VERSION "eCMP INFO-DIV vehicle review 2026-11-03; 125000 bit/s; PSA-RE 67f7581e7622410efdbb29c7eda3b86982b9b450; Apache-2.0"

NS_ :

BS_:

BU_: AAS AMPLI AVP BCM BGP BSG BSI BTA BTEL BTT CDC CMB CRT DIAG_TOOL EDP_C EMF FMUX IC ICSV IDVR IVC_D MATT MDS OVIP PDS_C RAD RBG SDCM VTH WLC

BO_ 438 MDS_Wifi: 8 MDS
 SG_ FlowPadding5 m3 : 63|8@0+ (1,0) [0|255] "raw"  EMF,BTEL,OVIP
 SG_ FirstData6 m1 : 63|8@0+ (1,0) [0|255] "raw"  EMF,BTEL,OVIP
 SG_ UnknownData7 m4 : 63|8@0+ (1,0) [0|255] "raw"  EMF,BTEL,OVIP
 SG_ ConsecutiveData7 m2 : 63|8@0+ (1,0) [0|255] "raw"  EMF,BTEL,OVIP
 SG_ SingleData7 m0 : 63|8@0+ (1,0) [0|255] "raw"  EMF,BTEL,OVIP
 SG_ FlowPadding4 m3 : 55|8@0+ (1,0) [0|255] "raw"  EMF,BTEL,OVIP
 SG_ FirstData5 m1 : 55|8@0+ (1,0) [0|255] "raw"  EMF,BTEL,OVIP
 SG_ UnknownData6 m4 : 55|8@0+ (1,0) [0|255] "raw"  EMF,BTEL,OVIP
 SG_ ConsecutiveData6 m2 : 55|8@0+ (1,0) [0|255] "raw"  EMF,BTEL,OVIP
 SG_ SingleData6 m0 : 55|8@0+ (1,0) [0|255] "raw"  EMF,BTEL,OVIP
 SG_ FlowPadding3 m3 : 47|8@0+ (1,0) [0|255] "raw"  EMF,BTEL,OVIP
 SG_ FirstData4 m1 : 47|8@0+ (1,0) [0|255] "raw"  EMF,BTEL,OVIP
 SG_ UnknownData5 m4 : 47|8@0+ (1,0) [0|255] "raw"  EMF,BTEL,OVIP
 SG_ ConsecutiveData5 m2 : 47|8@0+ (1,0) [0|255] "raw"  EMF,BTEL,OVIP
 SG_ SingleData5 m0 : 47|8@0+ (1,0) [0|255] "raw"  EMF,BTEL,OVIP
 SG_ FlowPadding2 m3 : 39|8@0+ (1,0) [0|255] "raw"  EMF,BTEL,OVIP
 SG_ FirstData3 m1 : 39|8@0+ (1,0) [0|255] "raw"  EMF,BTEL,OVIP
 SG_ UnknownData4 m4 : 39|8@0+ (1,0) [0|255] "raw"  EMF,BTEL,OVIP
 SG_ ConsecutiveData4 m2 : 39|8@0+ (1,0) [0|255] "raw"  EMF,BTEL,OVIP
 SG_ SingleData4 m0 : 39|8@0+ (1,0) [0|255] "raw"  EMF,BTEL,OVIP
 SG_ FlowPadding1 m3 : 31|8@0+ (1,0) [0|255] "raw"  EMF,BTEL,OVIP
 SG_ FirstData2 m1 : 31|8@0+ (1,0) [0|255] "raw"  EMF,BTEL,OVIP
 SG_ UnknownData3 m4 : 31|8@0+ (1,0) [0|255] "raw"  EMF,BTEL,OVIP
 SG_ ConsecutiveData3 m2 : 31|8@0+ (1,0) [0|255] "raw"  EMF,BTEL,OVIP
 SG_ SingleData3 m0 : 31|8@0+ (1,0) [0|255] "raw"  EMF,BTEL,OVIP
 SG_ FirstData1 m1 : 23|8@0+ (1,0) [0|255] "raw"  EMF,BTEL,OVIP
 SG_ UnknownData2 m4 : 23|8@0+ (1,0) [0|255] "raw"  EMF,BTEL,OVIP
 SG_ ConsecutiveData2 m2 : 23|8@0+ (1,0) [0|255] "raw"  EMF,BTEL,OVIP
 SG_ SingleData2 m0 : 23|8@0+ (1,0) [0|255] "raw"  EMF,BTEL,OVIP
 SG_ SeparationTimeRaw m3 : 23|8@0+ (1,0) [0|255] "raw"  EMF,BTEL,OVIP
 SG_ UnknownData1 m4 : 15|8@0+ (1,0) [0|255] "raw"  EMF,BTEL,OVIP
 SG_ ConsecutiveData1 m2 : 15|8@0+ (1,0) [0|255] "raw"  EMF,BTEL,OVIP
 SG_ SingleData1 m0 : 15|8@0+ (1,0) [0|255] "raw"  EMF,BTEL,OVIP
 SG_ BlockSize m3 : 15|8@0+ (1,0) [0|255] "raw"  EMF,BTEL,OVIP
 SG_ UnknownPciLow m4 : 3|4@0+ (1,0) [0|15] "raw"  EMF,BTEL,OVIP
 SG_ FlowStatus m3 : 3|4@0+ (1,0) [0|15] "raw"  EMF,BTEL,OVIP
 SG_ ConsecutiveSequence m2 : 3|4@0+ (1,0) [0|15] "raw"  EMF,BTEL,OVIP
 SG_ FirstFrameLength m1 : 3|12@0+ (1,0) [0|4095] "raw"  EMF,BTEL,OVIP
 SG_ SingleFrameLength m0 : 3|4@0+ (1,0) [0|15] "raw"  EMF,BTEL,OVIP
 SG_ IsoTpFrameType M : 7|4@0+ (1,0) [0|15] ""  EMF,BTEL,OVIP

BO_ 451 MDS_OdiIndicationBuffer: 8 MDS
 SG_ OdiIndicationBuffer : 7|64@0+ (1,0) [0|18446744073709551615] ""  BTEL

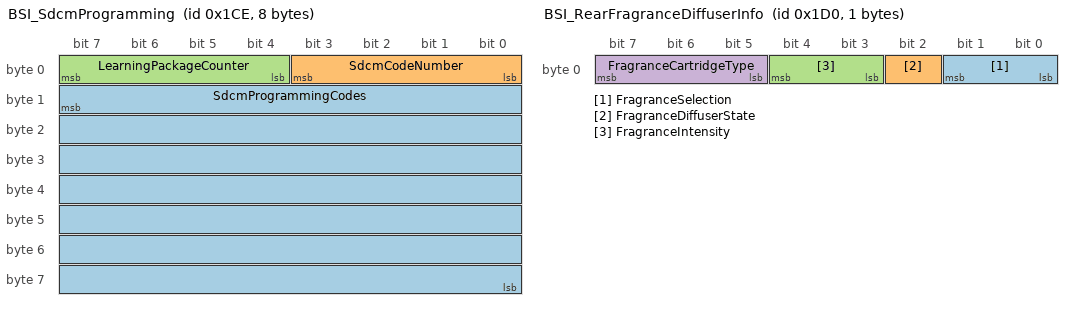
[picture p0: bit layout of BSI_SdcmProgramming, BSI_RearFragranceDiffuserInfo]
BO_ 462 BSI_SdcmProgramming: 8 BSI
 SG_ SdcmProgrammingCodes : 15|56@0+ (1,0) [0|72057594037927935] "raw"  SDCM
 SG_ SdcmCodeNumber : 3|4@0+ (1,0) [0|15] ""  SDCM
 SG_ LearningPackageCounter : 7|4@0+ (1,0) [0|15] ""  SDCM

BO_ 464 BSI_RearFragranceDiffuserInfo: 1 BSI
 SG_ FragranceSelection : 1|2@0+ (1,0) [0|3] ""  OVIP,BTEL,RAD
 SG_ FragranceDiffuserState : 2|1@0+ (1,0) [0|1] ""  OVIP,BTEL,RAD
 SG_ FragranceIntensity : 4|2@0+ (1,0) [0|3] ""  OVIP,BTEL,RAD
 SG_ FragranceCartridgeType : 7|3@0+ (1,0) [0|7] ""  OVIP,BTEL,RAD

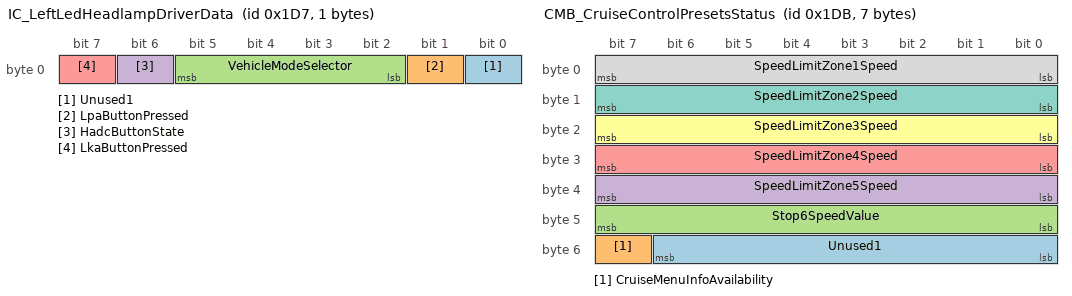
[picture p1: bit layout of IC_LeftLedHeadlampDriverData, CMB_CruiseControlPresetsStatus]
BO_ 471 IC_LeftLedHeadlampDriverData: 1 IC
 SG_ Unused1 : 0|1@0+ (1,0) [0|1] ""  BSI
 SG_ LpaButtonPressed : 1|1@0+ (1,0) [0|1] ""  BSI
 SG_ VehicleModeSelector : 5|4@0+ (1,0) [0|15] ""  BSI
 SG_ HadcButtonState : 6|1@0+ (1,0) [0|1] ""  BSI
 SG_ LkaButtonPressed : 7|1@0+ (1,0) [0|1] ""  BSI

BO_ 475 CMB_CruiseControlPresetsStatus: 7 CMB
 SG_ Unused1 : 54|7@0+ (1,0) [0|127] ""  BSI
 SG_ CruiseMenuInfoAvailability : 55|1@0+ (1,0) [0|1] ""  BSI
 SG_ Stop6SpeedValue : 47|8@0+ (1,0) [0|253] "km/h"  BSI
 SG_ SpeedLimitZone5Speed : 39|8@0+ (1,0) [0|254] "km/h"  BSI
 SG_ SpeedLimitZone4Speed : 31|8@0+ (1,0) [0|254] "km/h"  BSI
 SG_ SpeedLimitZone3Speed : 23|8@0+ (1,0) [0|254] "km/h"  BSI
 SG_ SpeedLimitZone2Speed : 15|8@0+ (1,0) [0|254] "km/h"  BSI
 SG_ SpeedLimitZone1Speed : 7|8@0+ (1,0) [0|254] "km/h"  BSI

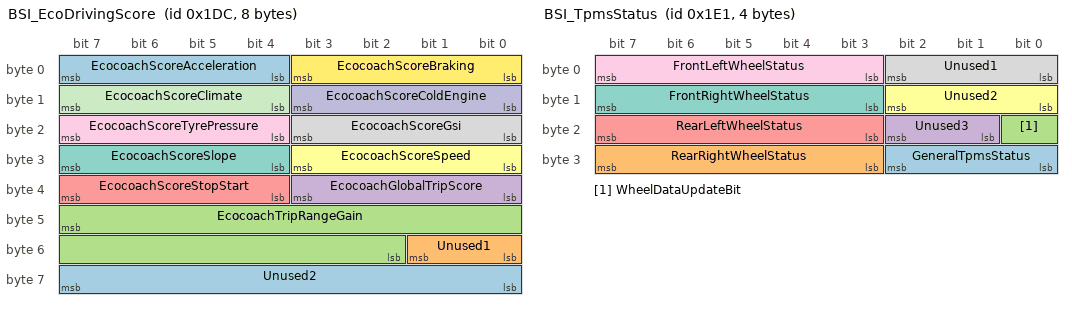
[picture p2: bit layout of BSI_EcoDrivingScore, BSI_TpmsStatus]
BO_ 476 BSI_EcoDrivingScore: 8 BSI
 SG_ Unused2 : 63|8@0+ (1,0) [0|255] ""  OVIP,BTEL
 SG_ Unused1 : 49|2@0+ (1,0) [0|3] ""  OVIP,BTEL
 SG_ EcocoachTripRangeGain : 47|14@0+ (1,-6000) [-6000|10000] "km"  OVIP,BTEL
 SG_ EcocoachGlobalTripScore : 35|4@0+ (1,0) [0|10] ""  OVIP,BTEL
 SG_ EcocoachScoreStopStart : 39|4@0+ (1,0) [0|10] ""  OVIP,BTEL
 SG_ EcocoachScoreSpeed : 27|4@0+ (1,0) [0|10] ""  OVIP,BTEL
 SG_ EcocoachScoreSlope : 31|4@0+ (1,0) [0|10] ""  OVIP,BTEL
 SG_ EcocoachScoreGsi : 19|4@0+ (1,0) [0|10] ""  OVIP,BTEL
 SG_ EcocoachScoreTyrePressure : 23|4@0+ (1,0) [0|10] ""  OVIP,BTEL
 SG_ EcocoachScoreColdEngine : 11|4@0+ (1,0) [0|10] ""  OVIP,BTEL
 SG_ EcocoachScoreClimate : 15|4@0+ (1,0) [0|10] ""  OVIP,BTEL
 SG_ EcocoachScoreBraking : 3|4@0+ (1,0) [0|10] ""  OVIP,BTEL
 SG_ EcocoachScoreAcceleration : 7|4@0+ (1,0) [0|10] ""  OVIP,BTEL

BO_ 480 RAD_RadioConfigStatus: 7 RAD
 SG_ Unused1 : 50|3@0+ (1,0) [0|7] ""  EMF
 SG_ NextListType : 53|3@0+ (1,0) [0|7] ""  EMF
 SG_ DirectoryListOption : 55|2@0+ (1,0) [0|3] ""  EMF
 SG_ PlaylistListOption : 41|2@0+ (1,0) [0|3] ""  EMF
 SG_ GenreListOption : 43|2@0+ (1,0) [0|3] ""  EMF
 SG_ ArtistListOption : 45|2@0+ (1,0) [0|3] ""  EMF
 SG_ News7Option : 47|2@0+ (1,0) [0|3] ""  EMF
 SG_ News6Option : 33|2@0+ (1,0) [0|3] ""  EMF
 SG_ News5Option : 35|2@0+ (1,0) [0|3] ""  EMF
 SG_ News4Option : 37|2@0+ (1,0) [0|3] ""  EMF
 SG_ News3Option : 39|2@0+ (1,0) [0|3] ""  EMF
 SG_ News2Option : 25|2@0+ (1,0) [0|3] ""  EMF
 SG_ News1Option : 27|2@0+ (1,0) [0|3] ""  EMF
 SG_ DabfmOption : 29|2@0+ (1,0) [0|3] ""  EMF
 SG_ RadioNewsOption7Status : 30|1@0+ (1,0) [0|1] ""  EMF
 SG_ RadioNewsOption6Status : 31|1@0+ (1,0) [0|1] ""  EMF
 SG_ RadioNewsOption5Status : 16|1@0+ (1,0) [0|1] ""  EMF
 SG_ RadioNewsOption4Status : 17|1@0+ (1,0) [0|1] ""  EMF
 SG_ RadioNewsOption3Status : 18|1@0+ (1,0) [0|1] ""  EMF
 SG_ RadioNewsOption2Status : 19|1@0+ (1,0) [0|1] ""  EMF
 SG_ RadioNewsOption1Status : 20|1@0+ (1,0) [0|1] ""  EMF
 SG_ RadioDabFmStatus : 21|1@0+ (1,0) [0|1] ""  EMF
 SG_ RadioRdsAfStatus : 22|1@0+ (1,0) [0|1] ""  EMF
 SG_ RadioTextModeStatus : 23|1@0+ (1,0) [0|1] ""  EMF
 SG_ RadioTextOption : 9|2@0+ (1,0) [0|3] ""  EMF
 SG_ RdsAfOption : 11|2@0+ (1,0) [0|3] ""  EMF
 SG_ ShuffleModeStatus : 12|1@0+ (1,0) [0|1] ""  EMF
 SG_ ShuffleAllOption : 14|2@0+ (1,0) [0|3] ""  EMF
 SG_ CdTextModeStatus : 15|1@0+ (1,0) [0|1] ""  EMF
 SG_ CdTextOption : 1|2@0+ (1,0) [0|3] ""  EMF
 SG_ RepeatEnabled : 2|1@0+ (1,0) [0|1] ""  EMF
 SG_ DiscRepeatOption : 4|2@0+ (1,0) [0|3] ""  EMF
 SG_ RandomEnabled : 5|1@0+ (1,0) [0|1] ""  EMF
 SG_ TrackShuffleOption : 7|2@0+ (1,0) [0|3] ""  EMF

BO_ 481 BSI_TpmsStatus: 4 BSI
 SG_ GeneralTpmsStatus : 26|3@0+ (1,0) [0|7] ""  BTEL,MDS,EMF,CMB,MATT,BGP,OVIP,RAD
 SG_ RearRightWheelStatus : 31|5@0+ (1,0) [0|31] ""  BTEL,MDS,EMF,CMB,MATT,BGP,OVIP,RAD
 SG_ WheelDataUpdateBit : 16|1@0+ (1,0) [0|1] ""  BTEL,MDS,EMF,CMB,MATT,BGP,OVIP,RAD
 SG_ Unused3 : 18|2@0+ (1,0) [0|3] ""  BTEL,MDS,EMF,CMB,MATT,BGP,OVIP,RAD
 SG_ RearLeftWheelStatus : 23|5@0+ (1,0) [0|31] ""  BTEL,MDS,EMF,CMB,MATT,BGP,OVIP,RAD
 SG_ Unused2 : 10|3@0+ (1,0) [0|7] ""  BTEL,MDS,EMF,CMB,MATT,BGP,OVIP,RAD
 SG_ FrontRightWheelStatus : 15|5@0+ (1,0) [0|31] ""  BTEL,MDS,EMF,CMB,MATT,BGP,OVIP,RAD
 SG_ Unused1 : 2|3@0+ (1,0) [0|7] ""  BTEL,MDS,EMF,CMB,MATT,BGP,OVIP,RAD
 SG_ FrontLeftWheelStatus : 7|5@0+ (1,0) [0|31] ""  BTEL,MDS,EMF,CMB,MATT,BGP,OVIP,RAD

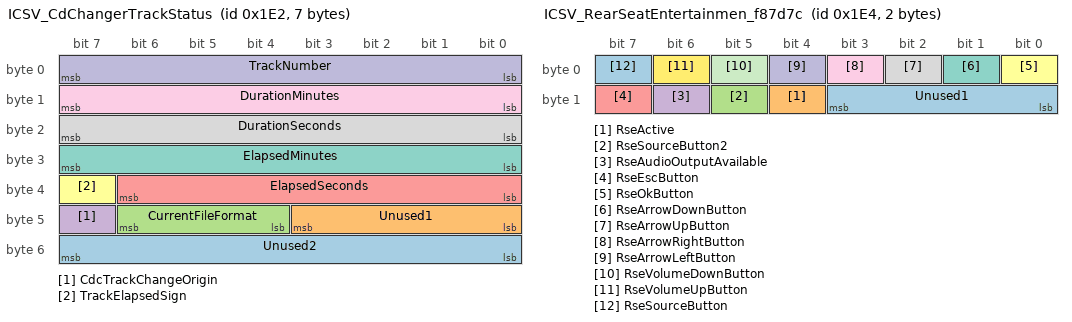
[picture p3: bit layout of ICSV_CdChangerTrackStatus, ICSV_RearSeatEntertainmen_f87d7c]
BO_ 482 ICSV_CdChangerTrackStatus: 7 ICSV
 SG_ Unused2 : 55|8@0+ (1,0) [0|255] ""  BTEL,OVIP,RAD,EMF
 SG_ Unused1 : 43|4@0+ (1,0) [0|15] ""  BTEL,OVIP,RAD,EMF
 SG_ CurrentFileFormat : 46|3@0+ (1,0) [0|7] ""  BTEL,OVIP,RAD,EMF
 SG_ CdcTrackChangeOrigin : 47|1@0+ (1,0) [0|1] ""  BTEL,OVIP,RAD,EMF
 SG_ ElapsedSeconds : 38|7@0+ (1,0) [0|126] ""  BTEL,OVIP,RAD,EMF
 SG_ TrackElapsedSign : 39|1@0+ (1,0) [0|1] ""  BTEL,OVIP,RAD,EMF
 SG_ ElapsedMinutes : 31|8@0+ (1,0) [0|254] ""  BTEL,OVIP,RAD,EMF
 SG_ DurationSeconds : 23|8@0+ (1,0) [0|254] ""  BTEL,OVIP,RAD,EMF
 SG_ DurationMinutes : 15|8@0+ (1,0) [0|254] ""  BTEL,OVIP,RAD,EMF
 SG_ TrackNumber : 7|8@0+ (1,0) [1|254] ""  BTEL,OVIP,RAD,EMF

BO_ 484 ICSV_RearSeatEntertainmen_f87d7c: 2 ICSV
 SG_ Unused1 : 11|4@0+ (1,0) [0|15] ""  BTEL,OVIP
 SG_ RseActive : 12|1@0+ (1,0) [0|1] ""  BTEL,OVIP
 SG_ RseSourceButton2 : 13|1@0+ (1,0) [0|1] ""  BTEL,OVIP
 SG_ RseAudioOutputAvailable : 14|1@0+ (1,0) [0|1] ""  BTEL,OVIP
 SG_ RseEscButton : 15|1@0+ (1,0) [0|1] ""  BTEL,OVIP
 SG_ RseOkButton : 0|1@0+ (1,0) [0|1] ""  BTEL,OVIP
 SG_ RseArrowDownButton : 1|1@0+ (1,0) [0|1] ""  BTEL,OVIP
 SG_ RseArrowUpButton : 2|1@0+ (1,0) [0|1] ""  BTEL,OVIP
 SG_ RseArrowRightButton : 3|1@0+ (1,0) [0|1] ""  BTEL,OVIP
 SG_ RseArrowLeftButton : 4|1@0+ (1,0) [0|1] ""  BTEL,OVIP
 SG_ RseVolumeDownButton : 5|1@0+ (1,0) [0|1] ""  BTEL,OVIP
 SG_ RseVolumeUpButton : 6|1@0+ (1,0) [0|1] ""  BTEL,OVIP
 SG_ RseSourceButton : 7|1@0+ (1,0) [0|1] ""  BTEL,OVIP

BO_ 485 RAD_RadioStatusAudio: 7 RAD
 SG_ Unused1 : 48|1@0+ (1,0) [0|1] ""  EMF,AMPLI
 SG_ SpatialSettingStatus : 49|1@0+ (1,0) [0|1] ""  EMF,AMPLI
 SG_ SpectralSettingStatus : 50|1@0+ (1,0) [0|1] ""  EMF,AMPLI
 SG_ AudioAdjustmentImpossible : 51|1@0+ (1,0) [0|1] ""  EMF,AMPLI
 SG_ PredefinedDistribution : 54|3@0+ (1,0) [0|7] ""  EMF,AMPLI
 SG_ DistributionMenu : 55|1@0+ (1,0) [0|1] ""  EMF,AMPLI
 SG_ DistributionActivationStatus : 41|2@0+ (1,0) [0|3] ""  EMF,AMPLI
 SG_ AmbianceMenu : 42|1@0+ (1,0) [0|1] ""  EMF,AMPLI
 SG_ AmbianceValue : 45|3@0+ (1,0) [0|7] ""  EMF,AMPLI
 SG_ AmbianceActivationStatus : 47|2@0+ (1,0) [0|3] ""  EMF,AMPLI
 SG_ SpeedVolumeControlActive : 33|2@0+ (1,0) [0|3] ""  EMF,AMPLI
 SG_ AutoVolumeStatus : 34|1@0+ (1,0) [0|1] ""  EMF,AMPLI
 SG_ AutoVolumeAdjustment : 35|1@0+ (1,0) [0|1] ""  EMF,AMPLI
 SG_ LoudnessValue : 36|1@0+ (1,0) [0|1] ""  EMF,AMPLI
 SG_ LoudnessActivationStatus : 38|2@0+ (1,0) [0|3] ""  EMF,AMPLI
 SG_ LoudnessMenu : 39|1@0+ (1,0) [0|1] ""  EMF,AMPLI
 SG_ TrebleActivationStatus : 25|2@0+ (1,0) [0|3] ""  EMF,AMPLI
 SG_ TrebleValue : 30|5@0+ (1,-15) [-7|7] ""  EMF,AMPLI
 SG_ TrebleMenu : 31|1@0+ (1,0) [0|1] ""  EMF,AMPLI
 SG_ BassActivationStatus : 17|2@0+ (1,0) [0|3] ""  EMF,AMPLI
 SG_ BassValue : 22|5@0+ (1,-15) [-7|7] ""  EMF,AMPLI
 SG_ BassMenu : 23|1@0+ (1,0) [0|1] ""  EMF,AMPLI
 SG_ FaderActive : 9|2@0+ (1,0) [0|3] ""  EMF,AMPLI
 SG_ RearFrontBalancfValue : 14|5@0+ (1,-15) [-7|7] ""  EMF,AMPLI
 SG_ RearFrontBalancfMenu : 15|1@0+ (1,0) [0|1] ""  EMF,AMPLI
 SG_ BalanceActivationStatus : 1|2@0+ (1,0) [0|3] ""  EMF,AMPLI
 SG_ LeftRightBalanceValue : 6|5@0+ (1,-15) [-7|7] ""  EMF,AMPLI
 SG_ LeftRightBalanceMenu : 7|1@0+ (1,0) [0|1] ""  EMF,AMPLI

BO_ 487 BSI_ArtivAndHybridStatus: 8 BSI
 SG_ Unused2 : 56|1@0+ (1,0) [0|1] ""  ICSV,BTEL,CMB,VTH,MATT,OVIP,MDS,RAD
 SG_ ZtepPowerRatio : 63|7@0+ (1,0) [0|100] "%"  ICSV,BTEL,CMB,VTH,MATT,OVIP,MDS,RAD
 SG_ DaaLateralControlState : 48|1@0+ (1,0) [0|1] ""  ICSV,BTEL,CMB,VTH,MATT,OVIP,MDS,RAD
 SG_ LpaReadyWhenSelected : 49|1@0+ (1,0) [0|1] ""  ICSV,BTEL,CMB,VTH,MATT,OVIP,MDS,RAD
 SG_ LpaStateStatus : 51|2@0+ (1,0) [0|3] ""  ICSV,BTEL,CMB,VTH,MATT,OVIP,MDS,RAD
 SG_ PlugIndicatorLampRequest : 53|2@0+ (1,0) [0|3] ""  ICSV,BTEL,CMB,VTH,MATT,OVIP,MDS,RAD
 SG_ LkaStateStatus : 55|2@0+ (1,0) [0|3] ""  ICSV,BTEL,CMB,VTH,MATT,OVIP,MDS,RAD
 SG_ LkaLeftLineStatus : 41|2@0+ (1,0) [0|3] ""  ICSV,BTEL,CMB,VTH,MATT,OVIP,MDS,RAD
 SG_ LkaRightLineStatus : 43|2@0+ (1,0) [0|3] ""  ICSV,BTEL,CMB,VTH,MATT,OVIP,MDS,RAD
 SG_ DaaLateralControlLevel : 47|4@0+ (1,0) [0|15] ""  ICSV,BTEL,CMB,VTH,MATT,OVIP,MDS,RAD
 SG_ HybridPowerTraction : 24|9@0+ (0.5,-50) [-50|200] "%"  ICSV,BTEL,CMB,VTH,MATT,OVIP,MDS,RAD
 SG_ PowerBatteryHt : 31|7@0+ (1,-50) [-50|50] "kW"  ICSV,BTEL,CMB,VTH,MATT,OVIP,MDS,RAD
 SG_ TivTarget : 23|8@0+ (0.1,0) [0|25.3] "s"  ICSV,BTEL,CMB,VTH,MATT,OVIP,MDS,RAD
 SG_ TivSetpoint : 15|8@0+ (0.1,0) [0|25.3] "s"  ICSV,BTEL,CMB,VTH,MATT,OVIP,MDS,RAD
 SG_ Unused1 : 0|1@0+ (1,0) [0|1] ""  ICSV,BTEL,CMB,VTH,MATT,OVIP,MDS,RAD
 SG_ ArtivTargetDetected : 1|1@0+ (1,0) [0|1] ""  ICSV,BTEL,CMB,VTH,MATT,OVIP,MDS,RAD
 SG_ ArtivAlertAdjustment : 2|1@0+ (1,0) [0|1] ""  ICSV,BTEL,CMB,VTH,MATT,OVIP,MDS,RAD
 SG_ ArtivAlert : 3|1@0+ (1,0) [0|1] ""  ICSV,BTEL,CMB,VTH,MATT,OVIP,MDS,RAD
 SG_ IhmArtivStatus : 5|2@0+ (1,0) [0|3] ""  ICSV,BTEL,CMB,VTH,MATT,OVIP,MDS,RAD
 SG_ ArtivSelectionStatus : 7|2@0+ (1,0) [0|3] ""  ICSV,BTEL,CMB,VTH,MATT,OVIP,MDS,RAD

BO_ 488 ICSV_EngineMeapStatus: 8 ICSV
 SG_ SpeedLimitZone5Speed : 63|8@0+ (1,0) [0|254] "km/h"  CMB,MATT,EMF,BTEL,OVIP,RAD
 SG_ SpeedLimitZone4Speed : 55|8@0+ (1,0) [0|254] "km/h"  CMB,MATT,EMF,BTEL,OVIP,RAD
 SG_ SpeedLimitZone3Speed : 47|8@0+ (1,0) [0|254] "km/h"  CMB,MATT,EMF,BTEL,OVIP,RAD
 SG_ SpeedLimitZone2Speed : 39|8@0+ (1,0) [0|254] "km/h"  CMB,MATT,EMF,BTEL,OVIP,RAD
 SG_ SpeedLimitZone1Speed : 31|8@0+ (1,0) [0|254] "km/h"  CMB,MATT,EMF,BTEL,OVIP,RAD
 SG_ SpeedLimitZone5State : 16|1@0+ (1,0) [0|1] ""  CMB,MATT,EMF,BTEL,OVIP,RAD
 SG_ SpeedLimitZone4State : 17|1@0+ (1,0) [0|1] ""  CMB,MATT,EMF,BTEL,OVIP,RAD
 SG_ SpeedLimitZone3State : 18|1@0+ (1,0) [0|1] ""  CMB,MATT,EMF,BTEL,OVIP,RAD
 SG_ SpeedLimitZone2State : 19|1@0+ (1,0) [0|1] ""  CMB,MATT,EMF,BTEL,OVIP,RAD
 SG_ SpeedLimitZone1State : 20|1@0+ (1,0) [0|1] ""  CMB,MATT,EMF,BTEL,OVIP,RAD
 SG_ CruiseLimiterProgramRecal_34492a : 21|1@0+ (1,0) [0|1] ""  CMB,MATT,EMF,BTEL,OVIP,RAD
 SG_ SpeedLimitMainState : 22|1@0+ (1,0) [0|1] ""  CMB,MATT,EMF,BTEL,OVIP,RAD
 SG_ CruiseMenuInfoAvailability : 23|1@0+ (1,0) [0|1] ""  CMB,MATT,EMF,BTEL,OVIP,RAD
 SG_ ThermalPrecondClock : 3|12@0+ (1,0) [0|1439] "min"  CMB,MATT,EMF,BTEL,OVIP,RAD
 SG_ ThermalPrecondActive : 4|1@0+ (1,0) [0|1] ""  CMB,MATT,EMF,BTEL,OVIP,RAD
 SG_ ThermalPrecondType : 5|1@0+ (1,0) [0|1] ""  CMB,MATT,EMF,BTEL,OVIP,RAD
 SG_ CruiseLimiterProgramRecal_1d4300 : 6|1@0+ (1,0) [0|1] ""  CMB,MATT,EMF,BTEL,OVIP,RAD
 SG_ Unused1 : 7|1@0+ (1,0) [0|1] ""  CMB,MATT,EMF,BTEL,OVIP,RAD

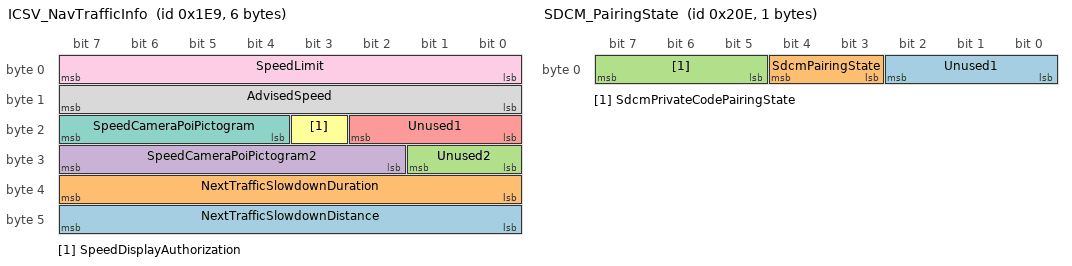
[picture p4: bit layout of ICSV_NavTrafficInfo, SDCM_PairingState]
BO_ 489 ICSV_NavTrafficInfo: 6 ICSV
 SG_ NextTrafficSlowdownDistance : 47|8@0+ (1,0) [0|254] "km"  CMB,MATT,BSI
 SG_ NextTrafficSlowdownDuration : 39|8@0+ (1,0) [0|254] "min"  CMB,MATT,BSI
 SG_ Unused2 : 25|2@0+ (1,0) [0|3] ""  CMB,MATT,BSI
 SG_ SpeedCameraPoiPictogram2 : 31|6@0+ (1,0) [0|63] ""  CMB,MATT,BSI
 SG_ Unused1 : 18|3@0+ (1,0) [0|7] ""  CMB,MATT,BSI
 SG_ SpeedDisplayAuthorization : 19|1@0+ (1,0) [0|1] ""  CMB,MATT,BSI
 SG_ SpeedCameraPoiPictogram : 23|4@0+ (1,0) [0|15] ""  CMB,MATT,BSI
 SG_ AdvisedSpeed : 15|8@0+ (1,0) [0|199] "km/h"  CMB,MATT,BSI
 SG_ SpeedLimit : 7|8@0+ (1,0) [0|199] "km/h"  CMB,MATT,BSI

BO_ 515 MDS_OdiDynamicDataBuffer: 8 MDS
 SG_ OdiDynamicDataBuffer : 7|64@0+ (1,0) [0|18446744073709551615] ""  BTEL

BO_ 526 SDCM_PairingState: 1 SDCM
 SG_ Unused1 : 2|3@0+ (1,0) [0|7] ""  BSI
 SG_ SdcmPairingState : 4|2@0+ (1,0) [0|3] ""  BSI
 SG_ SdcmPrivateCodePairingState : 7|3@0+ (1,0) [0|7] ""  BSI

BO_ 535 IC_OdometerStatus: 8 IC
 SG_ ClusterAppearance : 63|8@0+ (1,0) [1|254] ""  ICSV,AAS,BSI,VTH,MATT,OVIP,RAD
 SG_ AmbientLightingLevel : 50|3@0+ (1,0) [0|7] ""  ICSV,AAS,BSI,VTH,MATT,OVIP,RAD
 SG_ AmbientLightButtonStatus : 51|1@0+ (1,0) [0|1] ""  ICSV,AAS,BSI,VTH,MATT,OVIP,RAD
 SG_ MediaDisplayFault : 52|1@0+ (1,0) [0|1] ""  ICSV,AAS,BSI,VTH,MATT,OVIP,RAD
 SG_ DynamicModeChangeRequest : 53|1@0+ (1,0) [0|1] ""  ICSV,AAS,BSI,VTH,MATT,OVIP,RAD
 SG_ EcoModeButtonPress : 54|1@0+ (1,0) [0|1] ""  ICSV,AAS,BSI,VTH,MATT,OVIP,RAD
 SG_ SttButtonStatus : 55|1@0+ (1,0) [0|1] ""  ICSV,AAS,BSI,VTH,MATT,OVIP,RAD
 SG_ SpeedDisplayedOnCmb : 47|8@0+ (1,0) [0|254] ""  ICSV,AAS,BSI,VTH,MATT,OVIP,RAD
 SG_ ScpStateChangeRequest : 32|1@0+ (1,0) [0|1] ""  ICSV,AAS,BSI,VTH,MATT,OVIP,RAD
 SG_ MediaDisplayFaultArc : 33|1@0+ (1,0) [0|1] ""  ICSV,AAS,BSI,VTH,MATT,OVIP,RAD
 SG_ ArtivMinusButtonStatus : 34|1@0+ (1,0) [0|1] ""  ICSV,AAS,BSI,VTH,MATT,OVIP,RAD
 SG_ ArtivPlusButtonStatus : 35|1@0+ (1,0) [0|1] ""  ICSV,AAS,BSI,VTH,MATT,OVIP,RAD
 SG_ MatrixMaintenanceResetRequest : 36|1@0+ (1,0) [0|1] ""  ICSV,AAS,BSI,VTH,MATT,OVIP,RAD
 SG_ ArtivButtonStatus : 37|1@0+ (1,0) [0|1] ""  ICSV,AAS,BSI,VTH,MATT,OVIP,RAD
 SG_ RequestPtcOn : 38|1@0+ (1,0) [0|1] ""  ICSV,AAS,BSI,VTH,MATT,OVIP,RAD
 SG_ TpmsButtonInput : 39|1@0+ (1,0) [0|1] ""  ICSV,AAS,BSI,VTH,MATT,OVIP,RAD
 SG_ ResetTotal2 : 24|1@0+ (1,0) [0|1] ""  ICSV,AAS,BSI,VTH,MATT,OVIP,RAD
 SG_ AcCompressorMaxCapacityRequest : 25|1@0+ (1,0) [0|1] ""  ICSV,AAS,BSI,VTH,MATT,OVIP,RAD
 SG_ MpdButtonStatus : 26|1@0+ (1,0) [0|1] ""  ICSV,AAS,BSI,VTH,MATT,OVIP,RAD
 SG_ SamButtonStatus : 27|1@0+ (1,0) [0|1] ""  ICSV,AAS,BSI,VTH,MATT,OVIP,RAD
 SG_ RearWindowHeaterButtonStatus : 28|1@0+ (1,0) [0|1] ""  ICSV,AAS,BSI,VTH,MATT,OVIP,RAD
 SG_ AcOnButtonStatus : 29|1@0+ (1,0) [0|1] ""  ICSV,AAS,BSI,VTH,MATT,OVIP,RAD
 SG_ SideTrajectoryButtonStatus : 30|1@0+ (1,0) [0|1] ""  ICSV,AAS,BSI,VTH,MATT,OVIP,RAD
 SG_ CafrButtonInput : 31|1@0+ (1,0) [0|1] ""  ICSV,AAS,BSI,VTH,MATT,OVIP,RAD
 SG_ Unused1 : 17|2@0+ (1,0) [0|3] ""  ICSV,AAS,BSI,VTH,MATT,OVIP,RAD
 SG_ FilteredPartialStatus : 18|1@0+ (1,0) [0|1] ""  ICSV,AAS,BSI,VTH,MATT,OVIP,RAD
 SG_ RequestMatrixCheck : 19|1@0+ (1,0) [0|1] ""  ICSV,AAS,BSI,VTH,MATT,OVIP,RAD
 SG_ AmvarButtonStatus : 20|1@0+ (1,0) [0|1] ""  ICSV,AAS,BSI,VTH,MATT,OVIP,RAD
 SG_ ChildSafetyLockStatus : 21|1@0+ (1,0) [0|1] ""  ICSV,AAS,BSI,VTH,MATT,OVIP,RAD
 SG_ EspButtonStatus : 22|1@0+ (1,0) [0|1] ""  ICSV,AAS,BSI,VTH,MATT,OVIP,RAD
 SG_ AasButtonStatus : 23|1@0+ (1,0) [0|1] ""  ICSV,AAS,BSI,VTH,MATT,OVIP,RAD
 SG_ DistanceUnit : 8|1@0+ (1,0) [0|1] ""  ICSV,AAS,BSI,VTH,MATT,OVIP,RAD
 SG_ ResetPartial : 9|1@0+ (1,0) [0|1] ""  ICSV,AAS,BSI,VTH,MATT,OVIP,RAD
 SG_ ResetTotal1 : 10|1@0+ (1,0) [0|1] ""  ICSV,AAS,BSI,VTH,MATT,OVIP,RAD
 SG_ ClusterFault : 11|1@0+ (1,0) [0|1] ""  ICSV,AAS,BSI,VTH,MATT,OVIP,RAD
 SG_ AutoCheck : 12|1@0+ (1,0) [0|1] ""  ICSV,AAS,BSI,VTH,MATT,OVIP,RAD
 SG_ CheckRequested : 13|1@0+ (1,0) [0|1] ""  ICSV,AAS,BSI,VTH,MATT,OVIP,RAD
 SG_ AirbagFaultStatus : 15|2@0+ (1,0) [0|3] ""  ICSV,AAS,BSI,VTH,MATT,OVIP,RAD
 SG_ AirbagInhibitionStatus : 1|2@0+ (1,0) [0|3] ""  ICSV,AAS,BSI,VTH,MATT,OVIP,RAD
 SG_ MaintenanceResetRequest : 2|1@0+ (1,0) [0|1] ""  ICSV,AAS,BSI,VTH,MATT,OVIP,RAD
 SG_ DarkStatus : 3|1@0+ (1,0) [0|1] ""  ICSV,AAS,BSI,VTH,MATT,OVIP,RAD
 SG_ Luminosity : 7|4@0+ (1,0) [0|15] ""  ICSV,AAS,BSI,VTH,MATT,OVIP,RAD

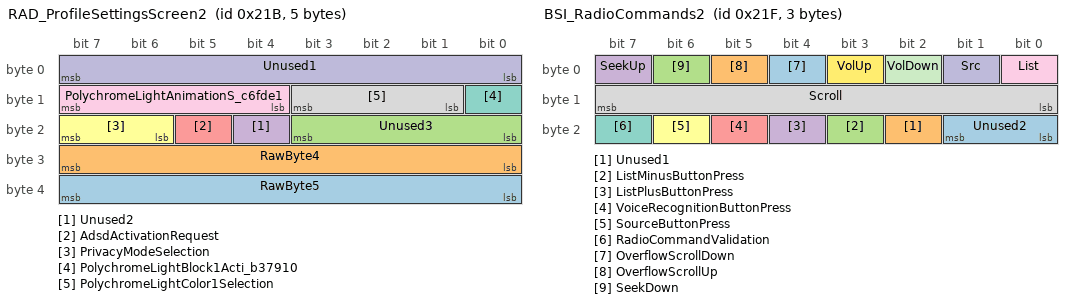
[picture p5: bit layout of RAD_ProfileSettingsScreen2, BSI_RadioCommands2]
BO_ 539 RAD_ProfileSettingsScreen2: 5 RAD
 SG_ RawByte5 : 39|8@0+ (1,0) [0|255] "raw" Vector__XXX
 SG_ RawByte4 : 31|8@0+ (1,0) [0|255] "raw" Vector__XXX
 SG_ Unused3 : 19|4@0+ (1,0) [0|15] ""  BSI
 SG_ Unused2 : 20|1@0+ (1,0) [0|1] ""  BSI
 SG_ AdsdActivationRequest : 21|1@0+ (1,0) [0|1] ""  BSI
 SG_ PrivacyModeSelection : 23|2@0+ (1,0) [0|3] ""  BSI
 SG_ PolychromeLightBlock1Acti_b37910 : 8|1@0+ (1,0) [0|1] ""  BSI
 SG_ PolychromeLightColor1Selection : 11|3@0+ (1,0) [0|7] ""  BSI
 SG_ PolychromeLightAnimationS_c6fde1 : 15|4@0+ (1,0) [0|15] ""  BSI
 SG_ Unused1 : 7|8@0+ (1,0) [0|255] ""  BSI

BO_ 543 BSI_RadioCommands2: 3 BSI
 SG_ Unused2 : 17|2@0+ (1,0) [0|3] ""  BTEL,RAD,EMF,ICSV,OVIP
 SG_ Unused1 : 18|1@0+ (1,0) [0|1] ""  BTEL,RAD,EMF,ICSV,OVIP
 SG_ ListMinusButtonPress : 19|1@0+ (1,0) [0|1] ""  BTEL,RAD,EMF,ICSV,OVIP
 SG_ ListPlusButtonPress : 20|1@0+ (1,0) [0|1] ""  BTEL,RAD,EMF,ICSV,OVIP
 SG_ VoiceRecognitionButtonPress : 21|1@0+ (1,0) [0|1] ""  BTEL,RAD,EMF,ICSV,OVIP
 SG_ SourceButtonPress : 22|1@0+ (1,0) [0|1] ""  BTEL,RAD,EMF,ICSV,OVIP
 SG_ RadioCommandValidation : 23|1@0+ (1,0) [0|1] ""  BTEL,RAD,EMF,ICSV,OVIP
 SG_ Scroll : 15|8@0- (1,0) [-128|127] ""  BTEL,RAD,EMF,ICSV,OVIP
 SG_ List : 0|1@0+ (1,0) [0|1] ""  BTEL,RAD,EMF,ICSV,OVIP
 SG_ Src : 1|1@0+ (1,0) [0|1] ""  BTEL,RAD,EMF,ICSV,OVIP
 SG_ VolDown : 2|1@0+ (1,0) [0|1] ""  BTEL,RAD,EMF,ICSV,OVIP
 SG_ VolUp : 3|1@0+ (1,0) [0|1] ""  BTEL,RAD,EMF,ICSV,OVIP
 SG_ OverflowScrollDown : 4|1@0+ (1,0) [0|1] ""  BTEL,RAD,EMF,ICSV,OVIP
 SG_ OverflowScrollUp : 5|1@0+ (1,0) [0|1] ""  BTEL,RAD,EMF,ICSV,OVIP
 SG_ SeekDown : 6|1@0+ (1,0) [0|1] ""  BTEL,RAD,EMF,ICSV,OVIP
 SG_ SeekUp : 7|1@0+ (1,0) [0|1] ""  BTEL,RAD,EMF,ICSV,OVIP

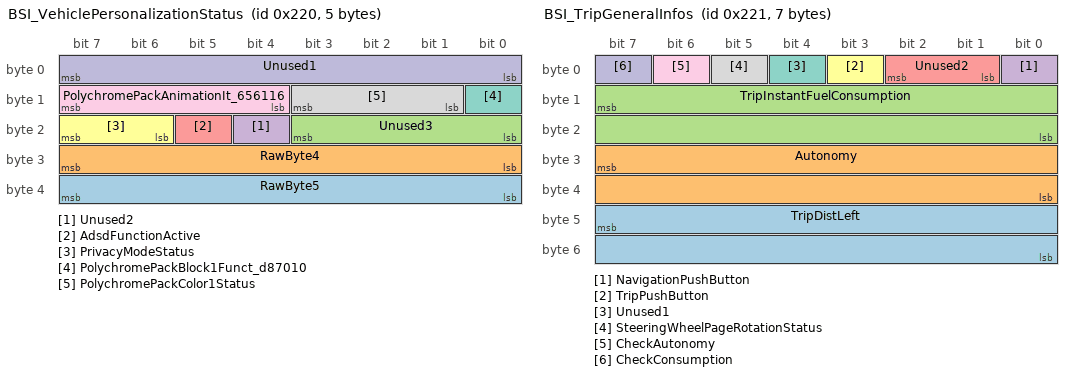
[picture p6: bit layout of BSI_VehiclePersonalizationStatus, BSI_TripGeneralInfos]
BO_ 544 BSI_VehiclePersonalizationStatus: 5 BSI
 SG_ RawByte5 : 39|8@0+ (1,0) [0|255] "raw" Vector__XXX
 SG_ RawByte4 : 31|8@0+ (1,0) [0|255] "raw" Vector__XXX
 SG_ Unused3 : 19|4@0+ (1,0) [0|15] ""  EMF,BTEL,MATT,MDS,CMB,VTH,RAD,ICSV,BGP,FMUX,OVIP
 SG_ Unused2 : 20|1@0+ (1,0) [0|1] ""  EMF,BTEL,MATT,MDS,CMB,VTH,RAD,ICSV,BGP,FMUX,OVIP
 SG_ AdsdFunctionActive : 21|1@0+ (1,0) [0|1] ""  EMF,BTEL,MATT,MDS,CMB,VTH,RAD,ICSV,BGP,FMUX,OVIP
 SG_ PrivacyModeStatus : 23|2@0+ (1,0) [0|3] ""  EMF,BTEL,MATT,MDS,CMB,VTH,RAD,ICSV,BGP,FMUX,OVIP
 SG_ PolychromePackBlock1Funct_d87010 : 8|1@0+ (1,0) [0|1] ""  EMF,BTEL,MATT,MDS,CMB,VTH,RAD,ICSV,BGP,FMUX,OVIP
 SG_ PolychromePackColor1Status : 11|3@0+ (1,0) [0|7] ""  EMF,BTEL,MATT,MDS,CMB,VTH,RAD,ICSV,BGP,FMUX,OVIP
 SG_ PolychromePackAnimationIt_656116 : 15|4@0+ (1,0) [0|15] ""  EMF,BTEL,MATT,MDS,CMB,VTH,RAD,ICSV,BGP,FMUX,OVIP
 SG_ Unused1 : 7|8@0+ (1,0) [0|255] ""  EMF,BTEL,MATT,MDS,CMB,VTH,RAD,ICSV,BGP,FMUX,OVIP

BO_ 545 BSI_TripGeneralInfos: 7 BSI
 SG_ TripDistLeft : 47|16@0+ (0.1,0) [0|6000] "km"  ICSV,EMF,CMB,MDS,BTEL,MATT,BGP,RAD,OVIP
 SG_ Autonomy : 31|16@0+ (1,0) [0|2000] "km"  ICSV,EMF,CMB,MDS,BTEL,MATT,BGP,RAD,OVIP
 SG_ TripInstantFuelConsumption : 15|16@0+ (0.1,0) [0|30] "L/100km"  ICSV,EMF,CMB,MDS,BTEL,MATT,BGP,RAD,OVIP
 SG_ NavigationPushButton : 0|1@0+ (1,0) [0|1] ""  ICSV,EMF,CMB,MDS,BTEL,MATT,BGP,RAD,OVIP
 SG_ Unused2 : 2|2@0+ (1,0) [0|3] ""  ICSV,EMF,CMB,MDS,BTEL,MATT,BGP,RAD,OVIP
 SG_ TripPushButton : 3|1@0+ (1,0) [0|1] ""  ICSV,EMF,CMB,MDS,BTEL,MATT,BGP,RAD,OVIP
 SG_ Unused1 : 4|1@0+ (1,0) [0|1] ""  ICSV,EMF,CMB,MDS,BTEL,MATT,BGP,RAD,OVIP
 SG_ SteeringWheelPageRotationStatus : 5|1@0+ (1,0) [0|1] ""  ICSV,EMF,CMB,MDS,BTEL,MATT,BGP,RAD,OVIP
 SG_ CheckAutonomy : 6|1@0+ (1,0) [0|1] ""  ICSV,EMF,CMB,MDS,BTEL,MATT,BGP,RAD,OVIP
 SG_ CheckConsumption : 7|1@0+ (1,0) [0|1] ""  ICSV,EMF,CMB,MDS,BTEL,MATT,BGP,RAD,OVIP

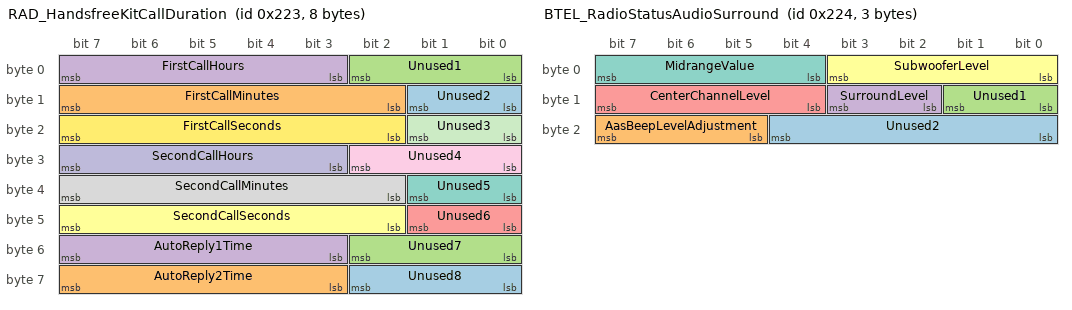
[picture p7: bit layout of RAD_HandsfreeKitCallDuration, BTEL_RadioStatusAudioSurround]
BO_ 547 RAD_HandsfreeKitCallDuration: 8 RAD
 SG_ Unused8 : 58|3@0+ (1,0) [0|7] ""  EMF
 SG_ AutoReply2Time : 63|5@0+ (1,0) [0|30] "s"  EMF
 SG_ Unused7 : 50|3@0+ (1,0) [0|7] ""  EMF
 SG_ AutoReply1Time : 55|5@0+ (1,0) [0|30] "s"  EMF
 SG_ Unused6 : 41|2@0+ (1,0) [0|3] ""  EMF
 SG_ SecondCallSeconds : 47|6@0+ (1,0) [0|59] "s"  EMF
 SG_ Unused5 : 33|2@0+ (1,0) [0|3] ""  EMF
 SG_ SecondCallMinutes : 39|6@0+ (1,0) [0|59] "min"  EMF
 SG_ Unused4 : 26|3@0+ (1,0) [0|7] ""  EMF
 SG_ SecondCallHours : 31|5@0+ (1,0) [0|30] "h"  EMF
 SG_ Unused3 : 17|2@0+ (1,0) [0|3] ""  EMF
 SG_ FirstCallSeconds : 23|6@0+ (1,0) [0|59] "s"  EMF
 SG_ Unused2 : 9|2@0+ (1,0) [0|3] ""  EMF
 SG_ FirstCallMinutes : 15|6@0+ (1,0) [0|59] "min"  EMF
 SG_ Unused1 : 2|3@0+ (1,0) [0|7] ""  EMF
 SG_ FirstCallHours : 7|5@0+ (1,0) [0|30] "h"  EMF

BO_ 548 BTEL_RadioStatusAudioSurround: 3 BTEL
 SG_ Unused2 : 20|5@0+ (1,0) [0|31] ""  ICSV,AMPLI
 SG_ AasBeepLevelAdjustment : 23|3@0+ (4,-16) [-8|8] "dB(A)"  ICSV,AMPLI
 SG_ Unused1 : 9|2@0+ (1,0) [0|3] ""  ICSV,AMPLI
 SG_ SurroundLevel : 11|2@0+ (1,0) [0|3] ""  ICSV,AMPLI
 SG_ CenterChannelLevel : 15|4@0+ (1,-7) [-7|7] ""  ICSV,AMPLI
 SG_ SubwooferLevel : 3|4@0+ (1,-7) [-7|7] ""  ICSV,AMPLI
 SG_ MidrangeValue : 7|4@0+ (1,-7) [-7|7] ""  ICSV,AMPLI

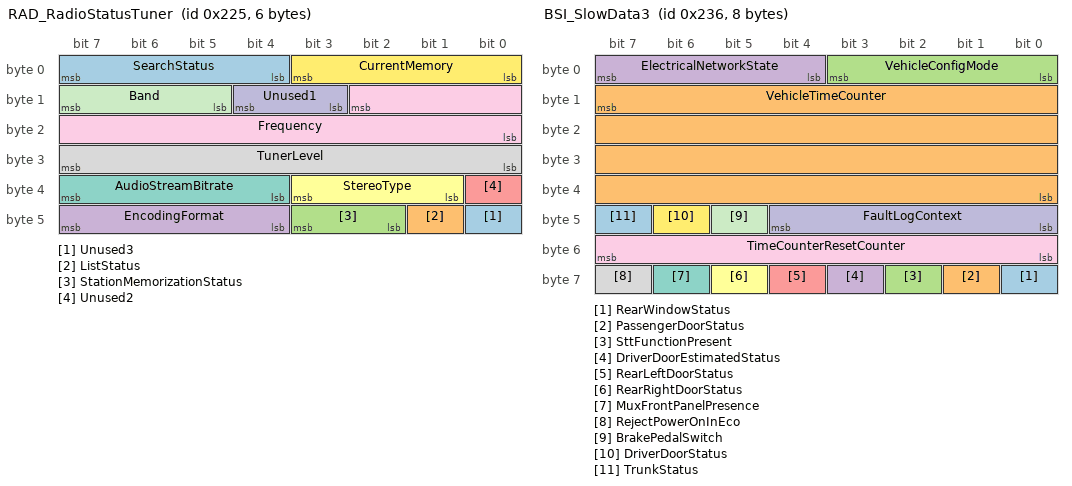
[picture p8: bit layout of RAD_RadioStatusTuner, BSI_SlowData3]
BO_ 549 RAD_RadioStatusTuner: 6 RAD
 SG_ Unused3 : 40|1@0+ (1,0) [0|1] ""  CRT,FMUX,EMF
 SG_ ListStatus : 41|1@0+ (1,0) [0|1] ""  CRT,FMUX,EMF
 SG_ StationMemorizationStatus : 43|2@0+ (1,0) [0|3] ""  CRT,FMUX,EMF
 SG_ EncodingFormat : 47|4@0+ (1,0) [0|15] ""  CRT,FMUX,EMF
 SG_ Unused2 : 32|1@0+ (1,0) [0|1] ""  CRT,FMUX,EMF
 SG_ StereoType : 35|3@0+ (1,0) [0|7] ""  CRT,FMUX,EMF
 SG_ AudioStreamBitrate : 39|4@0+ (1,0) [0|15] ""  CRT,FMUX,EMF
 SG_ TunerLevel : 31|8@0+ (1,0) [0|100] "%"  CRT,FMUX,EMF
 SG_ Frequency : 10|11@0+ (1,0) [0|2045] "frequency step"  CRT,FMUX,EMF
 SG_ Unused1 : 12|2@0+ (1,0) [0|3] ""  CRT,FMUX,EMF
 SG_ Band : 15|3@0+ (1,0) [0|7] ""  CRT,FMUX,EMF
 SG_ CurrentMemory : 3|4@0+ (1,0) [0|15] ""  CRT,FMUX,EMF
 SG_ SearchStatus : 7|4@0+ (1,0) [0|15] ""  CRT,FMUX,EMF

BO_ 551 BSI_PushButtonLedControl: 8 BSI
 SG_ RawByte8 : 63|8@0+ (1,0) [0|255] "raw" Vector__XXX
 SG_ Unused1 : 54|7@0+ (1,0) [0|127] ""  ICSV,FMUX,BTEL,CMB,OVIP,MDS,RAD
 SG_ AvasSoundEmissionRequest : 55|1@0+ (1,0) [0|1] ""  ICSV,FMUX,BTEL,CMB,OVIP,MDS,RAD
 SG_ EnergyRecoverPushLed : 40|1@0+ (1,0) [0|1] ""  ICSV,FMUX,BTEL,CMB,OVIP,MDS,RAD
 SG_ AvasPushLed : 41|1@0+ (1,0) [0|1] ""  ICSV,FMUX,BTEL,CMB,OVIP,MDS,RAD
 SG_ EcoModePushLedState : 43|2@0+ (1,0) [0|3] ""  ICSV,FMUX,BTEL,CMB,OVIP,MDS,RAD
 SG_ NightVisionPushLedControl : 45|2@0+ (1,0) [0|3] ""  ICSV,FMUX,BTEL,CMB,OVIP,MDS,RAD
 SG_ LpaPushLedControl : 47|2@0+ (1,0) [0|3] ""  ICSV,FMUX,BTEL,CMB,OVIP,MDS,RAD
 SG_ WelcomeLightLedMode : 32|1@0+ (1,0) [0|1] ""  ICSV,FMUX,BTEL,CMB,OVIP,MDS,RAD
 SG_ AutoWipeLedFeedback : 34|2@0+ (1,0) [0|3] ""  ICSV,FMUX,BTEL,CMB,OVIP,MDS,RAD
 SG_ HadcPushLedRequest : 35|1@0+ (1,0) [0|1] ""  ICSV,FMUX,BTEL,CMB,OVIP,MDS,RAD
 SG_ LkaPushLedControl : 37|2@0+ (1,0) [0|3] ""  ICSV,FMUX,BTEL,CMB,OVIP,MDS,RAD
 SG_ FunctionSelectPushLed : 39|2@0+ (1,0) [0|3] ""  ICSV,FMUX,BTEL,CMB,OVIP,MDS,RAD
 SG_ DynamicPackLedRequest : 25|2@0+ (1,0) [0|3] ""  ICSV,FMUX,BTEL,CMB,OVIP,MDS,RAD
 SG_ StartStopPushLedControl : 27|2@0+ (1,0) [0|3] ""  ICSV,FMUX,BTEL,CMB,OVIP,MDS,RAD
 SG_ CafrPushLedControl : 28|1@0+ (1,0) [0|1] ""  ICSV,FMUX,BTEL,CMB,OVIP,MDS,RAD
 SG_ ArtivPushLedControl : 30|2@0+ (1,0) [0|3] ""  ICSV,FMUX,BTEL,CMB,OVIP,MDS,RAD
 SG_ RecyclAirEtVmf : 31|1@0+ (1,0) [0|1] ""  ICSV,FMUX,BTEL,CMB,OVIP,MDS,RAD
 SG_ BlindSpotMonitoringPushLe_c23e79 : 17|2@0+ (1,0) [0|3] ""  ICSV,FMUX,BTEL,CMB,OVIP,MDS,RAD
 SG_ AirConditioningShutterControl : 19|2@0+ (1,0) [0|3] ""  ICSV,FMUX,BTEL,CMB,OVIP,MDS,RAD
 SG_ PetrolOrDieselInformation : 21|2@0+ (1,0) [0|3] ""  ICSV,FMUX,BTEL,CMB,OVIP,MDS,RAD
 SG_ StopAndStartPushLedControl : 23|2@0+ (1,0) [0|3] ""  ICSV,FMUX,BTEL,CMB,OVIP,MDS,RAD
 SG_ AcPushLedControl : 9|2@0+ (1,0) [0|3] ""  ICSV,FMUX,BTEL,CMB,OVIP,MDS,RAD
 SG_ RearWindowHeatingPushLedControl : 11|2@0+ (1,0) [0|3] ""  ICSV,FMUX,BTEL,CMB,OVIP,MDS,RAD
 SG_ SideTrajectoryMonitoringP_7717a7 : 13|2@0+ (1,0) [0|3] ""  ICSV,FMUX,BTEL,CMB,OVIP,MDS,RAD
 SG_ AuxiliaryElectricBrakePus_1445da : 15|2@0+ (1,0) [0|3] ""  ICSV,FMUX,BTEL,CMB,OVIP,MDS,RAD
 SG_ SportAmvarPushLedControl : 1|2@0+ (1,0) [0|3] ""  ICSV,FMUX,BTEL,CMB,OVIP,MDS,RAD
 SG_ ChildLockPushLedControl : 3|2@0+ (1,0) [0|3] ""  ICSV,FMUX,BTEL,CMB,OVIP,MDS,RAD
 SG_ EspPushLedControl : 5|2@0+ (1,0) [0|3] ""  ICSV,FMUX,BTEL,CMB,OVIP,MDS,RAD
 SG_ ParkingAidPushLedControl : 7|2@0+ (1,0) [0|3] ""  ICSV,FMUX,BTEL,CMB,OVIP,MDS,RAD

BO_ 552 ICSV_EasyMoveData: 8 ICSV
 SG_ CruiseSpeedProgrammingAut_3eaf80 : 56|1@0+ (1,0) [0|1] ""  EMF,OVIP,BTEL,MDS,AVP,MATT,CMB,VTH,RAD
 SG_ ColumnSwitchMemButtonStatus : 57|1@0+ (1,0) [0|1] ""  EMF,OVIP,BTEL,MDS,AVP,MATT,CMB,VTH,RAD
 SG_ TivSetpointPageToggleRequest : 59|2@0+ (1,0) [0|3] ""  EMF,OVIP,BTEL,MDS,AVP,MATT,CMB,VTH,RAD
 SG_ AdaptiveCruiseControlHmiStatus : 63|4@0+ (1,0) [0|15] ""  EMF,OVIP,BTEL,MDS,AVP,MATT,CMB,VTH,RAD
 SG_ AdaptiveCruiseControlSpee_17c8ea : 46|15@0+ (0.01,0) [0|254] "km/h"  EMF,OVIP,BTEL,MDS,AVP,MATT,CMB,VTH,RAD
 SG_ AccAutoHoldStatus : 47|1@0+ (1,0) [0|1] ""  EMF,OVIP,BTEL,MDS,AVP,MATT,CMB,VTH,RAD
 SG_ AccTivTimeSetpoint : 37|6@0+ (0.1,0) [0|6.1] "s"  EMF,OVIP,BTEL,MDS,AVP,MATT,CMB,VTH,RAD
 SG_ CruiseSetpointPageRequest : 39|2@0+ (1,0) [0|3] ""  EMF,OVIP,BTEL,MDS,AVP,MATT,CMB,VTH,RAD
 SG_ AccTivTime : 29|6@0+ (0.1,0) [0|6.1] "s"  EMF,OVIP,BTEL,MDS,AVP,MATT,CMB,VTH,RAD
 SG_ AccTivSetpointAdjustmentStatus : 30|1@0+ (1,0) [0|1] ""  EMF,OVIP,BTEL,MDS,AVP,MATT,CMB,VTH,RAD
 SG_ CruiseControlAvailable : 31|1@0+ (1,0) [0|1] ""  EMF,OVIP,BTEL,MDS,AVP,MATT,CMB,VTH,RAD
 SG_ CruiseSpeedSetpointAdjust_cbc66f : 16|1@0+ (1,0) [0|1] ""  EMF,OVIP,BTEL,MDS,AVP,MATT,CMB,VTH,RAD
 SG_ AccTargetPresence : 17|1@0+ (1,0) [0|1] ""  EMF,OVIP,BTEL,MDS,AVP,MATT,CMB,VTH,RAD
 SG_ TentActLvvRvv : 18|1@0+ (1,0) [0|1] ""  EMF,OVIP,BTEL,MDS,AVP,MATT,CMB,VTH,RAD
 SG_ EtatFonctLvvRvv : 21|3@0+ (1,0) [0|7] ""  EMF,OVIP,BTEL,MDS,AVP,MATT,CMB,VTH,RAD
 SG_ FonctActLvvRvv : 23|2@0+ (1,0) [0|3] ""  EMF,OVIP,BTEL,MDS,AVP,MATT,CMB,VTH,RAD
 SG_ CruiseControlSpeed : 7|16@0+ (0.01,0) [0|254] "km/h"  EMF,OVIP,BTEL,MDS,AVP,MATT,CMB,VTH,RAD

BO_ 553 ICSV_GearboxDynamicDataV2: 8 ICSV
 SG_ FlowPadding5 m3 : 63|8@0+ (1,0) [0|255] "raw"  MATT,CMB
 SG_ FirstData6 m1 : 63|8@0+ (1,0) [0|255] "raw"  MATT,CMB
 SG_ UnknownData7 m4 : 63|8@0+ (1,0) [0|255] "raw"  MATT,CMB
 SG_ ConsecutiveData7 m2 : 63|8@0+ (1,0) [0|255] "raw"  MATT,CMB
 SG_ SingleData7 m0 : 63|8@0+ (1,0) [0|255] "raw"  MATT,CMB
 SG_ FlowPadding4 m3 : 55|8@0+ (1,0) [0|255] "raw"  MATT,CMB
 SG_ FirstData5 m1 : 55|8@0+ (1,0) [0|255] "raw"  MATT,CMB
 SG_ UnknownData6 m4 : 55|8@0+ (1,0) [0|255] "raw"  MATT,CMB
 SG_ ConsecutiveData6 m2 : 55|8@0+ (1,0) [0|255] "raw"  MATT,CMB
 SG_ SingleData6 m0 : 55|8@0+ (1,0) [0|255] "raw"  MATT,CMB
 SG_ FlowPadding3 m3 : 47|8@0+ (1,0) [0|255] "raw"  MATT,CMB
 SG_ FirstData4 m1 : 47|8@0+ (1,0) [0|255] "raw"  MATT,CMB
 SG_ UnknownData5 m4 : 47|8@0+ (1,0) [0|255] "raw"  MATT,CMB
 SG_ ConsecutiveData5 m2 : 47|8@0+ (1,0) [0|255] "raw"  MATT,CMB
 SG_ SingleData5 m0 : 47|8@0+ (1,0) [0|255] "raw"  MATT,CMB
 SG_ FlowPadding2 m3 : 39|8@0+ (1,0) [0|255] "raw"  MATT,CMB
 SG_ FirstData3 m1 : 39|8@0+ (1,0) [0|255] "raw"  MATT,CMB
 SG_ UnknownData4 m4 : 39|8@0+ (1,0) [0|255] "raw"  MATT,CMB
 SG_ ConsecutiveData4 m2 : 39|8@0+ (1,0) [0|255] "raw"  MATT,CMB
 SG_ SingleData4 m0 : 39|8@0+ (1,0) [0|255] "raw"  MATT,CMB
 SG_ FlowPadding1 m3 : 31|8@0+ (1,0) [0|255] "raw"  MATT,CMB
 SG_ FirstData2 m1 : 31|8@0+ (1,0) [0|255] "raw"  MATT,CMB
 SG_ UnknownData3 m4 : 31|8@0+ (1,0) [0|255] "raw"  MATT,CMB
 SG_ ConsecutiveData3 m2 : 31|8@0+ (1,0) [0|255] "raw"  MATT,CMB
 SG_ SingleData3 m0 : 31|8@0+ (1,0) [0|255] "raw"  MATT,CMB
 SG_ FirstData1 m1 : 23|8@0+ (1,0) [0|255] "raw"  MATT,CMB
 SG_ UnknownData2 m4 : 23|8@0+ (1,0) [0|255] "raw"  MATT,CMB
 SG_ ConsecutiveData2 m2 : 23|8@0+ (1,0) [0|255] "raw"  MATT,CMB
 SG_ SingleData2 m0 : 23|8@0+ (1,0) [0|255] "raw"  MATT,CMB
 SG_ SeparationTimeRaw m3 : 23|8@0+ (1,0) [0|255] "raw"  MATT,CMB
 SG_ UnknownData1 m4 : 15|8@0+ (1,0) [0|255] "raw"  MATT,CMB
 SG_ ConsecutiveData1 m2 : 15|8@0+ (1,0) [0|255] "raw"  MATT,CMB
 SG_ SingleData1 m0 : 15|8@0+ (1,0) [0|255] "raw"  MATT,CMB
 SG_ BlockSize m3 : 15|8@0+ (1,0) [0|255] "raw"  MATT,CMB
 SG_ UnknownPciLow m4 : 3|4@0+ (1,0) [0|15] "raw"  MATT,CMB
 SG_ FlowStatus m3 : 3|4@0+ (1,0) [0|15] "raw"  MATT,CMB
 SG_ ConsecutiveSequence m2 : 3|4@0+ (1,0) [0|15] "raw"  MATT,CMB
 SG_ FirstFrameLength m1 : 3|12@0+ (1,0) [0|4095] "raw"  MATT,CMB
 SG_ SingleFrameLength m0 : 3|4@0+ (1,0) [0|15] "raw"  MATT,CMB
 SG_ IsoTpFrameType M : 7|4@0+ (1,0) [0|15] ""  MATT,CMB

BO_ 566 BSI_SlowData3: 8 BSI
 SG_ RearWindowStatus : 56|1@0+ (1,0) [0|1] ""  BTEL,ICSV,CMB,MATT,EMF,FMUX,VTH,RAD,AAS,CDC,AVP,OVIP,MDS,CRT,IDVR,SDCM,WLC
 SG_ PassengerDoorStatus : 57|1@0+ (1,0) [0|1] ""  BTEL,ICSV,CMB,MATT,EMF,FMUX,VTH,RAD,AAS,CDC,AVP,OVIP,MDS,CRT,IDVR,SDCM,WLC
 SG_ SttFunctionPresent : 58|1@0+ (1,0) [0|1] ""  BTEL,ICSV,CMB,MATT,EMF,FMUX,VTH,RAD,AAS,CDC,AVP,OVIP,MDS,CRT,IDVR,SDCM,WLC
 SG_ DriverDoorEstimatedStatus : 59|1@0+ (1,0) [0|1] ""  BTEL,ICSV,CMB,MATT,EMF,FMUX,VTH,RAD,AAS,CDC,AVP,OVIP,MDS,CRT,IDVR,SDCM,WLC
 SG_ RearLeftDoorStatus : 60|1@0+ (1,0) [0|1] ""  BTEL,ICSV,CMB,MATT,EMF,FMUX,VTH,RAD,AAS,CDC,AVP,OVIP,MDS,CRT,IDVR,SDCM,WLC
 SG_ RearRightDoorStatus : 61|1@0+ (1,0) [0|1] ""  BTEL,ICSV,CMB,MATT,EMF,FMUX,VTH,RAD,AAS,CDC,AVP,OVIP,MDS,CRT,IDVR,SDCM,WLC
 SG_ MuxFrontPanelPresence : 62|1@0+ (1,0) [0|1] ""  BTEL,ICSV,CMB,MATT,EMF,FMUX,VTH,RAD,AAS,CDC,AVP,OVIP,MDS,CRT,IDVR,SDCM,WLC
 SG_ RejectPowerOnInEco : 63|1@0+ (1,0) [0|1] ""  BTEL,ICSV,CMB,MATT,EMF,FMUX,VTH,RAD,AAS,CDC,AVP,OVIP,MDS,CRT,IDVR,SDCM,WLC
 SG_ TimeCounterResetCounter : 55|8@0+ (1,0) [0|253] ""  BTEL,ICSV,CMB,MATT,EMF,FMUX,VTH,RAD,AAS,CDC,AVP,OVIP,MDS,CRT,IDVR,SDCM,WLC
 SG_ FaultLogContext : 44|5@0+ (1,0) [0|31] ""  BTEL,ICSV,CMB,MATT,EMF,FMUX,VTH,RAD,AAS,CDC,AVP,OVIP,MDS,CRT,IDVR,SDCM,WLC
 SG_ BrakePedalSwitch : 45|1@0+ (1,0) [0|1] ""  BTEL,ICSV,CMB,MATT,EMF,FMUX,VTH,RAD,AAS,CDC,AVP,OVIP,MDS,CRT,IDVR,SDCM,WLC
 SG_ DriverDoorStatus : 46|1@0+ (1,0) [0|1] ""  BTEL,ICSV,CMB,MATT,EMF,FMUX,VTH,RAD,AAS,CDC,AVP,OVIP,MDS,CRT,IDVR,SDCM,WLC
 SG_ TrunkStatus : 47|1@0+ (1,0) [0|1] ""  BTEL,ICSV,CMB,MATT,EMF,FMUX,VTH,RAD,AAS,CDC,AVP,OVIP,MDS,CRT,IDVR,SDCM,WLC
 SG_ VehicleTimeCounter : 15|32@0+ (0.1,0) [0|429496729.3] "s"  BTEL,ICSV,CMB,MATT,EMF,FMUX,VTH,RAD,AAS,CDC,AVP,OVIP,MDS,CRT,IDVR,SDCM,WLC
 SG_ VehicleConfigMode : 3|4@0+ (1,0) [0|15] ""  BTEL,ICSV,CMB,MATT,EMF,FMUX,VTH,RAD,AAS,CDC,AVP,OVIP,MDS,CRT,IDVR,SDCM,WLC
 SG_ ElectricalNetworkState : 7|4@0+ (1,0) [0|15] ""  BTEL,ICSV,CMB,MATT,EMF,FMUX,VTH,RAD,AAS,CDC,AVP,OVIP,MDS,CRT,IDVR,SDCM,WLC

BO_ 579 MDS_OdiBufferFromTelematics: 8 MDS
 SG_ OdiTelematicsToCenterstackBuffer : 7|64@0+ (1,0) [0|18446744073709551615] ""  BTEL

BO_ 596 MDS_RemoteActionRequest: 8 MDS
 SG_ FlowPadding5 m3 : 63|8@0+ (1,0) [0|255] "raw"  BSI
 SG_ FirstData6 m1 : 63|8@0+ (1,0) [0|255] "raw"  BSI
 SG_ UnknownData7 m4 : 63|8@0+ (1,0) [0|255] "raw"  BSI
 SG_ ConsecutiveData7 m2 : 63|8@0+ (1,0) [0|255] "raw"  BSI
 SG_ SingleData7 m0 : 63|8@0+ (1,0) [0|255] "raw"  BSI
 SG_ FlowPadding4 m3 : 55|8@0+ (1,0) [0|255] "raw"  BSI
 SG_ FirstData5 m1 : 55|8@0+ (1,0) [0|255] "raw"  BSI
 SG_ UnknownData6 m4 : 55|8@0+ (1,0) [0|255] "raw"  BSI
 SG_ ConsecutiveData6 m2 : 55|8@0+ (1,0) [0|255] "raw"  BSI
 SG_ SingleData6 m0 : 55|8@0+ (1,0) [0|255] "raw"  BSI
 SG_ FlowPadding3 m3 : 47|8@0+ (1,0) [0|255] "raw"  BSI
 SG_ FirstData4 m1 : 47|8@0+ (1,0) [0|255] "raw"  BSI
 SG_ UnknownData5 m4 : 47|8@0+ (1,0) [0|255] "raw"  BSI
 SG_ ConsecutiveData5 m2 : 47|8@0+ (1,0) [0|255] "raw"  BSI
 SG_ SingleData5 m0 : 47|8@0+ (1,0) [0|255] "raw"  BSI
 SG_ FlowPadding2 m3 : 39|8@0+ (1,0) [0|255] "raw"  BSI
 SG_ FirstData3 m1 : 39|8@0+ (1,0) [0|255] "raw"  BSI
 SG_ UnknownData4 m4 : 39|8@0+ (1,0) [0|255] "raw"  BSI
 SG_ ConsecutiveData4 m2 : 39|8@0+ (1,0) [0|255] "raw"  BSI
 SG_ SingleData4 m0 : 39|8@0+ (1,0) [0|255] "raw"  BSI
 SG_ FlowPadding1 m3 : 31|8@0+ (1,0) [0|255] "raw"  BSI
 SG_ FirstData2 m1 : 31|8@0+ (1,0) [0|255] "raw"  BSI
 SG_ UnknownData3 m4 : 31|8@0+ (1,0) [0|255] "raw"  BSI
 SG_ ConsecutiveData3 m2 : 31|8@0+ (1,0) [0|255] "raw"  BSI
 SG_ SingleData3 m0 : 31|8@0+ (1,0) [0|255] "raw"  BSI
 SG_ FirstData1 m1 : 23|8@0+ (1,0) [0|255] "raw"  BSI
 SG_ UnknownData2 m4 : 23|8@0+ (1,0) [0|255] "raw"  BSI
 SG_ ConsecutiveData2 m2 : 23|8@0+ (1,0) [0|255] "raw"  BSI
 SG_ SingleData2 m0 : 23|8@0+ (1,0) [0|255] "raw"  BSI
 SG_ SeparationTimeRaw m3 : 23|8@0+ (1,0) [0|255] "raw"  BSI
 SG_ UnknownData1 m4 : 15|8@0+ (1,0) [0|255] "raw"  BSI
 SG_ ConsecutiveData1 m2 : 15|8@0+ (1,0) [0|255] "raw"  BSI
 SG_ SingleData1 m0 : 15|8@0+ (1,0) [0|255] "raw"  BSI
 SG_ BlockSize m3 : 15|8@0+ (1,0) [0|255] "raw"  BSI
 SG_ UnknownPciLow m4 : 3|4@0+ (1,0) [0|15] "raw"  BSI
 SG_ FlowStatus m3 : 3|4@0+ (1,0) [0|15] "raw"  BSI
 SG_ ConsecutiveSequence m2 : 3|4@0+ (1,0) [0|15] "raw"  BSI
 SG_ FirstFrameLength m1 : 3|12@0+ (1,0) [0|4095] "raw"  BSI
 SG_ SingleFrameLength m0 : 3|4@0+ (1,0) [0|15] "raw"  BSI
 SG_ IsoTpFrameType M : 7|4@0+ (1,0) [0|15] ""  BSI

BO_ 599 IC_Odometer: 6 IC
 SG_ Secure : 31|24@0+ (1,0) [0|16777215] ""  BSI
 SG_ RearRightWheelSpeed : 7|24@0+ (0.1,0) [0|1677721.4] "km"  BSI

BO_TX_BU_ 475 : CMB,ICSV,BTEL,OVIP;
BO_TX_BU_ 480 : RAD,ICSV;
BO_TX_BU_ 482 : ICSV,CDC;
BO_TX_BU_ 485 : RAD,BTEL,ICSV,OVIP;
BO_TX_BU_ 488 : ICSV,BSI;
BO_TX_BU_ 489 : ICSV,BTEL,OVIP;
BO_TX_BU_ 539 : RAD,MATT,BTEL,CMB,ICSV,OVIP,EMF;
BO_TX_BU_ 547 : RAD,ICSV;
BO_TX_BU_ 548 : BTEL,OVIP;
BO_TX_BU_ 549 : RAD,ICSV;
BO_TX_BU_ 552 : ICSV,BSI;
BO_TX_BU_ 553 : ICSV,BTEL,OVIP;
CM_ BO_ 438 "DATABASE_CANDIDATE: physical interpretation unverified; capture/layout evidence reported separately. INFO-DIV CAN, 125000 bit/s; CAN ID 0x1B6. PSA-RE title: WIFI. Family of frames sharing this ID: the content depends on WIFI_INFO_TYPE Source: https://github.com/prototux/PSA-RE/blob/67f7581e7622410efdbb29c7eda3b86982b9b450/buses/AEE2010.full/LS.INFO-DIV/1B6.yml. Source sender alternatives: MDS; physical TX/gateway forwarding not verified. WIRE ISO-TP ONLY: normal addressing candidate, maximum Classical CAN DLC 8; actual DLC may be shorter. Data includes padding. No reassembly, text, DID or application-layer decoding. Original application layouts are preserved in source JSON; do not decode them at wire offsets. ";
CM_ SG_ 438 FlowPadding5 "TRANSPORT_CANDIDATE: normal-addressing ISO-TP. PSA-RE bits 8.7-8.0. ";
CM_ SG_ 438 FirstData6 "TRANSPORT_CANDIDATE: normal-addressing ISO-TP. PSA-RE bits 8.7-8.0. ";
CM_ SG_ 438 UnknownData7 "TRANSPORT_CANDIDATE: normal-addressing ISO-TP. PSA-RE bits 8.7-8.0. ";
CM_ SG_ 438 ConsecutiveData7 "TRANSPORT_CANDIDATE: normal-addressing ISO-TP. PSA-RE bits 8.7-8.0. ";
CM_ SG_ 438 SingleData7 "TRANSPORT_CANDIDATE: normal-addressing ISO-TP. PSA-RE bits 8.7-8.0. ";
CM_ SG_ 438 FlowPadding4 "TRANSPORT_CANDIDATE: normal-addressing ISO-TP. PSA-RE bits 7.7-7.0. ";
CM_ SG_ 438 FirstData5 "TRANSPORT_CANDIDATE: normal-addressing ISO-TP. PSA-RE bits 7.7-7.0. ";
CM_ SG_ 438 UnknownData6 "TRANSPORT_CANDIDATE: normal-addressing ISO-TP. PSA-RE bits 7.7-7.0. ";
CM_ SG_ 438 ConsecutiveData6 "TRANSPORT_CANDIDATE: normal-addressing ISO-TP. PSA-RE bits 7.7-7.0. ";
CM_ SG_ 438 SingleData6 "TRANSPORT_CANDIDATE: normal-addressing ISO-TP. PSA-RE bits 7.7-7.0. ";
CM_ SG_ 438 FlowPadding3 "TRANSPORT_CANDIDATE: normal-addressing ISO-TP. PSA-RE bits 6.7-6.0. ";
CM_ SG_ 438 FirstData4 "TRANSPORT_CANDIDATE: normal-addressing ISO-TP. PSA-RE bits 6.7-6.0. ";
CM_ SG_ 438 UnknownData5 "TRANSPORT_CANDIDATE: normal-addressing ISO-TP. PSA-RE bits 6.7-6.0. ";
CM_ SG_ 438 ConsecutiveData5 "TRANSPORT_CANDIDATE: normal-addressing ISO-TP. PSA-RE bits 6.7-6.0. ";
CM_ SG_ 438 SingleData5 "TRANSPORT_CANDIDATE: normal-addressing ISO-TP. PSA-RE bits 6.7-6.0. ";
CM_ SG_ 438 FlowPadding2 "TRANSPORT_CANDIDATE: normal-addressing ISO-TP. PSA-RE bits 5.7-5.0. ";
CM_ SG_ 438 FirstData3 "TRANSPORT_CANDIDATE: normal-addressing ISO-TP. PSA-RE bits 5.7-5.0. ";
CM_ SG_ 438 UnknownData4 "TRANSPORT_CANDIDATE: normal-addressing ISO-TP. PSA-RE bits 5.7-5.0. ";
CM_ SG_ 438 ConsecutiveData4 "TRANSPORT_CANDIDATE: normal-addressing ISO-TP. PSA-RE bits 5.7-5.0. ";
CM_ SG_ 438 SingleData4 "TRANSPORT_CANDIDATE: normal-addressing ISO-TP. PSA-RE bits 5.7-5.0. ";
CM_ SG_ 438 FlowPadding1 "TRANSPORT_CANDIDATE: normal-addressing ISO-TP. PSA-RE bits 4.7-4.0. ";
CM_ SG_ 438 FirstData2 "TRANSPORT_CANDIDATE: normal-addressing ISO-TP. PSA-RE bits 4.7-4.0. ";
CM_ SG_ 438 UnknownData3 "TRANSPORT_CANDIDATE: normal-addressing ISO-TP. PSA-RE bits 4.7-4.0. ";
CM_ SG_ 438 ConsecutiveData3 "TRANSPORT_CANDIDATE: normal-addressing ISO-TP. PSA-RE bits 4.7-4.0. ";
CM_ SG_ 438 SingleData3 "TRANSPORT_CANDIDATE: normal-addressing ISO-TP. PSA-RE bits 4.7-4.0. ";
CM_ SG_ 438 FirstData1 "TRANSPORT_CANDIDATE: normal-addressing ISO-TP. PSA-RE bits 3.7-3.0. ";
CM_ SG_ 438 UnknownData2 "TRANSPORT_CANDIDATE: normal-addressing ISO-TP. PSA-RE bits 3.7-3.0. ";
CM_ SG_ 438 ConsecutiveData2 "TRANSPORT_CANDIDATE: normal-addressing ISO-TP. PSA-RE bits 3.7-3.0. ";
CM_ SG_ 438 SingleData2 "TRANSPORT_CANDIDATE: normal-addressing ISO-TP. PSA-RE bits 3.7-3.0. ";
CM_ SG_ 438 SeparationTimeRaw "TRANSPORT_CANDIDATE: normal-addressing ISO-TP. PSA-RE bits 3.7-3.0. Raw STmin code; 0xF1..0xF9 are not milliseconds.";
CM_ SG_ 438 UnknownData1 "TRANSPORT_CANDIDATE: normal-addressing ISO-TP. PSA-RE bits 2.7-2.0. ";
CM_ SG_ 438 ConsecutiveData1 "TRANSPORT_CANDIDATE: normal-addressing ISO-TP. PSA-RE bits 2.7-2.0. ";
CM_ SG_ 438 SingleData1 "TRANSPORT_CANDIDATE: normal-addressing ISO-TP. PSA-RE bits 2.7-2.0. ";
CM_ SG_ 438 BlockSize "TRANSPORT_CANDIDATE: normal-addressing ISO-TP. PSA-RE bits 2.7-2.0. ";
CM_ SG_ 438 UnknownPciLow "TRANSPORT_CANDIDATE: normal-addressing ISO-TP. PSA-RE bits 1.3-1.0. ";
CM_ SG_ 438 FlowStatus "TRANSPORT_CANDIDATE: normal-addressing ISO-TP. PSA-RE bits 1.3-1.0. ";
CM_ SG_ 438 ConsecutiveSequence "TRANSPORT_CANDIDATE: normal-addressing ISO-TP. PSA-RE bits 1.3-1.0. ";
CM_ SG_ 438 FirstFrameLength "TRANSPORT_CANDIDATE: normal-addressing ISO-TP. PSA-RE bits 1.3-2.0. 12-bit declared PDU length; not a reassembled value.";
CM_ SG_ 438 SingleFrameLength "TRANSPORT_CANDIDATE: normal-addressing ISO-TP. PSA-RE bits 1.3-1.0. Declared data length; not a validity check.";
CM_ SG_ 438 IsoTpFrameType "TRANSPORT_CANDIDATE: normal-addressing ISO-TP. PSA-RE bits 1.7-1.4. PCI high nibble; normal addressing candidate.";
CM_ BO_ 451 "DATABASE_CANDIDATE: physical interpretation unverified; capture/layout evidence reported separately. INFO-DIV CAN, 125000 bit/s; CAN ID 0x1C3. PSA-RE title: ODI_INDICATION_BUFFER. Opaque data buffer of the embedded diagnostics interface (ODI) between the telematics unit and the diagnostic tool: indication. Source: https://github.com/prototux/PSA-RE/blob/67f7581e7622410efdbb29c7eda3b86982b9b450/buses/AEE2010.full/LS.INFO-DIV/1C3.yml. Source sender alternatives: MDS; physical TX/gateway forwarding not verified. ";
CM_ SG_ 451 OdiIndicationBuffer "DATABASE_CANDIDATE: physical interpretation unverified; capture/layout evidence reported separately. PSA-RE bits 1.7-8.0. Open Display Interface (ODI) indication buffer";
CM_ BO_ 462 "DATABASE_CANDIDATE: physical interpretation unverified; capture/layout evidence reported separately. INFO-DIV CAN, 125000 bit/s; CAN ID 0x1CE. PSA-RE title: SDCM_PROGRAMMING. Programming code and reference number for the SDCM steering-control module. Source: https://github.com/prototux/PSA-RE/blob/67f7581e7622410efdbb29c7eda3b86982b9b450/buses/AEE2010.full/LS.INFO-DIV/1CE.yml. Source sender alternatives: BSI; physical TX/gateway forwarding not verified. ";
CM_ SG_ 462 SdcmProgrammingCodes "DATABASE_CANDIDATE: physical interpretation unverified; capture/layout evidence reported separately. PSA-RE bits 2.7-8.0. Programming of the RSK, IN code, HF code, IDE code and key number for the smart device control module (SDCM) Source text/byte field exposed as raw integer; no string decoding.";
CM_ SG_ 462 SdcmCodeNumber "DATABASE_CANDIDATE: physical interpretation unverified; capture/layout evidence reported separately. PSA-RE bits 1.3-1.0. Identifier defining the SDCM code number";
CM_ SG_ 462 LearningPackageCounter "DATABASE_CANDIDATE: physical interpretation unverified; capture/layout evidence reported separately. PSA-RE bits 1.7-1.4. Counter marking the set of learning frames belonging to the same code";
CM_ BO_ 464 "DATABASE_CANDIDATE: physical interpretation unverified; capture/layout evidence reported separately. INFO-DIV CAN, 125000 bit/s; CAN ID 0x1D0. PSA-RE title: REAR_FRAGRANCE_DIFFUSER_INFO. Cabin fragrance diffuser status: selection, intensity and cartridge type. Source: https://github.com/prototux/PSA-RE/blob/67f7581e7622410efdbb29c7eda3b86982b9b450/buses/AEE2010.full/LS.INFO-DIV/1D0.yml. Source sender alternatives: BSI; physical TX/gateway forwarding not verified. ";
CM_ SG_ 464 FragranceSelection "DATABASE_CANDIDATE: physical interpretation unverified; capture/layout evidence reported separately. PSA-RE bits 1.1-1.0. Fragrance being diffused by the system Upstream default raw=0 (not necessarily valid data).";
CM_ SG_ 464 FragranceDiffuserState "DATABASE_CANDIDATE: physical interpretation unverified; capture/layout evidence reported separately. PSA-RE bits 1.2. Fragrance cartridge type (0 = no cartridge in drawer) Upstream default raw=0 (not necessarily valid data).";
CM_ SG_ 464 FragranceIntensity "DATABASE_CANDIDATE: physical interpretation unverified; capture/layout evidence reported separately. PSA-RE bits 1.4-1.3. Fragrance intensity diffused by the system Upstream default raw=0 (not necessarily valid data).";
CM_ SG_ 464 FragranceCartridgeType "DATABASE_CANDIDATE: physical interpretation unverified; capture/layout evidence reported separately. PSA-RE bits 1.7-1.5. Fragrance cartridge type";
CM_ BO_ 471 "DATABASE_CANDIDATE: physical interpretation unverified; capture/layout evidence reported separately. INFO-DIV CAN, 125000 bit/s; CAN ID 0x1D7. PSA-RE title: LEFT_LED_HEADLAMP_DRIVER_DATA. Steering wheel button status: lane keep/positioning assist activation, driving mode selector, heated steering wheel request. Source: https://github.com/prototux/PSA-RE/blob/67f7581e7622410efdbb29c7eda3b86982b9b450/buses/AEE2010.full/LS.INFO-DIV/1D7.yml. Source sender alternatives: CMB,OVIP; physical TX/gateway forwarding not verified. VEHICLE_SOURCE_REVIEW: Owner reports original instrument cluster unit004 connected for info_buzeni_obc.csv and absent in earlier captures. This ID is absent in info_standby.csv and fully operational info_start_jizda.csv; upstream lists CMB among possible senders. Owner approved limiting IC attribution to these nine messages. Scope: Vehicle-specific sender attribution from installation report/capture comparison and compatible source alias; does not validate signal meanings or exclude gateway forwarding. Observed 4092 frames in info_buzeni_obc.csv,info_charging.csv; DLCs [1]. ";
CM_ SG_ 471 Unused1 "DATABASE_CANDIDATE: physical interpretation unverified; capture/layout evidence reported separately. PSA-RE bits 1.0. ";
CM_ SG_ 471 LpaButtonPressed "DATABASE_CANDIDATE: physical interpretation unverified; capture/layout evidence reported separately. PSA-RE bits 1.1. Lane positioning assist (LPA) button pressed by the user Upstream default raw=0 (not necessarily valid data).";
CM_ SG_ 471 VehicleModeSelector "DATABASE_CANDIDATE: physical interpretation unverified; capture/layout evidence reported separately. PSA-RE bits 1.5-1.2. Vehicle mode selected via the driving mode selector (normal, sport, comfort, eco, sand) Upstream default raw=0 (not necessarily valid data).";
CM_ SG_ 471 HadcButtonState "DATABASE_CANDIDATE: physical interpretation unverified; capture/layout evidence reported separately. PSA-RE bits 1.6. State of the physical Highway Driver Assist (HADC) push-button Upstream default raw=0 (not necessarily valid data).";
CM_ SG_ 471 LkaButtonPressed "DATABASE_CANDIDATE: physical interpretation unverified; capture/layout evidence reported separately. PSA-RE bits 1.7. Lane keeping assist (LKA) button pressed by the user Upstream default raw=0 (not necessarily valid data).";
CM_ BO_ 475 "DATABASE_CANDIDATE: physical interpretation unverified; capture/layout evidence reported separately. INFO-DIV CAN, 125000 bit/s; CAN ID 0x1DB. PSA-RE title: CRUISE_CONTROL_PRESETS_STATUS. Cruise control preset speeds (6 slots) and availability of cruise/limiter information. Source: https://github.com/prototux/PSA-RE/blob/67f7581e7622410efdbb29c7eda3b86982b9b450/buses/AEE2010.full/LS.INFO-DIV/1DB.yml. Source sender alternatives: CMB,ICSV,BTEL,OVIP; physical TX/gateway forwarding not verified. ";
CM_ SG_ 475 Unused1 "DATABASE_CANDIDATE: physical interpretation unverified; capture/layout evidence reported separately. PSA-RE bits 7.6-7.0. ";
CM_ SG_ 475 CruiseMenuInfoAvailability "DATABASE_CANDIDATE: physical interpretation unverified; capture/layout evidence reported separately. PSA-RE bits 7.7. Cruise control menu information availability Upstream default raw=0 (not necessarily valid data).";
CM_ SG_ 475 Stop6SpeedValue "DATABASE_CANDIDATE: physical interpretation unverified; capture/layout evidence reported separately. PSA-RE bits 6.7-6.0. Value of stop 6 speed Raw invalid=255; numeric DBC decoders may still scale it: check raw before use. Upstream default raw=0 (not necessarily valid data).";
CM_ SG_ 475 SpeedLimitZone5Speed "DATABASE_CANDIDATE: physical interpretation unverified; capture/layout evidence reported separately. PSA-RE bits 5.7-5.0. Speed limiter zone 5 speed value Upstream default raw=0 (not necessarily valid data).";
CM_ SG_ 475 SpeedLimitZone4Speed "DATABASE_CANDIDATE: physical interpretation unverified; capture/layout evidence reported separately. PSA-RE bits 4.7-4.0. Speed limiter zone 4 speed value Upstream default raw=0 (not necessarily valid data).";
CM_ SG_ 475 SpeedLimitZone3Speed "DATABASE_CANDIDATE: physical interpretation unverified; capture/layout evidence reported separately. PSA-RE bits 3.7-3.0. Speed limiter zone 3 speed value Upstream default raw=0 (not necessarily valid data).";
CM_ SG_ 475 SpeedLimitZone2Speed "DATABASE_CANDIDATE: physical interpretation unverified; capture/layout evidence reported separately. PSA-RE bits 2.7-2.0. Speed limiter zone 2 speed value Upstream default raw=0 (not necessarily valid data).";
CM_ SG_ 475 SpeedLimitZone1Speed "DATABASE_CANDIDATE: physical interpretation unverified; capture/layout evidence reported separately. PSA-RE bits 1.7-1.0. Speed limiter zone 1 speed value Upstream default raw=0 (not necessarily valid data).";
CM_ BO_ 476 "DATABASE_CANDIDATE: physical interpretation unverified; capture/layout evidence reported separately. INFO-DIV CAN, 125000 bit/s; CAN ID 0x1DC. PSA-RE title: ECO_DRIVING_SCORE. Eco-driving coach scores for the current trip: overall grade and per-category grades (acceleration, braking, air conditioning use, engine warm-up, gearshift, speed). Source: https://github.com/prototux/PSA-RE/blob/67f7581e7622410efdbb29c7eda3b86982b9b450/buses/AEE2010.full/LS.INFO-DIV/1DC.yml. Source sender alternatives: BSI; physical TX/gateway forwarding not verified. Observed 577 frames in info_apka.csv,info_buzeni_obc.csv,info_charging.csv,info_standby.csv,info_start_jizda.csv,infocan.csv; DLCs [8]. Unresolved alternative source layouts preserved in source JSON. ";
CM_ SG_ 476 Unused2 "DATABASE_CANDIDATE: physical interpretation unverified; capture/layout evidence reported separately. PSA-RE bits 8.7-8.0. ";
CM_ SG_ 476 Unused1 "DATABASE_CANDIDATE: physical interpretation unverified; capture/layout evidence reported separately. PSA-RE bits 7.1-7.0. ";
CM_ SG_ 476 EcocoachTripRangeGain "DATABASE_CANDIDATE: physical interpretation unverified; capture/layout evidence reported separately. PSA-RE bits 6.7-7.2. Displayed range won or lost on the Eco Coaching trip Raw invalid=16383; numeric DBC decoders may still scale it: check raw before use. Upstream default raw=16383 (not necessarily valid data).";
CM_ SG_ 476 EcocoachGlobalTripScore "DATABASE_CANDIDATE: physical interpretation unverified; capture/layout evidence reported separately. PSA-RE bits 5.3-5.0. Displayed global Eco Coaching score Raw invalid=15; numeric DBC decoders may still scale it: check raw before use. Upstream default raw=14 (not necessarily valid data).";
CM_ SG_ 476 EcocoachScoreStopStart "DATABASE_CANDIDATE: physical interpretation unverified; capture/layout evidence reported separately. PSA-RE bits 5.7-5.4. Eco Coaching score displayed for the stop & start item Raw invalid=15; numeric DBC decoders may still scale it: check raw before use. Upstream default raw=15 (not necessarily valid data).";
CM_ SG_ 476 EcocoachScoreSpeed "DATABASE_CANDIDATE: physical interpretation unverified; capture/layout evidence reported separately. PSA-RE bits 4.3-4.0. Eco Coaching score displayed for the vehicle speed item Raw invalid=15; numeric DBC decoders may still scale it: check raw before use. Upstream default raw=15 (not necessarily valid data).";
CM_ SG_ 476 EcocoachScoreSlope "DATABASE_CANDIDATE: physical interpretation unverified; capture/layout evidence reported separately. PSA-RE bits 4.7-4.4. Eco Coaching score displayed for the equivalent slope item Raw invalid=15; numeric DBC decoders may still scale it: check raw before use. Upstream default raw=15 (not necessarily valid data).";
CM_ SG_ 476 EcocoachScoreGsi "DATABASE_CANDIDATE: physical interpretation unverified; capture/layout evidence reported separately. PSA-RE bits 3.3-3.0. Eco Coaching score displayed for the gear shift indicator (GSI) item Raw invalid=15; numeric DBC decoders may still scale it: check raw before use. Upstream default raw=15 (not necessarily valid data).";
CM_ SG_ 476 EcocoachScoreTyrePressure "DATABASE_CANDIDATE: physical interpretation unverified; capture/layout evidence reported separately. PSA-RE bits 3.7-3.4. Eco Coaching score displayed for the tyre under-inflation item Raw invalid=15; numeric DBC decoders may still scale it: check raw before use. Upstream default raw=15 (not necessarily valid data).";
CM_ SG_ 476 EcocoachScoreColdEngine "DATABASE_CANDIDATE: physical interpretation unverified; capture/layout evidence reported separately. PSA-RE bits 2.3-2.0. Eco Coaching score displayed for the cold engine item Raw invalid=15; numeric DBC decoders may still scale it: check raw before use. Upstream default raw=15 (not necessarily valid data).";
CM_ SG_ 476 EcocoachScoreClimate "DATABASE_CANDIDATE: physical interpretation unverified; capture/layout evidence reported separately. PSA-RE bits 2.7-2.4. Eco Coaching score displayed for the climate comfort item Raw invalid=15; numeric DBC decoders may still scale it: check raw before use. Upstream default raw=15 (not necessarily valid data).";
CM_ SG_ 476 EcocoachScoreBraking "DATABASE_CANDIDATE: physical interpretation unverified; capture/layout evidence reported separately. PSA-RE bits 1.3-1.0. Eco Coaching score displayed for the braking item Raw invalid=15; numeric DBC decoders may still scale it: check raw before use. Upstream default raw=15 (not necessarily valid data).";
CM_ SG_ 476 EcocoachScoreAcceleration "DATABASE_CANDIDATE: physical interpretation unverified; capture/layout evidence reported separately. PSA-RE bits 1.7-1.4. Eco Coaching score displayed for the acceleration item Raw invalid=15; numeric DBC decoders may still scale it: check raw before use. Upstream default raw=15 (not necessarily valid data).";
CM_ BO_ 480 "DATABASE_CANDIDATE: physical interpretation unverified; capture/layout evidence reported separately. INFO-DIV CAN, 125000 bit/s; CAN ID 0x1E0. PSA-RE title: RADIO_CONFIG_STATUS. Radio configuration and status: ambience selection, CD-text, scan, random track, PTY and RDS settings. Source: https://github.com/prototux/PSA-RE/blob/67f7581e7622410efdbb29c7eda3b86982b9b450/buses/AEE2010.full/LS.INFO-DIV/1E0.yml. Source sender alternatives: RAD,ICSV; physical TX/gateway forwarding not verified. ";
CM_ SG_ 480 Unused1 "DATABASE_CANDIDATE: physical interpretation unverified; capture/layout evidence reported separately. PSA-RE bits 7.2-7.0. ";
CM_ SG_ 480 NextListType "DATABASE_CANDIDATE: physical interpretation unverified; capture/layout evidence reported separately. PSA-RE bits 7.5-7.3. Type of the next list Upstream default raw=0 (not necessarily valid data).";
CM_ SG_ 480 DirectoryListOption "DATABASE_CANDIDATE: physical interpretation unverified; capture/layout evidence reported separately. PSA-RE bits 7.7-7.6. Directory list function availability Upstream default raw=0 (not necessarily valid data).";
CM_ SG_ 480 PlaylistListOption "DATABASE_CANDIDATE: physical interpretation unverified; capture/layout evidence reported separately. PSA-RE bits 6.1-6.0. Playlist list function availability Upstream default raw=0 (not necessarily valid data).";
CM_ SG_ 480 GenreListOption "DATABASE_CANDIDATE: physical interpretation unverified; capture/layout evidence reported separately. PSA-RE bits 6.3-6.2. Genre list function availability Upstream default raw=0 (not necessarily valid data).";
CM_ SG_ 480 ArtistListOption "DATABASE_CANDIDATE: physical interpretation unverified; capture/layout evidence reported separately. PSA-RE bits 6.5-6.4. Artist list function availability Upstream default raw=0 (not necessarily valid data).";
CM_ SG_ 480 News7Option "DATABASE_CANDIDATE: physical interpretation unverified; capture/layout evidence reported separately. PSA-RE bits 6.7-6.6. News option 7 state Upstream default raw=0 (not necessarily valid data).";
CM_ SG_ 480 News6Option "DATABASE_CANDIDATE: physical interpretation unverified; capture/layout evidence reported separately. PSA-RE bits 5.1-5.0. News option 6 state Upstream default raw=0 (not necessarily valid data).";
CM_ SG_ 480 News5Option "DATABASE_CANDIDATE: physical interpretation unverified; capture/layout evidence reported separately. PSA-RE bits 5.3-5.2. News option 5 state Upstream default raw=0 (not necessarily valid data).";
CM_ SG_ 480 News4Option "DATABASE_CANDIDATE: physical interpretation unverified; capture/layout evidence reported separately. PSA-RE bits 5.5-5.4. News option 4 state Upstream default raw=0 (not necessarily valid data).";
CM_ SG_ 480 News3Option "DATABASE_CANDIDATE: physical interpretation unverified; capture/layout evidence reported separately. PSA-RE bits 5.7-5.6. News option 3 state Upstream default raw=0 (not necessarily valid data).";
CM_ SG_ 480 News2Option "DATABASE_CANDIDATE: physical interpretation unverified; capture/layout evidence reported separately. PSA-RE bits 4.1-4.0. News option 2 state Upstream default raw=0 (not necessarily valid data).";
CM_ SG_ 480 News1Option "DATABASE_CANDIDATE: physical interpretation unverified; capture/layout evidence reported separately. PSA-RE bits 4.3-4.2. News option 1 state Upstream default raw=0 (not necessarily valid data).";
CM_ SG_ 480 DabfmOption "DATABASE_CANDIDATE: physical interpretation unverified; capture/layout evidence reported separately. PSA-RE bits 4.5-4.4. DAB/FM option state Upstream default raw=0 (not necessarily valid data).";
CM_ SG_ 480 RadioNewsOption7Status "DATABASE_CANDIDATE: physical interpretation unverified; capture/layout evidence reported separately. PSA-RE bits 4.6. Status of the NEWS7 radio option Upstream default raw=0 (not necessarily valid data).";
CM_ SG_ 480 RadioNewsOption6Status "DATABASE_CANDIDATE: physical interpretation unverified; capture/layout evidence reported separately. PSA-RE bits 4.7. Status of the NEWS6 radio option Upstream default raw=0 (not necessarily valid data).";
CM_ SG_ 480 RadioNewsOption5Status "DATABASE_CANDIDATE: physical interpretation unverified; capture/layout evidence reported separately. PSA-RE bits 3.0. Status of the NEWS5 radio option Upstream default raw=0 (not necessarily valid data).";
CM_ SG_ 480 RadioNewsOption4Status "DATABASE_CANDIDATE: physical interpretation unverified; capture/layout evidence reported separately. PSA-RE bits 3.1. Status of the NEWS4 radio option Upstream default raw=0 (not necessarily valid data).";
CM_ SG_ 480 RadioNewsOption3Status "DATABASE_CANDIDATE: physical interpretation unverified; capture/layout evidence reported separately. PSA-RE bits 3.2. Status of the NEWS3 radio option Upstream default raw=0 (not necessarily valid data).";
CM_ SG_ 480 RadioNewsOption2Status "DATABASE_CANDIDATE: physical interpretation unverified; capture/layout evidence reported separately. PSA-RE bits 3.3. Status of the NEWS2 radio option Upstream default raw=0 (not necessarily valid data).";
CM_ SG_ 480 RadioNewsOption1Status "DATABASE_CANDIDATE: physical interpretation unverified; capture/layout evidence reported separately. PSA-RE bits 3.4. Status of the NEWS1 radio option Upstream default raw=0 (not necessarily valid data).";
CM_ SG_ 480 RadioDabFmStatus "DATABASE_CANDIDATE: physical interpretation unverified; capture/layout evidence reported separately. PSA-RE bits 3.5. Status of the DAB/FM option Upstream default raw=0 (not necessarily valid data).";
CM_ SG_ 480 RadioRdsAfStatus "DATABASE_CANDIDATE: physical interpretation unverified; capture/layout evidence reported separately. PSA-RE bits 3.6. Status of RDS alternative frequency (AF) monitoring Upstream default raw=0 (not necessarily valid data).";
CM_ SG_ 480 RadioTextModeStatus "DATABASE_CANDIDATE: physical interpretation unverified; capture/layout evidence reported separately. PSA-RE bits 3.7. Radio Text mode activation status Upstream default raw=0 (not necessarily valid data).";
CM_ SG_ 480 RadioTextOption "DATABASE_CANDIDATE: physical interpretation unverified; capture/layout evidence reported separately. PSA-RE bits 2.1-2.0. Radio-Text mode option Upstream default raw=0 (not necessarily valid data).";
CM_ SG_ 480 RdsAfOption "DATABASE_CANDIDATE: physical interpretation unverified; capture/layout evidence reported separately. PSA-RE bits 2.3-2.2. RDS alternative frequency tracking option Upstream default raw=0 (not necessarily valid data).";
CM_ SG_ 480 ShuffleModeStatus "DATABASE_CANDIDATE: physical interpretation unverified; capture/layout evidence reported separately. PSA-RE bits 2.4. Global shuffle mode activation status Upstream default raw=0 (not necessarily valid data).";
CM_ SG_ 480 ShuffleAllOption "DATABASE_CANDIDATE: physical interpretation unverified; capture/layout evidence reported separately. PSA-RE bits 2.6-2.5. Global shuffle (random all) mode option Upstream default raw=0 (not necessarily valid data).";
CM_ SG_ 480 CdTextModeStatus "DATABASE_CANDIDATE: physical interpretation unverified; capture/layout evidence reported separately. PSA-RE bits 2.7. CD Text mode activation status Upstream default raw=0 (not necessarily valid data).";
CM_ SG_ 480 CdTextOption "DATABASE_CANDIDATE: physical interpretation unverified; capture/layout evidence reported separately. PSA-RE bits 1.1-1.0. CD-Text mode option Upstream default raw=0 (not necessarily valid data).";
CM_ SG_ 480 RepeatEnabled "DATABASE_CANDIDATE: physical interpretation unverified; capture/layout evidence reported separately. PSA-RE bits 1.2. Disc/directory repeat mode activation status Upstream default raw=0 (not necessarily valid data).";
CM_ SG_ 480 DiscRepeatOption "DATABASE_CANDIDATE: physical interpretation unverified; capture/layout evidence reported separately. PSA-RE bits 1.4-1.3. Disc repeat mode option Upstream default raw=0 (not necessarily valid data).";
CM_ SG_ 480 RandomEnabled "DATABASE_CANDIDATE: physical interpretation unverified; capture/layout evidence reported separately. PSA-RE bits 1.5. Track/file shuffle mode activation status Upstream default raw=0 (not necessarily valid data).";
CM_ SG_ 480 TrackShuffleOption "DATABASE_CANDIDATE: physical interpretation unverified; capture/layout evidence reported separately. PSA-RE bits 1.7-1.6. Track shuffle mode option Upstream default raw=0 (not necessarily valid data).";
CM_ BO_ 481 "DATABASE_CANDIDATE: physical interpretation unverified; capture/layout evidence reported separately. INFO-DIV CAN, 125000 bit/s; CAN ID 0x1E1. PSA-RE title: TPMS_STATUS. Values of pressures returned by the wheel sensors: overall TPMS state and status of each wheel including the spare. Source: https://github.com/prototux/PSA-RE/blob/67f7581e7622410efdbb29c7eda3b86982b9b450/buses/AEE2010.full/LS.INFO-DIV/1E1.yml. Source sender alternatives: BSI; physical TX/gateway forwarding not verified. Observed 1173 frames in info_apka.csv,info_buzeni_obc.csv,info_charging.csv,info_standby.csv,info_start_jizda.csv,infocan.csv; DLCs [4]. Unresolved alternative source layouts preserved in source JSON. ";
CM_ SG_ 481 GeneralTpmsStatus "DATABASE_CANDIDATE: physical interpretation unverified; capture/layout evidence reported separately. PSA-RE bits 4.2-4.0. General tyre pressure monitoring status Upstream default raw=7 (not necessarily valid data).";
CM_ SG_ 481 RearRightWheelStatus "DATABASE_CANDIDATE: physical interpretation unverified; capture/layout evidence reported separately. PSA-RE bits 4.7-4.3. Rear right wheel tyre pressure status Upstream default raw=16 (not necessarily valid data).";
CM_ SG_ 481 WheelDataUpdateBit "DATABASE_CANDIDATE: physical interpretation unverified; capture/layout evidence reported separately. PSA-RE bits 3.0. Update bit for the wheel data signal Upstream default raw=0 (not necessarily valid data).";
CM_ SG_ 481 Unused3 "DATABASE_CANDIDATE: physical interpretation unverified; capture/layout evidence reported separately. PSA-RE bits 3.2-3.1. ";
CM_ SG_ 481 RearLeftWheelStatus "DATABASE_CANDIDATE: physical interpretation unverified; capture/layout evidence reported separately. PSA-RE bits 3.7-3.3. Rear left wheel tyre pressure status Upstream default raw=16 (not necessarily valid data).";
CM_ SG_ 481 Unused2 "DATABASE_CANDIDATE: physical interpretation unverified; capture/layout evidence reported separately. PSA-RE bits 2.2-2.0. ";
CM_ SG_ 481 FrontRightWheelStatus "DATABASE_CANDIDATE: physical interpretation unverified; capture/layout evidence reported separately. PSA-RE bits 2.7-2.3. Front right wheel tyre pressure status Upstream default raw=16 (not necessarily valid data).";
CM_ SG_ 481 Unused1 "DATABASE_CANDIDATE: physical interpretation unverified; capture/layout evidence reported separately. PSA-RE bits 1.2-1.0. ";
CM_ SG_ 481 FrontLeftWheelStatus "DATABASE_CANDIDATE: physical interpretation unverified; capture/layout evidence reported separately. PSA-RE bits 1.7-1.3. Front left wheel tyre pressure status Upstream default raw=16 (not necessarily valid data).";
CM_ BO_ 482 "DATABASE_CANDIDATE: physical interpretation unverified; capture/layout evidence reported separately. INFO-DIV CAN, 125000 bit/s; CAN ID 0x1E2. PSA-RE title: CD_CHANGER_TRACK_STATUS. CD changer current track status: track number, origin of change, and elapsed/track time (minutes/seconds). Source: https://github.com/prototux/PSA-RE/blob/67f7581e7622410efdbb29c7eda3b86982b9b450/buses/AEE2010.full/LS.INFO-DIV/1E2.yml. Source sender alternatives: ICSV,CDC; physical TX/gateway forwarding not verified. ";
CM_ SG_ 482 Unused2 "DATABASE_CANDIDATE: physical interpretation unverified; capture/layout evidence reported separately. PSA-RE bits 7.7-7.0. ";
CM_ SG_ 482 Unused1 "DATABASE_CANDIDATE: physical interpretation unverified; capture/layout evidence reported separately. PSA-RE bits 6.3-6.0. ";
CM_ SG_ 482 CurrentFileFormat "DATABASE_CANDIDATE: physical interpretation unverified; capture/layout evidence reported separately. PSA-RE bits 6.6-6.4. Format of the current file/track Upstream default raw=0 (not necessarily valid data).";
CM_ SG_ 482 CdcTrackChangeOrigin "DATABASE_CANDIDATE: physical interpretation unverified; capture/layout evidence reported separately. PSA-RE bits 6.7. Origin of the CD changer audio track change (automatic or manual) Upstream default raw=0 (not necessarily valid data).";
CM_ SG_ 482 ElapsedSeconds "DATABASE_CANDIDATE: physical interpretation unverified; capture/layout evidence reported separately. PSA-RE bits 5.6-5.0. Seconds elapsed since the start of the track Upstream default raw=127 (not necessarily valid data).";
CM_ SG_ 482 TrackElapsedSign "DATABASE_CANDIDATE: physical interpretation unverified; capture/layout evidence reported separately. PSA-RE bits 5.7. Sign of the minutes elapsed since the start of the track Upstream default raw=0 (not necessarily valid data).";
CM_ SG_ 482 ElapsedMinutes "DATABASE_CANDIDATE: physical interpretation unverified; capture/layout evidence reported separately. PSA-RE bits 4.7-4.0. Minutes elapsed since the start of the track Upstream default raw=255 (not necessarily valid data).";
CM_ SG_ 482 DurationSeconds "DATABASE_CANDIDATE: physical interpretation unverified; capture/layout evidence reported separately. PSA-RE bits 3.7-3.0. Total duration of the track, seconds Upstream default raw=255 (not necessarily valid data).";
CM_ SG_ 482 DurationMinutes "DATABASE_CANDIDATE: physical interpretation unverified; capture/layout evidence reported separately. PSA-RE bits 2.7-2.0. Total duration of the track, minutes Upstream default raw=255 (not necessarily valid data).";
CM_ SG_ 482 TrackNumber "DATABASE_CANDIDATE: physical interpretation unverified; capture/layout evidence reported separately. PSA-RE bits 1.7-1.0. Current track number Upstream default raw=255 (not necessarily valid data).";
CM_ BO_ 484 "DATABASE_CANDIDATE: physical interpretation unverified; capture/layout evidence reported separately. INFO-DIV CAN, 125000 bit/s; CAN ID 0x1E4. PSA-RE title: REAR_SEAT_ENTERTAINMENT_REMOTE_STATUS. Rear seat entertainment remote control status: navigation buttons, mute, power, sound availability and source selection. Source: https://github.com/prototux/PSA-RE/blob/67f7581e7622410efdbb29c7eda3b86982b9b450/buses/AEE2010.full/LS.INFO-DIV/1E4.yml. Source sender alternatives: ICSV; physical TX/gateway forwarding not verified. ";
CM_ SG_ 484 Unused1 "DATABASE_CANDIDATE: physical interpretation unverified; capture/layout evidence reported separately. PSA-RE bits 2.3-2.0. ";
CM_ SG_ 484 RseActive "DATABASE_CANDIDATE: physical interpretation unverified; capture/layout evidence reported separately. PSA-RE bits 2.4. Rear-seat entertainment (RSE) system active Upstream default raw=0 (not necessarily valid data).";
CM_ SG_ 484 RseSourceButton2 "DATABASE_CANDIDATE: physical interpretation unverified; capture/layout evidence reported separately. PSA-RE bits 2.5. Rear-seat entertainment (RSE) source button Upstream default raw=0 (not necessarily valid data).";
CM_ SG_ 484 RseAudioOutputAvailable "DATABASE_CANDIDATE: physical interpretation unverified; capture/layout evidence reported separately. PSA-RE bits 2.6. Audio output availability on the rear-seat entertainment (RSE) system Upstream default raw=0 (not necessarily valid data).";
CM_ SG_ 484 RseEscButton "DATABASE_CANDIDATE: physical interpretation unverified; capture/layout evidence reported separately. PSA-RE bits 2.7. RSE escape button Upstream default raw=0 (not necessarily valid data).";
CM_ SG_ 484 RseOkButton "DATABASE_CANDIDATE: physical interpretation unverified; capture/layout evidence reported separately. PSA-RE bits 1.0. RSE OK (confirm) button Upstream default raw=0 (not necessarily valid data).";
CM_ SG_ 484 RseArrowDownButton "DATABASE_CANDIDATE: physical interpretation unverified; capture/layout evidence reported separately. PSA-RE bits 1.1. RSE down arrow button Upstream default raw=0 (not necessarily valid data).";
CM_ SG_ 484 RseArrowUpButton "DATABASE_CANDIDATE: physical interpretation unverified; capture/layout evidence reported separately. PSA-RE bits 1.2. RSE up arrow button Upstream default raw=0 (not necessarily valid data).";
CM_ SG_ 484 RseArrowRightButton "DATABASE_CANDIDATE: physical interpretation unverified; capture/layout evidence reported separately. PSA-RE bits 1.3. RSE right arrow button Upstream default raw=0 (not necessarily valid data).";
CM_ SG_ 484 RseArrowLeftButton "DATABASE_CANDIDATE: physical interpretation unverified; capture/layout evidence reported separately. PSA-RE bits 1.4. RSE left arrow button Upstream default raw=0 (not necessarily valid data).";
CM_ SG_ 484 RseVolumeDownButton "DATABASE_CANDIDATE: physical interpretation unverified; capture/layout evidence reported separately. PSA-RE bits 1.5. RSE volume down button Upstream default raw=0 (not necessarily valid data).";
CM_ SG_ 484 RseVolumeUpButton "DATABASE_CANDIDATE: physical interpretation unverified; capture/layout evidence reported separately. PSA-RE bits 1.6. RSE volume up button Upstream default raw=0 (not necessarily valid data).";
CM_ SG_ 484 RseSourceButton "DATABASE_CANDIDATE: physical interpretation unverified; capture/layout evidence reported separately. PSA-RE bits 1.7. Rear-seat entertainment (RSE) source button Upstream default raw=0 (not necessarily valid data).";
CM_ BO_ 485 "DATABASE_CANDIDATE: physical interpretation unverified; capture/layout evidence reported separately. INFO-DIV CAN, 125000 bit/s; CAN ID 0x1E5. PSA-RE title: RADIO_STATUS_AUDIO. Active-setting bits indicating to the display which audio setting is currently being adjusted, plus balance/bass/fader/treble/loudness levels. Source: https://github.com/prototux/PSA-RE/blob/67f7581e7622410efdbb29c7eda3b86982b9b450/buses/AEE2010.full/LS.INFO-DIV/1E5.yml. Source sender alternatives: RAD,BTEL,ICSV,OVIP; physical TX/gateway forwarding not verified. Observed 1173 frames in info_apka.csv,info_buzeni_obc.csv,info_charging.csv,info_standby.csv,info_start_jizda.csv,infocan.csv; DLCs [7]. ";
CM_ SG_ 485 Unused1 "DATABASE_CANDIDATE: physical interpretation unverified; capture/layout evidence reported separately. PSA-RE bits 7.0. ";
CM_ SG_ 485 SpatialSettingStatus "DATABASE_CANDIDATE: physical interpretation unverified; capture/layout evidence reported separately. PSA-RE bits 7.1. Spactial setting Upstream default raw=0 (not necessarily valid data).";
CM_ SG_ 485 SpectralSettingStatus "DATABASE_CANDIDATE: physical interpretation unverified; capture/layout evidence reported separately. PSA-RE bits 7.2. Spectral setting Upstream default raw=0 (not necessarily valid data).";
CM_ SG_ 485 AudioAdjustmentImpossible "DATABASE_CANDIDATE: physical interpretation unverified; capture/layout evidence reported separately. PSA-RE bits 7.3. Impossible audio adjustment in phone source Upstream default raw=0 (not necessarily valid data).";
CM_ SG_ 485 PredefinedDistribution "DATABASE_CANDIDATE: physical interpretation unverified; capture/layout evidence reported separately. PSA-RE bits 7.6-7.4. Predefined distribution Upstream default raw=0 (not necessarily valid data).";
CM_ SG_ 485 DistributionMenu "DATABASE_CANDIDATE: physical interpretation unverified; capture/layout evidence reported separately. PSA-RE bits 7.7. Distribution setting Upstream default raw=0 (not necessarily valid data).";
CM_ SG_ 485 DistributionActivationStatus "DATABASE_CANDIDATE: physical interpretation unverified; capture/layout evidence reported separately. PSA-RE bits 6.1-6.0. REPARATION activation satus Upstream default raw=0 (not necessarily valid data).";
CM_ SG_ 485 AmbianceMenu "DATABASE_CANDIDATE: physical interpretation unverified; capture/layout evidence reported separately. PSA-RE bits 6.2. Ambience setting Upstream default raw=0 (not necessarily valid data).";
CM_ SG_ 485 AmbianceValue "DATABASE_CANDIDATE: physical interpretation unverified; capture/layout evidence reported separately. PSA-RE bits 6.5-6.3. Type of musical environment chosen. Upstream default raw=0 (not necessarily valid data).";
CM_ SG_ 485 AmbianceActivationStatus "DATABASE_CANDIDATE: physical interpretation unverified; capture/layout evidence reported separately. PSA-RE bits 6.7-6.6. Ambience activation status Upstream default raw=0 (not necessarily valid data).";
CM_ SG_ 485 SpeedVolumeControlActive "DATABASE_CANDIDATE: physical interpretation unverified; capture/layout evidence reported separately. PSA-RE bits 5.1-5.0. Enabled speed/volume control (by configuration in diagnosis session) Upstream default raw=0 (not necessarily valid data).";
CM_ SG_ 485 AutoVolumeStatus "DATABASE_CANDIDATE: physical interpretation unverified; capture/layout evidence reported separately. PSA-RE bits 5.2. Status of volume/speed control Upstream default raw=0 (not necessarily valid data).";
CM_ SG_ 485 AutoVolumeAdjustment "DATABASE_CANDIDATE: physical interpretation unverified; capture/layout evidence reported separately. PSA-RE bits 5.3. Volume / speed control adjustment Upstream default raw=0 (not necessarily valid data).";
CM_ SG_ 485 LoudnessValue "DATABASE_CANDIDATE: physical interpretation unverified; capture/layout evidence reported separately. PSA-RE bits 5.4. Loudness state Upstream default raw=0 (not necessarily valid data).";
CM_ SG_ 485 LoudnessActivationStatus "DATABASE_CANDIDATE: physical interpretation unverified; capture/layout evidence reported separately. PSA-RE bits 5.6-5.5. LOUDNESS activation status Upstream default raw=0 (not necessarily valid data).";
CM_ SG_ 485 LoudnessMenu "DATABASE_CANDIDATE: physical interpretation unverified; capture/layout evidence reported separately. PSA-RE bits 5.7. Adjustment of Loudness Upstream default raw=0 (not necessarily valid data).";
CM_ SG_ 485 TrebleActivationStatus "DATABASE_CANDIDATE: physical interpretation unverified; capture/layout evidence reported separately. PSA-RE bits 4.1-4.0. TREBLE activation satus Upstream default raw=0 (not necessarily valid data).";
CM_ SG_ 485 TrebleValue "DATABASE_CANDIDATE: physical interpretation unverified; capture/layout evidence reported separately. PSA-RE bits 4.6-4.2. Current level of treble setpoint Upstream default raw=15 (not necessarily valid data).";
CM_ SG_ 485 TrebleMenu "DATABASE_CANDIDATE: physical interpretation unverified; capture/layout evidence reported separately. PSA-RE bits 4.7. Adjustment of treble setpoint Upstream default raw=0 (not necessarily valid data).";
CM_ SG_ 485 BassActivationStatus "DATABASE_CANDIDATE: physical interpretation unverified; capture/layout evidence reported separately. PSA-RE bits 3.1-3.0. Activation status of BASSE Upstream default raw=0 (not necessarily valid data).";
CM_ SG_ 485 BassValue "DATABASE_CANDIDATE: physical interpretation unverified; capture/layout evidence reported separately. PSA-RE bits 3.6-3.2. Current level of bass setpoint Upstream default raw=15 (not necessarily valid data).";
CM_ SG_ 485 BassMenu "DATABASE_CANDIDATE: physical interpretation unverified; capture/layout evidence reported separately. PSA-RE bits 3.7. Adjustment of bass setpoint. Upstream default raw=0 (not necessarily valid data).";
CM_ SG_ 485 FaderActive "DATABASE_CANDIDATE: physical interpretation unverified; capture/layout evidence reported separately. PSA-RE bits 2.1-2.0. Fader activated (by configuration in diagnosis session) Upstream default raw=0 (not necessarily valid data).";
CM_ SG_ 485 RearFrontBalancfValue "DATABASE_CANDIDATE: physical interpretation unverified; capture/layout evidence reported separately. PSA-RE bits 2.6-2.2. Current level of fader setpoint (FRONT/REAR balance) Upstream default raw=15 (not necessarily valid data).";
CM_ SG_ 485 RearFrontBalancfMenu "DATABASE_CANDIDATE: physical interpretation unverified; capture/layout evidence reported separately. PSA-RE bits 2.7. Adjustment of fader setpoint (FRONT/REAR balance) Upstream default raw=0 (not necessarily valid data).";
CM_ SG_ 485 BalanceActivationStatus "DATABASE_CANDIDATE: physical interpretation unverified; capture/layout evidence reported separately. PSA-RE bits 1.1-1.0. Activation status of BALANCE Upstream default raw=0 (not necessarily valid data).";
CM_ SG_ 485 LeftRightBalanceValue "DATABASE_CANDIDATE: physical interpretation unverified; capture/layout evidence reported separately. PSA-RE bits 1.6-1.2. Current level of setpoint of L / R balance Upstream default raw=15 (not necessarily valid data).";
CM_ SG_ 485 LeftRightBalanceMenu "DATABASE_CANDIDATE: physical interpretation unverified; capture/layout evidence reported separately. PSA-RE bits 1.7. Adjustment of the L/R balance value Upstream default raw=0 (not necessarily valid data).";
CM_ BO_ 487 "DATABASE_CANDIDATE: physical interpretation unverified; capture/layout evidence reported separately. INFO-DIV CAN, 125000 bit/s; CAN ID 0x1E7. PSA-RE title: ARTIV_AND_HYBRID_STATUS. Adaptive cruise control (target detection and gap) and hybrid system status: alert, detected target, display mode, gap setpoint. Source: https://github.com/prototux/PSA-RE/blob/67f7581e7622410efdbb29c7eda3b86982b9b450/buses/AEE2010.full/LS.INFO-DIV/1E7.yml. Source sender alternatives: BSI; physical TX/gateway forwarding not verified. Observed 2938 frames in info_apka.csv,info_buzeni_obc.csv,info_charging.csv,info_standby.csv,info_start_jizda.csv,infocan.csv; DLCs [8]. ";
CM_ SG_ 487 Unused2 "DATABASE_CANDIDATE: physical interpretation unverified; capture/layout evidence reported separately. PSA-RE bits 8.0. ";
CM_ SG_ 487 ZtepPowerRatio "DATABASE_CANDIDATE: physical interpretation unverified; capture/layout evidence reported separately. PSA-RE bits 8.7-8.1. Percentage of vehicle power relative to ZTEP available power Raw invalid=63; numeric DBC decoders may still scale it: check raw before use. Upstream default raw=0 (not necessarily valid data).";
CM_ SG_ 487 DaaLateralControlState "DATABASE_CANDIDATE: physical interpretation unverified; capture/layout evidence reported separately. PSA-RE bits 7.0. Operational state of the DAA lateral control indicator Upstream default raw=0 (not necessarily valid data).";
CM_ SG_ 487 LpaReadyWhenSelected "DATABASE_CANDIDATE: physical interpretation unverified; capture/layout evidence reported separately. PSA-RE bits 7.1. Indicates, once the function is selected, whether it will become active when ACC is active Upstream default raw=0 (not necessarily valid data).";
CM_ SG_ 487 LpaStateStatus "DATABASE_CANDIDATE: physical interpretation unverified; capture/layout evidence reported separately. PSA-RE bits 7.3-7.2. Continuous status information for the driver: function not selected, selected (chosen but unable to operate), or active (in progress, suspended or faulty) Upstream default raw=0 (not necessarily valid data).";
CM_ SG_ 487 PlugIndicatorLampRequest "DATABASE_CANDIDATE: physical interpretation unverified; capture/layout evidence reported separately. PSA-RE bits 7.5-7.4. Request to light the charging plug indicator lamp Upstream default raw=0 (not necessarily valid data).";
CM_ SG_ 487 LkaStateStatus "DATABASE_CANDIDATE: physical interpretation unverified; capture/layout evidence reported separately. PSA-RE bits 7.7-7.6. Status information for the driver indicating the state of the lane keeping assist function Upstream default raw=0 (not necessarily valid data).";
CM_ SG_ 487 LkaLeftLineStatus "DATABASE_CANDIDATE: physical interpretation unverified; capture/layout evidence reported separately. PSA-RE bits 6.1-6.0. Continuous status information for the driver about the lane keeping function on the left line Upstream default raw=1 (not necessarily valid data).";
CM_ SG_ 487 LkaRightLineStatus "DATABASE_CANDIDATE: physical interpretation unverified; capture/layout evidence reported separately. PSA-RE bits 6.3-6.2. Continuous status information for the driver about the lane keeping function on the right line Upstream default raw=1 (not necessarily valid data).";
CM_ SG_ 487 DaaLateralControlLevel "DATABASE_CANDIDATE: physical interpretation unverified; capture/layout evidence reported separately. PSA-RE bits 6.7-6.4. Driver alertness level information for lateral control Upstream default raw=8 (not necessarily valid data).";
CM_ SG_ 487 HybridPowerTraction "DATABASE_CANDIDATE: physical interpretation unverified; capture/layout evidence reported separately. PSA-RE bits 4.0-5.0. Power delivered by the hybrid powertrain Raw invalid=511; numeric DBC decoders may still scale it: check raw before use. Upstream default raw=510 (not necessarily valid data).";
CM_ SG_ 487 PowerBatteryHt "DATABASE_CANDIDATE: physical interpretation unverified; capture/layout evidence reported separately. PSA-RE bits 4.7-4.1. High-voltage battery power balance Raw invalid=127; numeric DBC decoders may still scale it: check raw before use. Upstream default raw=50 (not necessarily valid data).";
CM_ SG_ 487 TivTarget "DATABASE_CANDIDATE: physical interpretation unverified; capture/layout evidence reported separately. PSA-RE bits 3.7-3.0. Target time interval to the vehicle ahead (TIV) Raw invalid=255; numeric DBC decoders may still scale it: check raw before use. Upstream default raw=255 (not necessarily valid data).";
CM_ SG_ 487 TivSetpoint "DATABASE_CANDIDATE: physical interpretation unverified; capture/layout evidence reported separately. PSA-RE bits 2.7-2.0. Setpoint time interval to the vehicle ahead (TIV) Raw invalid=255; numeric DBC decoders may still scale it: check raw before use. Upstream default raw=255 (not necessarily valid data).";
CM_ SG_ 487 Unused1 "DATABASE_CANDIDATE: physical interpretation unverified; capture/layout evidence reported separately. PSA-RE bits 1.0. ";
CM_ SG_ 487 ArtivTargetDetected "DATABASE_CANDIDATE: physical interpretation unverified; capture/layout evidence reported separately. PSA-RE bits 1.1. ARTIV target detected Upstream default raw=0 (not necessarily valid data).";
CM_ SG_ 487 ArtivAlertAdjustment "DATABASE_CANDIDATE: physical interpretation unverified; capture/layout evidence reported separately. PSA-RE bits 1.2. ARTIV alert adjustment Upstream default raw=0 (not necessarily valid data).";
CM_ SG_ 487 ArtivAlert "DATABASE_CANDIDATE: physical interpretation unverified; capture/layout evidence reported separately. PSA-RE bits 1.3. ARTIV alert Upstream default raw=0 (not necessarily valid data).";
CM_ SG_ 487 IhmArtivStatus "DATABASE_CANDIDATE: physical interpretation unverified; capture/layout evidence reported separately. PSA-RE bits 1.5-1.4. ARTIV display status Upstream default raw=0 (not necessarily valid data).";
CM_ SG_ 487 ArtivSelectionStatus "DATABASE_CANDIDATE: physical interpretation unverified; capture/layout evidence reported separately. PSA-RE bits 1.7-1.6. ARTIV selection status Upstream default raw=2 (not necessarily valid data).";
CM_ BO_ 488 "DATABASE_CANDIDATE: physical interpretation unverified; capture/layout evidence reported separately. INFO-DIV CAN, 125000 bit/s; CAN ID 0x1E8. PSA-RE title: ENGINE_MEAP_STATUS. Preconditioning and cruise-control/speed-limiter menu status: preconditioning activation and schedule time, five speed presets, recall request, availability. Source: https://github.com/prototux/PSA-RE/blob/67f7581e7622410efdbb29c7eda3b86982b9b450/buses/AEE2010.full/LS.INFO-DIV/1E8.yml. Source sender alternatives: ICSV,BSI; physical TX/gateway forwarding not verified. Observed 599 frames in info_apka.csv,info_buzeni_obc.csv,info_charging.csv,info_standby.csv,info_start_jizda.csv,infocan.csv; DLCs [8]. ";
CM_ SG_ 488 SpeedLimitZone5Speed "DATABASE_CANDIDATE: physical interpretation unverified; capture/layout evidence reported separately. PSA-RE bits 8.7-8.0. Speed limiter zone 5 speed value Upstream default raw=0 (not necessarily valid data).";
CM_ SG_ 488 SpeedLimitZone4Speed "DATABASE_CANDIDATE: physical interpretation unverified; capture/layout evidence reported separately. PSA-RE bits 7.7-7.0. Speed limiter zone 4 speed value Upstream default raw=0 (not necessarily valid data).";
CM_ SG_ 488 SpeedLimitZone3Speed "DATABASE_CANDIDATE: physical interpretation unverified; capture/layout evidence reported separately. PSA-RE bits 6.7-6.0. Speed limiter zone 3 speed value Upstream default raw=0 (not necessarily valid data).";
CM_ SG_ 488 SpeedLimitZone2Speed "DATABASE_CANDIDATE: physical interpretation unverified; capture/layout evidence reported separately. PSA-RE bits 5.7-5.0. Speed limiter zone 2 speed value Upstream default raw=0 (not necessarily valid data).";
CM_ SG_ 488 SpeedLimitZone1Speed "DATABASE_CANDIDATE: physical interpretation unverified; capture/layout evidence reported separately. PSA-RE bits 4.7-4.0. Speed limiter zone 1 speed value Upstream default raw=0 (not necessarily valid data).";
CM_ SG_ 488 SpeedLimitZone5State "DATABASE_CANDIDATE: physical interpretation unverified; capture/layout evidence reported separately. PSA-RE bits 3.0. Speed limiter zone 5 function state Upstream default raw=0 (not necessarily valid data).";
CM_ SG_ 488 SpeedLimitZone4State "DATABASE_CANDIDATE: physical interpretation unverified; capture/layout evidence reported separately. PSA-RE bits 3.1. Speed limiter zone 4 function state Upstream default raw=0 (not necessarily valid data).";
CM_ SG_ 488 SpeedLimitZone3State "DATABASE_CANDIDATE: physical interpretation unverified; capture/layout evidence reported separately. PSA-RE bits 3.2. Speed limiter zone 3 function state Upstream default raw=0 (not necessarily valid data).";
CM_ SG_ 488 SpeedLimitZone2State "DATABASE_CANDIDATE: physical interpretation unverified; capture/layout evidence reported separately. PSA-RE bits 3.3. Speed limiter zone 2 function state Upstream default raw=0 (not necessarily valid data).";
CM_ SG_ 488 SpeedLimitZone1State "DATABASE_CANDIDATE: physical interpretation unverified; capture/layout evidence reported separately. PSA-RE bits 3.4. Speed limiter zone 1 function state Upstream default raw=0 (not necessarily valid data).";
CM_ SG_ 488 CruiseLimiterProgramRecal_34492a "DATABASE_CANDIDATE: physical interpretation unverified; capture/layout evidence reported separately. PSA-RE bits 3.5. Programmable cruise/limiter recall request Upstream default raw=0 (not necessarily valid data).";
CM_ SG_ 488 SpeedLimitMainState "DATABASE_CANDIDATE: physical interpretation unverified; capture/layout evidence reported separately. PSA-RE bits 3.6. Speed limiter main function state Upstream default raw=0 (not necessarily valid data).";
CM_ SG_ 488 CruiseMenuInfoAvailability "DATABASE_CANDIDATE: physical interpretation unverified; capture/layout evidence reported separately. PSA-RE bits 3.7. Cruise control menu information availability Upstream default raw=0 (not necessarily valid data).";
CM_ SG_ 488 ThermalPrecondClock "DATABASE_CANDIDATE: physical interpretation unverified; capture/layout evidence reported separately. PSA-RE bits 1.3-2.0. Thermal preconditioning clock/timer Raw invalid=2047; numeric DBC decoders may still scale it: check raw before use. Upstream default raw=1440 (not necessarily valid data).";
CM_ SG_ 488 ThermalPrecondActive "DATABASE_CANDIDATE: physical interpretation unverified; capture/layout evidence reported separately. PSA-RE bits 1.4. Thermal preconditioning activation status Upstream default raw=0 (not necessarily valid data).";
CM_ SG_ 488 ThermalPrecondType "DATABASE_CANDIDATE: physical interpretation unverified; capture/layout evidence reported separately. PSA-RE bits 1.5. Type of thermal preconditioning: ventilation or preheating Upstream default raw=0 (not necessarily valid data).";
CM_ SG_ 488 CruiseLimiterProgramRecal_1d4300 "DATABASE_CANDIDATE: physical interpretation unverified; capture/layout evidence reported separately. PSA-RE bits 1.6. Update bit for the cruise/limiter program recall data Upstream default raw=0 (not necessarily valid data).";
CM_ SG_ 488 Unused1 "DATABASE_CANDIDATE: physical interpretation unverified; capture/layout evidence reported separately. PSA-RE bits 1.7. ";
CM_ BO_ 489 "DATABASE_CANDIDATE: physical interpretation unverified; capture/layout evidence reported separately. INFO-DIV CAN, 125000 bit/s; CAN ID 0x1E9. PSA-RE title: NAV_TRAFFIC_INFO. Navigation traffic information: advised/limit speed, radar warning pictograms and traffic alert distance/duration. Source: https://github.com/prototux/PSA-RE/blob/67f7581e7622410efdbb29c7eda3b86982b9b450/buses/AEE2010.full/LS.INFO-DIV/1E9.yml. Source sender alternatives: ICSV,BTEL,OVIP; physical TX/gateway forwarding not verified. ";
CM_ SG_ 489 NextTrafficSlowdownDistance "DATABASE_CANDIDATE: physical interpretation unverified; capture/layout evidence reported separately. PSA-RE bits 6.7-6.0. Distance to the next traffic slowdown Raw invalid=255; numeric DBC decoders may still scale it: check raw before use. Upstream default raw=255 (not necessarily valid data).";
CM_ SG_ 489 NextTrafficSlowdownDuration "DATABASE_CANDIDATE: physical interpretation unverified; capture/layout evidence reported separately. PSA-RE bits 5.7-5.0. Duration of the next traffic slowdown Raw invalid=255; numeric DBC decoders may still scale it: check raw before use. Upstream default raw=255 (not necessarily valid data).";
CM_ SG_ 489 Unused2 "DATABASE_CANDIDATE: physical interpretation unverified; capture/layout evidence reported separately. PSA-RE bits 4.1-4.0. ";
CM_ SG_ 489 SpeedCameraPoiPictogram2 "DATABASE_CANDIDATE: physical interpretation unverified; capture/layout evidence reported separately. PSA-RE bits 4.7-4.2. Speed-camera point-of-interest pictogram (2) Upstream default raw=0 (not necessarily valid data).";
CM_ SG_ 489 Unused1 "DATABASE_CANDIDATE: physical interpretation unverified; capture/layout evidence reported separately. PSA-RE bits 3.2-3.0. ";
CM_ SG_ 489 SpeedDisplayAuthorization "DATABASE_CANDIDATE: physical interpretation unverified; capture/layout evidence reported separately. PSA-RE bits 3.3. Speed display authorization Upstream default raw=0 (not necessarily valid data).";
CM_ SG_ 489 SpeedCameraPoiPictogram "DATABASE_CANDIDATE: physical interpretation unverified; capture/layout evidence reported separately. PSA-RE bits 3.7-3.4. Speed-camera point-of-interest pictogram Upstream default raw=0 (not necessarily valid data).";
CM_ SG_ 489 AdvisedSpeed "DATABASE_CANDIDATE: physical interpretation unverified; capture/layout evidence reported separately. PSA-RE bits 2.7-2.0. Advised speed Raw invalid=255; numeric DBC decoders may still scale it: check raw before use. Upstream default raw=255 (not necessarily valid data).";
CM_ SG_ 489 SpeedLimit "DATABASE_CANDIDATE: physical interpretation unverified; capture/layout evidence reported separately. PSA-RE bits 1.7-1.0. Speed limit Raw invalid=255; numeric DBC decoders may still scale it: check raw before use. Upstream default raw=255 (not necessarily valid data).";
CM_ BO_ 515 "DATABASE_CANDIDATE: physical interpretation unverified; capture/layout evidence reported separately. INFO-DIV CAN, 125000 bit/s; CAN ID 0x203. PSA-RE title: ODI_DYNAMIC_DATA_BUFFER. Opaque data buffer of the embedded diagnostics interface (ODI) between the telematics unit and the diagnostic tool: dynamic data. Source: https://github.com/prototux/PSA-RE/blob/67f7581e7622410efdbb29c7eda3b86982b9b450/buses/AEE2010.full/LS.INFO-DIV/203.yml. Source sender alternatives: MDS; physical TX/gateway forwarding not verified. ";
CM_ SG_ 515 OdiDynamicDataBuffer "DATABASE_CANDIDATE: physical interpretation unverified; capture/layout evidence reported separately. PSA-RE bits 1.7-8.0. Open Display Interface (ODI) dynamic data buffer";
CM_ BO_ 526 "DATABASE_CANDIDATE: physical interpretation unverified; capture/layout evidence reported separately. INFO-DIV CAN, 125000 bit/s; CAN ID 0x20E. PSA-RE title: SDCM_PAIRING_STATE. Pairing result and status code of the SDCM Source: https://github.com/prototux/PSA-RE/blob/67f7581e7622410efdbb29c7eda3b86982b9b450/buses/AEE2010.full/LS.INFO-DIV/20E.yml. Source sender alternatives: SDCM; physical TX/gateway forwarding not verified. ";
CM_ SG_ 526 Unused1 "DATABASE_CANDIDATE: physical interpretation unverified; capture/layout evidence reported separately. PSA-RE bits 1.2-1.0. ";
CM_ SG_ 526 SdcmPairingState "DATABASE_CANDIDATE: physical interpretation unverified; capture/layout evidence reported separately. PSA-RE bits 1.4-1.3. State of the smart device module (SDCM) pairing";
CM_ SG_ 526 SdcmPrivateCodePairingState "DATABASE_CANDIDATE: physical interpretation unverified; capture/layout evidence reported separately. PSA-RE bits 1.7-1.5. State of the smart device module (SDCM) private code pairing";
CM_ BO_ 535 "DATABASE_CANDIDATE: physical interpretation unverified; capture/layout evidence reported separately. INFO-DIV CAN, 125000 bit/s; CAN ID 0x217. PSA-RE title: ODOMETER_STATUS. Instrument cluster status to the body controller: hard-wired inputs acquired by the cluster (warnings, push-buttons, brake, fuel flap), fuel levels, lamp states, icon display, oil temperature, LPG state. Source: https://github.com/prototux/PSA-RE/blob/67f7581e7622410efdbb29c7eda3b86982b9b450/buses/AEE2010.full/LS.INFO-DIV/217.yml. Source sender alternatives: CMB,BTEL; physical TX/gateway forwarding not verified. VEHICLE_SOURCE_REVIEW: Owner reports original instrument cluster unit004 connected for info_buzeni_obc.csv and absent in earlier captures. This ID is absent in info_standby.csv and fully operational info_start_jizda.csv; upstream lists CMB among possible senders. Owner approved limiting IC attribution to these nine messages. Scope: Vehicle-specific sender attribution from installation report/capture comparison and compatible source alias; does not validate signal meanings or exclude gateway forwarding. Observed 4093 frames in info_buzeni_obc.csv,info_charging.csv; DLCs [8]. ";
CM_ SG_ 535 ClusterAppearance "DATABASE_CANDIDATE: physical interpretation unverified; capture/layout evidence reported separately. PSA-RE bits 8.7-8.0. Instrument cluster appearance/skin Raw invalid=255; numeric DBC decoders may still scale it: check raw before use. Upstream default raw=1 (not necessarily valid data).";
CM_ SG_ 535 AmbientLightingLevel "DATABASE_CANDIDATE: physical interpretation unverified; capture/layout evidence reported separately. PSA-RE bits 7.2-7.0. Ambient lighting level Upstream default raw=3 (not necessarily valid data).";
CM_ SG_ 535 AmbientLightButtonStatus "DATABASE_CANDIDATE: physical interpretation unverified; capture/layout evidence reported separately. PSA-RE bits 7.3. Ambience lighting push button status Upstream default raw=1 (not necessarily valid data).";
CM_ SG_ 535 MediaDisplayFault "DATABASE_CANDIDATE: physical interpretation unverified; capture/layout evidence reported separately. PSA-RE bits 7.4. Media display fault Upstream default raw=0 (not necessarily valid data).";
CM_ SG_ 535 DynamicModeChangeRequest "DATABASE_CANDIDATE: physical interpretation unverified; capture/layout evidence reported separately. PSA-RE bits 7.5. Dynamic mode state change request Upstream default raw=0 (not necessarily valid data).";
CM_ SG_ 535 EcoModeButtonPress "DATABASE_CANDIDATE: physical interpretation unverified; capture/layout evidence reported separately. PSA-RE bits 7.6. ECO mode push press Upstream default raw=0 (not necessarily valid data).";
CM_ SG_ 535 SttButtonStatus "DATABASE_CANDIDATE: physical interpretation unverified; capture/layout evidence reported separately. PSA-RE bits 7.7. Stop & Start push-button input Upstream default raw=0 (not necessarily valid data).";
CM_ SG_ 535 SpeedDisplayedOnCmb "DATABASE_CANDIDATE: physical interpretation unverified; capture/layout evidence reported separately. PSA-RE bits 6.7-6.0. Speed value displayed on the instrument cluster Raw invalid=255; numeric DBC decoders may still scale it: check raw before use. Upstream default raw=0 (not necessarily valid data).";
CM_ SG_ 535 ScpStateChangeRequest "DATABASE_CANDIDATE: physical interpretation unverified; capture/layout evidence reported separately. PSA-RE bits 5.0. Request to change the SCP state Upstream default raw=0 (not necessarily valid data).";
CM_ SG_ 535 MediaDisplayFaultArc "DATABASE_CANDIDATE: physical interpretation unverified; capture/layout evidence reported separately. PSA-RE bits 5.1. Media display fault reported by the ARC function Upstream default raw=0 (not necessarily valid data).";
CM_ SG_ 535 ArtivMinusButtonStatus "DATABASE_CANDIDATE: physical interpretation unverified; capture/layout evidence reported separately. PSA-RE bits 5.2. ARTIV setpoint decrease push-button input Upstream default raw=0 (not necessarily valid data).";
CM_ SG_ 535 ArtivPlusButtonStatus "DATABASE_CANDIDATE: physical interpretation unverified; capture/layout evidence reported separately. PSA-RE bits 5.3. ARTIV setpoint increase push-button input Upstream default raw=0 (not necessarily valid data).";
CM_ SG_ 535 MatrixMaintenanceResetRequest "DATABASE_CANDIDATE: physical interpretation unverified; capture/layout evidence reported separately. PSA-RE bits 5.4. Reset request for dot matrix display maintenance Upstream default raw=0 (not necessarily valid data).";
CM_ SG_ 535 ArtivButtonStatus "DATABASE_CANDIDATE: physical interpretation unverified; capture/layout evidence reported separately. PSA-RE bits 5.5. ARTIV push-button input Upstream default raw=0 (not necessarily valid data).";
CM_ SG_ 535 RequestPtcOn "DATABASE_CANDIDATE: physical interpretation unverified; capture/layout evidence reported separately. PSA-RE bits 5.6. Request to switch on the PTC (electric heating) element Upstream default raw=0 (not necessarily valid data).";
CM_ SG_ 535 TpmsButtonInput "DATABASE_CANDIDATE: physical interpretation unverified; capture/layout evidence reported separately. PSA-RE bits 5.7. Button input related to the tyre pressure monitoring system (DSG) Upstream default raw=0 (not necessarily valid data).";
CM_ SG_ 535 ResetTotal2 "DATABASE_CANDIDATE: physical interpretation unverified; capture/layout evidence reported separately. PSA-RE bits 4.0. Reset request for trip total 2 Upstream default raw=0 (not necessarily valid data).";
CM_ SG_ 535 AcCompressorMaxCapacityRequest "DATABASE_CANDIDATE: physical interpretation unverified; capture/layout evidence reported separately. PSA-RE bits 4.1. Request for the air conditioning compressor to run at maximum capacity Upstream default raw=0 (not necessarily valid data).";
CM_ SG_ 535 MpdButtonStatus "DATABASE_CANDIDATE: physical interpretation unverified; capture/layout evidence reported separately. PSA-RE bits 4.2. Parking space measurement (MPD) push-button input Upstream default raw=0 (not necessarily valid data).";
CM_ SG_ 535 SamButtonStatus "DATABASE_CANDIDATE: physical interpretation unverified; capture/layout evidence reported separately. PSA-RE bits 4.3. Blind spot monitoring push-button input Upstream default raw=0 (not necessarily valid data).";
CM_ SG_ 535 RearWindowHeaterButtonStatus "DATABASE_CANDIDATE: physical interpretation unverified; capture/layout evidence reported separately. PSA-RE bits 4.4. Heated rear window push-button input Upstream default raw=0 (not necessarily valid data).";
CM_ SG_ 535 AcOnButtonStatus "DATABASE_CANDIDATE: physical interpretation unverified; capture/layout evidence reported separately. PSA-RE bits 4.5. A/C on push-button input Upstream default raw=0 (not necessarily valid data).";
CM_ SG_ 535 SideTrajectoryButtonStatus "DATABASE_CANDIDATE: physical interpretation unverified; capture/layout evidence reported separately. PSA-RE bits 4.6. Lane departure warning push-button input Upstream default raw=0 (not necessarily valid data).";
CM_ SG_ 535 CafrButtonInput "DATABASE_CANDIDATE: physical interpretation unverified; capture/layout evidence reported separately. PSA-RE bits 4.7. CAFR button input state Upstream default raw=0 (not necessarily valid data).";
CM_ SG_ 535 Unused1 "DATABASE_CANDIDATE: physical interpretation unverified; capture/layout evidence reported separately. PSA-RE bits 3.1-3.0. ";
CM_ SG_ 535 FilteredPartialStatus "DATABASE_CANDIDATE: physical interpretation unverified; capture/layout evidence reported separately. PSA-RE bits 3.2. Filtered trip odometer reset push-button input Upstream default raw=0 (not necessarily valid data).";
CM_ SG_ 535 RequestMatrixCheck "DATABASE_CANDIDATE: physical interpretation unverified; capture/layout evidence reported separately. PSA-RE bits 3.3. Dot matrix display check request Upstream default raw=0 (not necessarily valid data).";
CM_ SG_ 535 AmvarButtonStatus "DATABASE_CANDIDATE: physical interpretation unverified; capture/layout evidence reported separately. PSA-RE bits 3.4. Sport AMVAR push-button input Upstream default raw=0 (not necessarily valid data).";
CM_ SG_ 535 ChildSafetyLockStatus "DATABASE_CANDIDATE: physical interpretation unverified; capture/layout evidence reported separately. PSA-RE bits 3.5. Child safety lock push-button input Upstream default raw=0 (not necessarily valid data).";
CM_ SG_ 535 EspButtonStatus "DATABASE_CANDIDATE: physical interpretation unverified; capture/layout evidence reported separately. PSA-RE bits 3.6. ESP push-button input Upstream default raw=0 (not necessarily valid data).";
CM_ SG_ 535 AasButtonStatus "DATABASE_CANDIDATE: physical interpretation unverified; capture/layout evidence reported separately. PSA-RE bits 3.7. Parking sensor (AAS) push-button input Upstream default raw=0 (not necessarily valid data).";
CM_ SG_ 535 DistanceUnit "DATABASE_CANDIDATE: physical interpretation unverified; capture/layout evidence reported separately. PSA-RE bits 2.0. Distance unit displayed on the instrument cluster Upstream default raw=0 (not necessarily valid data).";
CM_ SG_ 535 ResetPartial "DATABASE_CANDIDATE: physical interpretation unverified; capture/layout evidence reported separately. PSA-RE bits 2.1. Reset of the partial (trip) odometer requested Upstream default raw=0 (not necessarily valid data).";
CM_ SG_ 535 ResetTotal1 "DATABASE_CANDIDATE: physical interpretation unverified; capture/layout evidence reported separately. PSA-RE bits 2.2. Reset request for trip total 1 Upstream default raw=0 (not necessarily valid data).";
CM_ SG_ 535 ClusterFault "DATABASE_CANDIDATE: physical interpretation unverified; capture/layout evidence reported separately. PSA-RE bits 2.3. Instrument cluster fault Upstream default raw=0 (not necessarily valid data).";
CM_ SG_ 535 AutoCheck "DATABASE_CANDIDATE: physical interpretation unverified; capture/layout evidence reported separately. PSA-RE bits 2.4. Automatic check request Upstream default raw=0 (not necessarily valid data).";
CM_ SG_ 535 CheckRequested "DATABASE_CANDIDATE: physical interpretation unverified; capture/layout evidence reported separately. PSA-RE bits 2.5. Requested alert check sequence Upstream default raw=0 (not necessarily valid data).";
CM_ SG_ 535 AirbagFaultStatus "DATABASE_CANDIDATE: physical interpretation unverified; capture/layout evidence reported separately. PSA-RE bits 2.7-2.6. Airbag fault signaling to the driver display Upstream default raw=2 (not necessarily valid data).";
CM_ SG_ 535 AirbagInhibitionStatus "DATABASE_CANDIDATE: physical interpretation unverified; capture/layout evidence reported separately. PSA-RE bits 1.1-1.0. Airbag inhibition signaling to the driver display Upstream default raw=2 (not necessarily valid data).";
CM_ SG_ 535 MaintenanceResetRequest "DATABASE_CANDIDATE: physical interpretation unverified; capture/layout evidence reported separately. PSA-RE bits 1.2. Maintenance reset requested Upstream default raw=0 (not necessarily valid data).";
CM_ SG_ 535 DarkStatus "DATABASE_CANDIDATE: physical interpretation unverified; capture/layout evidence reported separately. PSA-RE bits 1.3. Black panel (night dimmed) mode request Upstream default raw=0 (not necessarily valid data).";
CM_ SG_ 535 Luminosity "DATABASE_CANDIDATE: physical interpretation unverified; capture/layout evidence reported separately. PSA-RE bits 1.7-1.4. Brightness level required by the instrument cluster (0-15) Upstream default raw=8 (not necessarily valid data).";
CM_ BO_ 539 "DATABASE_CANDIDATE: physical interpretation unverified; capture/layout evidence reported separately. INFO-DIV CAN, 125000 bit/s; CAN ID 0x21B. PSA-RE title: PROFILE_SETTINGS_SCREEN_2. Driver profile and settings screen requests (part 2): ambient lighting animation and colour, privacy mode. Source: https://github.com/prototux/PSA-RE/blob/67f7581e7622410efdbb29c7eda3b86982b9b450/buses/AEE2010.full/LS.INFO-DIV/21B.yml. Source sender alternatives: RAD,MATT,BTEL,CMB,ICSV,OVIP,EMF; physical TX/gateway forwarding not verified. ";
CM_ SG_ 539 RawByte5 "RAW. PSA-RE bits 5.7-5.0. Unmapped/padding bits, no physical interpretation.";
CM_ SG_ 539 RawByte4 "RAW. PSA-RE bits 4.7-4.0. Unmapped/padding bits, no physical interpretation.";
CM_ SG_ 539 Unused3 "DATABASE_CANDIDATE: physical interpretation unverified; capture/layout evidence reported separately. PSA-RE bits 3.3-3.0. ";
CM_ SG_ 539 Unused2 "DATABASE_CANDIDATE: physical interpretation unverified; capture/layout evidence reported separately. PSA-RE bits 3.4. ";
CM_ SG_ 539 AdsdActivationRequest "DATABASE_CANDIDATE: physical interpretation unverified; capture/layout evidence reported separately. PSA-RE bits 3.5. Request to activate the ADSD function Upstream default raw=0 (not necessarily valid data).";
CM_ SG_ 539 PrivacyModeSelection "DATABASE_CANDIDATE: physical interpretation unverified; capture/layout evidence reported separately. PSA-RE bits 3.7-3.6. Request to activate the privacy mode function Upstream default raw=2 (not necessarily valid data).";
CM_ SG_ 539 PolychromeLightBlock1Acti_b37910 "DATABASE_CANDIDATE: physical interpretation unverified; capture/layout evidence reported separately. PSA-RE bits 2.0. Request to activate block 1 of the polychrome light pack function Upstream default raw=0 (not necessarily valid data).";
CM_ SG_ 539 PolychromeLightColor1Selection "DATABASE_CANDIDATE: physical interpretation unverified; capture/layout evidence reported separately. PSA-RE bits 2.3-2.1. Selection of color 1 of the polychrome light pack function Upstream default raw=0 (not necessarily valid data).";
CM_ SG_ 539 PolychromeLightAnimationS_c6fde1 "DATABASE_CANDIDATE: physical interpretation unverified; capture/layout evidence reported separately. PSA-RE bits 2.7-2.4. Selection of the polychrome light pack animation Upstream default raw=0 (not necessarily valid data).";
CM_ SG_ 539 Unused1 "DATABASE_CANDIDATE: physical interpretation unverified; capture/layout evidence reported separately. PSA-RE bits 1.7-1.0. ";
CM_ BO_ 543 "DATABASE_CANDIDATE: physical interpretation unverified; capture/layout evidence reported separately. INFO-DIV CAN, 125000 bit/s; CAN ID 0x21F. PSA-RE title: RADIO_COMMANDS_2. Used by the BSI as a monitoring frame for equipment functionally linked to it on the body network; carries steering column radio control commands from the top-of-column module. Source: https://github.com/prototux/PSA-RE/blob/67f7581e7622410efdbb29c7eda3b86982b9b450/buses/AEE2010.full/LS.INFO-DIV/21F.yml. Source sender alternatives: BSI; physical TX/gateway forwarding not verified. Observed 5869 frames in info_apka.csv,info_buzeni_obc.csv,info_charging.csv,info_standby.csv,info_start_jizda.csv,infocan.csv; DLCs [3]. ";
CM_ SG_ 543 Unused2 "DATABASE_CANDIDATE: physical interpretation unverified; capture/layout evidence reported separately. PSA-RE bits 3.1-3.0. ";
CM_ SG_ 543 Unused1 "DATABASE_CANDIDATE: physical interpretation unverified; capture/layout evidence reported separately. PSA-RE bits 3.2. ";
CM_ SG_ 543 ListMinusButtonPress "DATABASE_CANDIDATE: physical interpretation unverified; capture/layout evidence reported separately. PSA-RE bits 3.3. List- button press (steering wheel controls) Upstream default raw=0 (not necessarily valid data).";
CM_ SG_ 543 ListPlusButtonPress "DATABASE_CANDIDATE: physical interpretation unverified; capture/layout evidence reported separately. PSA-RE bits 3.4. List+ button press (steering wheel controls) Upstream default raw=0 (not necessarily valid data).";
CM_ SG_ 543 VoiceRecognitionButtonPress "DATABASE_CANDIDATE: physical interpretation unverified; capture/layout evidence reported separately. PSA-RE bits 3.5. Voice recognition button press (steering wheel controls) Upstream default raw=0 (not necessarily valid data).";
CM_ SG_ 543 SourceButtonPress "DATABASE_CANDIDATE: physical interpretation unverified; capture/layout evidence reported separately. PSA-RE bits 3.6. Source button press (steering wheel controls) Upstream default raw=0 (not necessarily valid data).";
CM_ SG_ 543 RadioCommandValidation "DATABASE_CANDIDATE: physical interpretation unverified; capture/layout evidence reported separately. PSA-RE bits 3.7. Radio command validation Upstream default raw=0 (not necessarily valid data).";
CM_ SG_ 543 Scroll "DATABASE_CANDIDATE: physical interpretation unverified; capture/layout evidence reported separately. PSA-RE bits 2.7-2.0. SCAN thumbwheel step counter (-128 to +127) Upstream default raw=0 (not necessarily valid data).";
CM_ SG_ 543 List "DATABASE_CANDIDATE: physical interpretation unverified; capture/layout evidence reported separately. PSA-RE bits 1.0. List button press Upstream default raw=0 (not necessarily valid data).";
CM_ SG_ 543 Src "DATABASE_CANDIDATE: physical interpretation unverified; capture/layout evidence reported separately. PSA-RE bits 1.1. Mode/phone button press Upstream default raw=0 (not necessarily valid data).";
CM_ SG_ 543 VolDown "DATABASE_CANDIDATE: physical interpretation unverified; capture/layout evidence reported separately. PSA-RE bits 1.2. Volume down button press Upstream default raw=0 (not necessarily valid data).";
CM_ SG_ 543 VolUp "DATABASE_CANDIDATE: physical interpretation unverified; capture/layout evidence reported separately. PSA-RE bits 1.3. Volume up button press Upstream default raw=0 (not necessarily valid data).";
CM_ SG_ 543 OverflowScrollDown "DATABASE_CANDIDATE: physical interpretation unverified; capture/layout evidence reported separately. PSA-RE bits 1.4. Scroll down (SCAN-) counter overflow Upstream default raw=0 (not necessarily valid data).";
CM_ SG_ 543 OverflowScrollUp "DATABASE_CANDIDATE: physical interpretation unverified; capture/layout evidence reported separately. PSA-RE bits 1.5. Scroll up (SCAN+) counter overflow Upstream default raw=0 (not necessarily valid data).";
CM_ SG_ 543 SeekDown "DATABASE_CANDIDATE: physical interpretation unverified; capture/layout evidence reported separately. PSA-RE bits 1.6. Seek down (search backward) button press Upstream default raw=0 (not necessarily valid data).";
CM_ SG_ 543 SeekUp "DATABASE_CANDIDATE: physical interpretation unverified; capture/layout evidence reported separately. PSA-RE bits 1.7. Seek up (search forward) button press Upstream default raw=0 (not necessarily valid data).";
CM_ BO_ 544 "DATABASE_CANDIDATE: physical interpretation unverified; capture/layout evidence reported separately. INFO-DIV CAN, 125000 bit/s; CAN ID 0x220. PSA-RE title: VEHICLE_PERSONALIZATION_STATUS. Personalization profile information (units, language, welcome animation, ambient lighting): active settings and menu states, defined by the profile message structure. Source: https://github.com/prototux/PSA-RE/blob/67f7581e7622410efdbb29c7eda3b86982b9b450/buses/AEE2010.full/LS.INFO-DIV/220.yml. Source sender alternatives: BSI; physical TX/gateway forwarding not verified. Observed 1173 frames in info_apka.csv,info_buzeni_obc.csv,info_charging.csv,info_standby.csv,info_start_jizda.csv,infocan.csv; DLCs [5]. ";
CM_ SG_ 544 RawByte5 "RAW. PSA-RE bits 5.7-5.0. Unmapped/padding bits, no physical interpretation.";
CM_ SG_ 544 RawByte4 "RAW. PSA-RE bits 4.7-4.0. Unmapped/padding bits, no physical interpretation.";
CM_ SG_ 544 Unused3 "DATABASE_CANDIDATE: physical interpretation unverified; capture/layout evidence reported separately. PSA-RE bits 3.3-3.0. ";
CM_ SG_ 544 Unused2 "DATABASE_CANDIDATE: physical interpretation unverified; capture/layout evidence reported separately. PSA-RE bits 3.4. ";
CM_ SG_ 544 AdsdFunctionActive "DATABASE_CANDIDATE: physical interpretation unverified; capture/layout evidence reported separately. PSA-RE bits 3.5. Memorized activation status of the ADSD function Upstream default raw=0 (not necessarily valid data).";
CM_ SG_ 544 PrivacyModeStatus "DATABASE_CANDIDATE: physical interpretation unverified; capture/layout evidence reported separately. PSA-RE bits 3.7-3.6. Memorized activation status of the Privacy mode function Upstream default raw=2 (not necessarily valid data).";
CM_ SG_ 544 PolychromePackBlock1Funct_d87010 "DATABASE_CANDIDATE: physical interpretation unverified; capture/layout evidence reported separately. PSA-RE bits 2.0. Memorized activation status of block 1 of the \"polychrome pack\" function Upstream default raw=0 (not necessarily valid data).";
CM_ SG_ 544 PolychromePackColor1Status "DATABASE_CANDIDATE: physical interpretation unverified; capture/layout evidence reported separately. PSA-RE bits 2.3-2.1. Memorized colour 1 setting of the polychrome pack function Upstream default raw=0 (not necessarily valid data).";
CM_ SG_ 544 PolychromePackAnimationIt_656116 "DATABASE_CANDIDATE: physical interpretation unverified; capture/layout evidence reported separately. PSA-RE bits 2.7-2.4. Polychrome pack animation item status Upstream default raw=0 (not necessarily valid data).";
CM_ SG_ 544 Unused1 "DATABASE_CANDIDATE: physical interpretation unverified; capture/layout evidence reported separately. PSA-RE bits 1.7-1.0. ";
CM_ BO_ 545 "DATABASE_CANDIDATE: physical interpretation unverified; capture/layout evidence reported separately. INFO-DIV CAN, 125000 bit/s; CAN ID 0x221. PSA-RE title: TRIP_GENERAL_INFOS. General trip-computer information: instant and trip consumption, remaining range and reset button presses. Source: https://github.com/prototux/PSA-RE/blob/67f7581e7622410efdbb29c7eda3b86982b9b450/buses/AEE2010.full/LS.INFO-DIV/221.yml. Source sender alternatives: BSI; physical TX/gateway forwarding not verified. Observed 577 frames in info_apka.csv,info_buzeni_obc.csv,info_charging.csv,info_standby.csv,info_start_jizda.csv,infocan.csv; DLCs [7]. ";
CM_ SG_ 545 TripDistLeft "DATABASE_CANDIDATE: physical interpretation unverified; capture/layout evidence reported separately. PSA-RE bits 6.7-7.0. Distance remaining on the current course Raw invalid=65535; numeric DBC decoders may still scale it: check raw before use.";
CM_ SG_ 545 Autonomy "DATABASE_CANDIDATE: physical interpretation unverified; capture/layout evidence reported separately. PSA-RE bits 4.7-5.0. Residual range Raw invalid=65535; numeric DBC decoders may still scale it: check raw before use. Upstream default raw=65535 (not necessarily valid data).";
CM_ SG_ 545 TripInstantFuelConsumption "DATABASE_CANDIDATE: physical interpretation unverified; capture/layout evidence reported separately. PSA-RE bits 2.7-3.0. Instantaneous fuel consumption Raw invalid=65535; numeric DBC decoders may still scale it: check raw before use. Upstream default raw=65535 (not necessarily valid data).";
CM_ SG_ 545 NavigationPushButton "DATABASE_CANDIDATE: physical interpretation unverified; capture/layout evidence reported separately. PSA-RE bits 1.0. State of the navigation/voice recognition message reminder push-button";
CM_ SG_ 545 Unused2 "DATABASE_CANDIDATE: physical interpretation unverified; capture/layout evidence reported separately. PSA-RE bits 1.2-1.1. ";
CM_ SG_ 545 TripPushButton "DATABASE_CANDIDATE: physical interpretation unverified; capture/layout evidence reported separately. PSA-RE bits 1.3. State of the trip computer scrolling push-button";
CM_ SG_ 545 Unused1 "DATABASE_CANDIDATE: physical interpretation unverified; capture/layout evidence reported separately. PSA-RE bits 1.4. ";
CM_ SG_ 545 SteeringWheelPageRotationStatus "DATABASE_CANDIDATE: physical interpretation unverified; capture/layout evidence reported separately. PSA-RE bits 1.5. Status of pressing the steering wheel button for combination instrument page rotation Upstream default raw=0 (not necessarily valid data).";
CM_ SG_ 545 CheckAutonomy "DATABASE_CANDIDATE: physical interpretation unverified; capture/layout evidence reported separately. PSA-RE bits 1.6. Invalid range";
CM_ SG_ 545 CheckConsumption "DATABASE_CANDIDATE: physical interpretation unverified; capture/layout evidence reported separately. PSA-RE bits 1.7. Invalid consumption";
CM_ BO_ 547 "DATABASE_CANDIDATE: physical interpretation unverified; capture/layout evidence reported separately. INFO-DIV CAN, 125000 bit/s; CAN ID 0x223. PSA-RE title: HANDSFREE_KIT_CALL_DURATION. Hands-free kit call duration timers (hours, minutes, seconds) for two calls. Source: https://github.com/prototux/PSA-RE/blob/67f7581e7622410efdbb29c7eda3b86982b9b450/buses/AEE2010.full/LS.INFO-DIV/223.yml. Source sender alternatives: RAD,ICSV; physical TX/gateway forwarding not verified. ";
CM_ SG_ 547 Unused8 "DATABASE_CANDIDATE: physical interpretation unverified; capture/layout evidence reported separately. PSA-RE bits 8.2-8.0. ";
CM_ SG_ 547 AutoReply2Time "DATABASE_CANDIDATE: physical interpretation unverified; capture/layout evidence reported separately. PSA-RE bits 8.7-8.3. Duration of the automatic reply 2 Raw invalid=31; numeric DBC decoders may still scale it: check raw before use.";
CM_ SG_ 547 Unused7 "DATABASE_CANDIDATE: physical interpretation unverified; capture/layout evidence reported separately. PSA-RE bits 7.2-7.0. ";
CM_ SG_ 547 AutoReply1Time "DATABASE_CANDIDATE: physical interpretation unverified; capture/layout evidence reported separately. PSA-RE bits 7.7-7.3. Duration of the automatic reply 1 Raw invalid=31; numeric DBC decoders may still scale it: check raw before use.";
CM_ SG_ 547 Unused6 "DATABASE_CANDIDATE: physical interpretation unverified; capture/layout evidence reported separately. PSA-RE bits 6.1-6.0. ";
CM_ SG_ 547 SecondCallSeconds "DATABASE_CANDIDATE: physical interpretation unverified; capture/layout evidence reported separately. PSA-RE bits 6.7-6.2. Seconds of the second call (not total duration) Raw invalid=63; numeric DBC decoders may still scale it: check raw before use.";
CM_ SG_ 547 Unused5 "DATABASE_CANDIDATE: physical interpretation unverified; capture/layout evidence reported separately. PSA-RE bits 5.1-5.0. ";
CM_ SG_ 547 SecondCallMinutes "DATABASE_CANDIDATE: physical interpretation unverified; capture/layout evidence reported separately. PSA-RE bits 5.7-5.2. Minutes of the second call (not total duration) Raw invalid=63; numeric DBC decoders may still scale it: check raw before use.";
CM_ SG_ 547 Unused4 "DATABASE_CANDIDATE: physical interpretation unverified; capture/layout evidence reported separately. PSA-RE bits 4.2-4.0. ";
CM_ SG_ 547 SecondCallHours "DATABASE_CANDIDATE: physical interpretation unverified; capture/layout evidence reported separately. PSA-RE bits 4.7-4.3. Hours of the second call (not total duration) Raw invalid=31; numeric DBC decoders may still scale it: check raw before use.";
CM_ SG_ 547 Unused3 "DATABASE_CANDIDATE: physical interpretation unverified; capture/layout evidence reported separately. PSA-RE bits 3.1-3.0. ";
CM_ SG_ 547 FirstCallSeconds "DATABASE_CANDIDATE: physical interpretation unverified; capture/layout evidence reported separately. PSA-RE bits 3.7-3.2. Seconds of the first call (not total duration) Raw invalid=63; numeric DBC decoders may still scale it: check raw before use.";
CM_ SG_ 547 Unused2 "DATABASE_CANDIDATE: physical interpretation unverified; capture/layout evidence reported separately. PSA-RE bits 2.1-2.0. ";
CM_ SG_ 547 FirstCallMinutes "DATABASE_CANDIDATE: physical interpretation unverified; capture/layout evidence reported separately. PSA-RE bits 2.7-2.2. Minutes of the first call (not total duration) Raw invalid=63; numeric DBC decoders may still scale it: check raw before use.";
CM_ SG_ 547 Unused1 "DATABASE_CANDIDATE: physical interpretation unverified; capture/layout evidence reported separately. PSA-RE bits 1.2-1.0. ";
CM_ SG_ 547 FirstCallHours "DATABASE_CANDIDATE: physical interpretation unverified; capture/layout evidence reported separately. PSA-RE bits 1.7-1.3. Hours of the first call (not total duration) Raw invalid=31; numeric DBC decoders may still scale it: check raw before use.";
CM_ BO_ 548 "DATABASE_CANDIDATE: physical interpretation unverified; capture/layout evidence reported separately. INFO-DIV CAN, 125000 bit/s; CAN ID 0x224. PSA-RE title: RADIO_STATUS_AUDIO_SURROUND. Audio surround settings: mid, subwoofer, surround and centre-channel levels, and auxiliary level adjustment (AAS). Source: https://github.com/prototux/PSA-RE/blob/67f7581e7622410efdbb29c7eda3b86982b9b450/buses/AEE2010.full/LS.INFO-DIV/224.yml. Source sender alternatives: BTEL,OVIP; physical TX/gateway forwarding not verified. Observed 1173 frames in info_apka.csv,info_buzeni_obc.csv,info_charging.csv,info_standby.csv,info_start_jizda.csv,infocan.csv; DLCs [3]. ";
CM_ SG_ 548 Unused2 "DATABASE_CANDIDATE: physical interpretation unverified; capture/layout evidence reported separately. PSA-RE bits 3.4-3.0. ";
CM_ SG_ 548 AasBeepLevelAdjustment "DATABASE_CANDIDATE: physical interpretation unverified; capture/layout evidence reported separately. PSA-RE bits 3.7-3.5. Adjustment of the level of beep AAS Raw invalid=0; numeric DBC decoders may still scale it: check raw before use. Upstream default raw=0 (not necessarily valid data).";
CM_ SG_ 548 Unused1 "DATABASE_CANDIDATE: physical interpretation unverified; capture/layout evidence reported separately. PSA-RE bits 2.1-2.0. ";
CM_ SG_ 548 SurroundLevel "DATABASE_CANDIDATE: physical interpretation unverified; capture/layout evidence reported separately. PSA-RE bits 2.3-2.2. Flow determining the efficiency level of the SURROUND Upstream default raw=0 (not necessarily valid data).";
CM_ SG_ 548 CenterChannelLevel "DATABASE_CANDIDATE: physical interpretation unverified; capture/layout evidence reported separately. PSA-RE bits 2.7-2.4. Flow determining the regulation level of the Central Way Upstream default raw=7 (not necessarily valid data).";
CM_ SG_ 548 SubwooferLevel "DATABASE_CANDIDATE: physical interpretation unverified; capture/layout evidence reported separately. PSA-RE bits 1.3-1.0. Flow determining the regulation level of the Subwoofer Upstream default raw=7 (not necessarily valid data).";
CM_ SG_ 548 MidrangeValue "DATABASE_CANDIDATE: physical interpretation unverified; capture/layout evidence reported separately. PSA-RE bits 1.7-1.4. Current level of midrange setpoint Upstream default raw=7 (not necessarily valid data).";
CM_ BO_ 549 "DATABASE_CANDIDATE: physical interpretation unverified; capture/layout evidence reported separately. INFO-DIV CAN, 125000 bit/s; CAN ID 0x225. PSA-RE title: RADIO_STATUS_TUNER. Tuner status: bank/preset number, search direction, frequency, PTY list validity/content, manual tuning and search state. Source: https://github.com/prototux/PSA-RE/blob/67f7581e7622410efdbb29c7eda3b86982b9b450/buses/AEE2010.full/LS.INFO-DIV/225.yml. Source sender alternatives: RAD,ICSV; physical TX/gateway forwarding not verified. ";
CM_ SG_ 549 Unused3 "DATABASE_CANDIDATE: physical interpretation unverified; capture/layout evidence reported separately. PSA-RE bits 6.0. ";
CM_ SG_ 549 ListStatus "DATABASE_CANDIDATE: physical interpretation unverified; capture/layout evidence reported separately. PSA-RE bits 6.1. list status Upstream default raw=0 (not necessarily valid data).";
CM_ SG_ 549 StationMemorizationStatus "DATABASE_CANDIDATE: physical interpretation unverified; capture/layout evidence reported separately. PSA-RE bits 6.3-6.2. Radio station memorization status Upstream default raw=0 (not necessarily valid data).";
CM_ SG_ 549 EncodingFormat "DATABASE_CANDIDATE: physical interpretation unverified; capture/layout evidence reported separately. PSA-RE bits 6.7-6.4. Encoding format Upstream default raw=0 (not necessarily valid data).";
CM_ SG_ 549 Unused2 "DATABASE_CANDIDATE: physical interpretation unverified; capture/layout evidence reported separately. PSA-RE bits 5.0. ";
CM_ SG_ 549 StereoType "DATABASE_CANDIDATE: physical interpretation unverified; capture/layout evidence reported separately. PSA-RE bits 5.3-5.1. Type of stereo Upstream default raw=0 (not necessarily valid data).";
CM_ SG_ 549 AudioStreamBitrate "DATABASE_CANDIDATE: physical interpretation unverified; capture/layout evidence reported separately. PSA-RE bits 5.7-5.4. Audio stream rate Upstream default raw=0 (not necessarily valid data).";
CM_ SG_ 549 TunerLevel "DATABASE_CANDIDATE: physical interpretation unverified; capture/layout evidence reported separately. PSA-RE bits 4.7-4.0. Tuner level Raw invalid=255; numeric DBC decoders may still scale it: check raw before use. Upstream default raw=255 (not necessarily valid data).";
CM_ SG_ 549 Frequency "DATABASE_CANDIDATE: physical interpretation unverified; capture/layout evidence reported separately. PSA-RE bits 2.2-3.0. Controlling the number of steps in relation to the starting frequency Raw invalid=2047; numeric DBC decoders may still scale it: check raw before use. Upstream default raw=2047 (not necessarily valid data).";
CM_ SG_ 549 Unused1 "DATABASE_CANDIDATE: physical interpretation unverified; capture/layout evidence reported separately. PSA-RE bits 2.4-2.3. ";
CM_ SG_ 549 Band "DATABASE_CANDIDATE: physical interpretation unverified; capture/layout evidence reported separately. PSA-RE bits 2.7-2.5. Selected memory bank Upstream default raw=7 (not necessarily valid data).";
CM_ SG_ 549 CurrentMemory "DATABASE_CANDIDATE: physical interpretation unverified; capture/layout evidence reported separately. PSA-RE bits 1.3-1.0. Number of active memory Upstream default raw=0 (not necessarily valid data).";
CM_ SG_ 549 SearchStatus "DATABASE_CANDIDATE: physical interpretation unverified; capture/layout evidence reported separately. PSA-RE bits 1.7-1.4. Station research ordering Upstream default raw=0 (not necessarily valid data).";
CM_ BO_ 551 "DATABASE_CANDIDATE: physical interpretation unverified; capture/layout evidence reported separately. INFO-DIV CAN, 125000 bit/s; CAN ID 0x227. PSA-RE title: PUSH_BUTTON_LED_CONTROL. Lighting requests for the push button LEDs (parking aid, climate, ESP, parking brake, gear-lock, driving mode, child lock). Source: https://github.com/prototux/PSA-RE/blob/67f7581e7622410efdbb29c7eda3b86982b9b450/buses/AEE2010.full/LS.INFO-DIV/227.yml. Source sender alternatives: BSI; physical TX/gateway forwarding not verified. Observed 1182 frames in info_apka.csv,info_buzeni_obc.csv,info_charging.csv,info_standby.csv,info_start_jizda.csv,infocan.csv; DLCs [8]. ";
CM_ SG_ 551 RawByte8 "RAW. PSA-RE bits 8.7-8.0. Unmapped/padding bits, no physical interpretation.";
CM_ SG_ 551 Unused1 "DATABASE_CANDIDATE: physical interpretation unverified; capture/layout evidence reported separately. PSA-RE bits 7.6-7.0. ";
CM_ SG_ 551 AvasSoundEmissionRequest "DATABASE_CANDIDATE: physical interpretation unverified; capture/layout evidence reported separately. PSA-RE bits 7.7. AVAS sound emission request Upstream default raw=0 (not necessarily valid data).";
CM_ SG_ 551 EnergyRecoverPushLed "DATABASE_CANDIDATE: physical interpretation unverified; capture/layout evidence reported separately. PSA-RE bits 6.0. Energy recovery push button LED lighting Upstream default raw=0 (not necessarily valid data).";
CM_ SG_ 551 AvasPushLed "DATABASE_CANDIDATE: physical interpretation unverified; capture/layout evidence reported separately. PSA-RE bits 6.1. AVAS push button LED lighting Upstream default raw=0 (not necessarily valid data).";
CM_ SG_ 551 EcoModePushLedState "DATABASE_CANDIDATE: physical interpretation unverified; capture/layout evidence reported separately. PSA-RE bits 6.3-6.2. ECO mode push button LED state Upstream default raw=0 (not necessarily valid data).";
CM_ SG_ 551 NightVisionPushLedControl "DATABASE_CANDIDATE: physical interpretation unverified; capture/layout evidence reported separately. PSA-RE bits 6.5-6.4. Night vision push button LED lighting request Upstream default raw=0 (not necessarily valid data).";
CM_ SG_ 551 LpaPushLedControl "DATABASE_CANDIDATE: physical interpretation unverified; capture/layout evidence reported separately. PSA-RE bits 6.7-6.6. LPA push button LED lighting command Upstream default raw=0 (not necessarily valid data).";
CM_ SG_ 551 WelcomeLightLedMode "DATABASE_CANDIDATE: physical interpretation unverified; capture/layout evidence reported separately. PSA-RE bits 5.0. Welcome lighting LED status control for roof light (automatic/manual) Upstream default raw=0 (not necessarily valid data).";
CM_ SG_ 551 AutoWipeLedFeedback "DATABASE_CANDIDATE: physical interpretation unverified; capture/layout evidence reported separately. PSA-RE bits 5.2-5.1. Automatic wiping activation button LED feedback Upstream default raw=0 (not necessarily valid data).";
CM_ SG_ 551 HadcPushLedRequest "DATABASE_CANDIDATE: physical interpretation unverified; capture/layout evidence reported separately. PSA-RE bits 5.3. HADC push button LED lighting request Upstream default raw=0 (not necessarily valid data).";
CM_ SG_ 551 LkaPushLedControl "DATABASE_CANDIDATE: physical interpretation unverified; capture/layout evidence reported separately. PSA-RE bits 5.5-5.4. LKA (lane keeping assist) indicator light command Upstream default raw=0 (not necessarily valid data).";
CM_ SG_ 551 FunctionSelectPushLed "DATABASE_CANDIDATE: physical interpretation unverified; capture/layout evidence reported separately. PSA-RE bits 5.7-5.6. Function selection push button indicator control Upstream default raw=0 (not necessarily valid data).";
CM_ SG_ 551 DynamicPackLedRequest "DATABASE_CANDIDATE: physical interpretation unverified; capture/layout evidence reported separately. PSA-RE bits 4.1-4.0. Dynamic pack button LED lighting request Upstream default raw=0 (not necessarily valid data).";
CM_ SG_ 551 StartStopPushLedControl "DATABASE_CANDIDATE: physical interpretation unverified; capture/layout evidence reported separately. PSA-RE bits 4.3-4.2. STT (stop & start) push button LED lighting request Upstream default raw=0 (not necessarily valid data).";
CM_ SG_ 551 CafrPushLedControl "DATABASE_CANDIDATE: physical interpretation unverified; capture/layout evidence reported separately. PSA-RE bits 4.4. CAFR push button LED lighting request Upstream default raw=0 (not necessarily valid data).";
CM_ SG_ 551 ArtivPushLedControl "DATABASE_CANDIDATE: physical interpretation unverified; capture/layout evidence reported separately. PSA-RE bits 4.6-4.5. ARTIV push button LED lighting request Upstream default raw=0 (not necessarily valid data).";
CM_ SG_ 551 RecyclAirEtVmf "DATABASE_CANDIDATE: physical interpretation unverified; capture/layout evidence reported separately. PSA-RE bits 4.7. Air conditioning air recycling flap command Upstream default raw=0 (not necessarily valid data).";
CM_ SG_ 551 BlindSpotMonitoringPushLe_c23e79 "DATABASE_CANDIDATE: physical interpretation unverified; capture/layout evidence reported separately. PSA-RE bits 3.1-3.0. Blind spot monitoring push button LED lighting request Upstream default raw=0 (not necessarily valid data).";
CM_ SG_ 551 AirConditioningShutterControl "DATABASE_CANDIDATE: physical interpretation unverified; capture/layout evidence reported separately. PSA-RE bits 3.3-3.2. Air conditioning air inlet shutter control request Upstream default raw=0 (not necessarily valid data).";
CM_ SG_ 551 PetrolOrDieselInformation "DATABASE_CANDIDATE: physical interpretation unverified; capture/layout evidence reported separately. PSA-RE bits 3.5-3.4. Petrol or diesel engine information Upstream default raw=1 (not necessarily valid data).";
CM_ SG_ 551 StopAndStartPushLedControl "DATABASE_CANDIDATE: physical interpretation unverified; capture/layout evidence reported separately. PSA-RE bits 3.7-3.6. Stop & Start push button LED lighting request Upstream default raw=0 (not necessarily valid data).";
CM_ SG_ 551 AcPushLedControl "DATABASE_CANDIDATE: physical interpretation unverified; capture/layout evidence reported separately. PSA-RE bits 2.1-2.0. AC/ON push button LED lighting request Upstream default raw=0 (not necessarily valid data).";
CM_ SG_ 551 RearWindowHeatingPushLedControl "DATABASE_CANDIDATE: physical interpretation unverified; capture/layout evidence reported separately. PSA-RE bits 2.3-2.2. Heated rear window push button LED lighting request Upstream default raw=0 (not necessarily valid data).";
CM_ SG_ 551 SideTrajectoryMonitoringP_7717a7 "DATABASE_CANDIDATE: physical interpretation unverified; capture/layout evidence reported separately. PSA-RE bits 2.5-2.4. Side trajectory monitoring push button LED lighting request Upstream default raw=0 (not necessarily valid data).";
CM_ SG_ 551 AuxiliaryElectricBrakePus_1445da "DATABASE_CANDIDATE: physical interpretation unverified; capture/layout evidence reported separately. PSA-RE bits 2.7-2.6. Auxiliary electric brake push button LED lighting request Upstream default raw=0 (not necessarily valid data).";
CM_ SG_ 551 SportAmvarPushLedControl "DATABASE_CANDIDATE: physical interpretation unverified; capture/layout evidence reported separately. PSA-RE bits 1.1-1.0. Sport AMVAR push button LED lighting request Upstream default raw=0 (not necessarily valid data).";
CM_ SG_ 551 ChildLockPushLedControl "DATABASE_CANDIDATE: physical interpretation unverified; capture/layout evidence reported separately. PSA-RE bits 1.3-1.2. Child safety lock push button LED lighting request Upstream default raw=0 (not necessarily valid data).";
CM_ SG_ 551 EspPushLedControl "DATABASE_CANDIDATE: physical interpretation unverified; capture/layout evidence reported separately. PSA-RE bits 1.5-1.4. ESP push button LED lighting request Upstream default raw=0 (not necessarily valid data).";
CM_ SG_ 551 ParkingAidPushLedControl "DATABASE_CANDIDATE: physical interpretation unverified; capture/layout evidence reported separately. PSA-RE bits 1.7-1.6. AAS push button LED lighting request Upstream default raw=0 (not necessarily valid data).";
CM_ BO_ 552 "DATABASE_CANDIDATE: physical interpretation unverified; capture/layout evidence reported separately. INFO-DIV CAN, 125000 bit/s; CAN ID 0x228. PSA-RE title: EASY_MOVE_DATA. Adaptive cruise control and speed limiter display status and settings, sent by the BSI. Source: https://github.com/prototux/PSA-RE/blob/67f7581e7622410efdbb29c7eda3b86982b9b450/buses/AEE2010.full/LS.INFO-DIV/228.yml. Source sender alternatives: ICSV,BSI; physical TX/gateway forwarding not verified. Observed 587 frames in info_apka.csv,info_buzeni_obc.csv,info_charging.csv,info_standby.csv,info_start_jizda.csv,infocan.csv; DLCs [8]. ";
CM_ SG_ 552 CruiseSpeedProgrammingAut_3eaf80 "DATABASE_CANDIDATE: physical interpretation unverified; capture/layout evidence reported separately. PSA-RE bits 8.0. Authorization to program the speed from the speed-limit-sign (ILV) information Upstream default raw=0 (not necessarily valid data).";
CM_ SG_ 552 ColumnSwitchMemButtonStatus "DATABASE_CANDIDATE: physical interpretation unverified; capture/layout evidence reported separately. PSA-RE bits 8.1. MEM button state on the column switch Upstream default raw=0 (not necessarily valid data).";
CM_ SG_ 552 TivSetpointPageToggleRequest "DATABASE_CANDIDATE: physical interpretation unverified; capture/layout evidence reported separately. PSA-RE bits 8.3-8.2. TIV setpoint page open/close request Upstream default raw=0 (not necessarily valid data).";
CM_ SG_ 552 AdaptiveCruiseControlHmiStatus "DATABASE_CANDIDATE: physical interpretation unverified; capture/layout evidence reported separately. PSA-RE bits 8.7-8.4. adaptive cruise control (intelligent speed limiter) HMI status Upstream default raw=0 (not necessarily valid data).";
CM_ SG_ 552 AdaptiveCruiseControlSpee_17c8ea "DATABASE_CANDIDATE: physical interpretation unverified; capture/layout evidence reported separately. PSA-RE bits 6.6-7.0. Best-fit adaptive cruise control speed setpoint Raw invalid=32767; numeric DBC decoders may still scale it: check raw before use. Upstream default raw=0 (not necessarily valid data).";
CM_ SG_ 552 AccAutoHoldStatus "DATABASE_CANDIDATE: physical interpretation unverified; capture/layout evidence reported separately. PSA-RE bits 6.7. Vehicle standstill hold status from autonomous ACC braking Upstream default raw=0 (not necessarily valid data).";
CM_ SG_ 552 AccTivTimeSetpoint "DATABASE_CANDIDATE: physical interpretation unverified; capture/layout evidence reported separately. PSA-RE bits 5.5-5.0. TIV (time interval) setpoint Raw invalid=63; numeric DBC decoders may still scale it: check raw before use. Upstream default raw=62 (not necessarily valid data).";
CM_ SG_ 552 CruiseSetpointPageRequest "DATABASE_CANDIDATE: physical interpretation unverified; capture/layout evidence reported separately. PSA-RE bits 5.7-5.6. Cruise control setpoint page request Upstream default raw=0 (not necessarily valid data).";
CM_ SG_ 552 AccTivTime "DATABASE_CANDIDATE: physical interpretation unverified; capture/layout evidence reported separately. PSA-RE bits 4.5-4.0. TIV (time interval) value Raw invalid=63; numeric DBC decoders may still scale it: check raw before use. Upstream default raw=62 (not necessarily valid data).";
CM_ SG_ 552 AccTivSetpointAdjustmentStatus "DATABASE_CANDIDATE: physical interpretation unverified; capture/layout evidence reported separately. PSA-RE bits 4.6. TIV setpoint adjustment in progress Upstream default raw=0 (not necessarily valid data).";
CM_ SG_ 552 CruiseControlAvailable "DATABASE_CANDIDATE: physical interpretation unverified; capture/layout evidence reported separately. PSA-RE bits 4.7. Cruise control (XVV) availability Upstream default raw=0 (not necessarily valid data).";
CM_ SG_ 552 CruiseSpeedSetpointAdjust_cbc66f "DATABASE_CANDIDATE: physical interpretation unverified; capture/layout evidence reported separately. PSA-RE bits 3.0. Cruise control speed setpoint adjustment status Upstream default raw=0 (not necessarily valid data).";
CM_ SG_ 552 AccTargetPresence "DATABASE_CANDIDATE: physical interpretation unverified; capture/layout evidence reported separately. PSA-RE bits 3.1. Target presence Upstream default raw=0 (not necessarily valid data).";
CM_ SG_ 552 TentActLvvRvv "DATABASE_CANDIDATE: physical interpretation unverified; capture/layout evidence reported separately. PSA-RE bits 3.2. Attempt to activate the speed limiter/cruise control functions Upstream default raw=0 (not necessarily valid data).";
CM_ SG_ 552 EtatFonctLvvRvv "DATABASE_CANDIDATE: physical interpretation unverified; capture/layout evidence reported separately. PSA-RE bits 3.5-3.3. Active function status Upstream default raw=6 (not necessarily valid data).";
CM_ SG_ 552 FonctActLvvRvv "DATABASE_CANDIDATE: physical interpretation unverified; capture/layout evidence reported separately. PSA-RE bits 3.7-3.6. Active selection of the cruise control/speed limiter/ACC function Upstream default raw=0 (not necessarily valid data).";
CM_ SG_ 552 CruiseControlSpeed "DATABASE_CANDIDATE: physical interpretation unverified; capture/layout evidence reported separately. PSA-RE bits 1.7-2.0. speed limiter/cruise control speed setpoint Raw invalid=65535; numeric DBC decoders may still scale it: check raw before use. Upstream default raw=0 (not necessarily valid data).";
CM_ BO_ 553 "DATABASE_CANDIDATE: physical interpretation unverified; capture/layout evidence reported separately. INFO-DIV CAN, 125000 bit/s; CAN ID 0x229. PSA-RE title: GEARBOX_DYNAMIC_DATA_V2. Family of frames sharing this ID: the content depends on NAV_INFO_TYPE Source: https://github.com/prototux/PSA-RE/blob/67f7581e7622410efdbb29c7eda3b86982b9b450/buses/AEE2010.full/LS.INFO-DIV/229.yml. Source sender alternatives: ICSV,BTEL,OVIP; physical TX/gateway forwarding not verified. WIRE ISO-TP ONLY: normal addressing candidate, maximum Classical CAN DLC 8; actual DLC may be shorter. Data includes padding. No reassembly, text, DID or application-layer decoding. Original application layouts are preserved in source JSON; do not decode them at wire offsets. Unresolved alternative source layouts preserved in source JSON. ";
CM_ SG_ 553 FlowPadding5 "TRANSPORT_CANDIDATE: normal-addressing ISO-TP. PSA-RE bits 8.7-8.0. ";
CM_ SG_ 553 FirstData6 "TRANSPORT_CANDIDATE: normal-addressing ISO-TP. PSA-RE bits 8.7-8.0. ";
CM_ SG_ 553 UnknownData7 "TRANSPORT_CANDIDATE: normal-addressing ISO-TP. PSA-RE bits 8.7-8.0. ";
CM_ SG_ 553 ConsecutiveData7 "TRANSPORT_CANDIDATE: normal-addressing ISO-TP. PSA-RE bits 8.7-8.0. ";
CM_ SG_ 553 SingleData7 "TRANSPORT_CANDIDATE: normal-addressing ISO-TP. PSA-RE bits 8.7-8.0. ";
CM_ SG_ 553 FlowPadding4 "TRANSPORT_CANDIDATE: normal-addressing ISO-TP. PSA-RE bits 7.7-7.0. ";
CM_ SG_ 553 FirstData5 "TRANSPORT_CANDIDATE: normal-addressing ISO-TP. PSA-RE bits 7.7-7.0. ";
CM_ SG_ 553 UnknownData6 "TRANSPORT_CANDIDATE: normal-addressing ISO-TP. PSA-RE bits 7.7-7.0. ";
CM_ SG_ 553 ConsecutiveData6 "TRANSPORT_CANDIDATE: normal-addressing ISO-TP. PSA-RE bits 7.7-7.0. ";
CM_ SG_ 553 SingleData6 "TRANSPORT_CANDIDATE: normal-addressing ISO-TP. PSA-RE bits 7.7-7.0. ";
CM_ SG_ 553 FlowPadding3 "TRANSPORT_CANDIDATE: normal-addressing ISO-TP. PSA-RE bits 6.7-6.0. ";
CM_ SG_ 553 FirstData4 "TRANSPORT_CANDIDATE: normal-addressing ISO-TP. PSA-RE bits 6.7-6.0. ";
CM_ SG_ 553 UnknownData5 "TRANSPORT_CANDIDATE: normal-addressing ISO-TP. PSA-RE bits 6.7-6.0. ";
CM_ SG_ 553 ConsecutiveData5 "TRANSPORT_CANDIDATE: normal-addressing ISO-TP. PSA-RE bits 6.7-6.0. ";
CM_ SG_ 553 SingleData5 "TRANSPORT_CANDIDATE: normal-addressing ISO-TP. PSA-RE bits 6.7-6.0. ";
CM_ SG_ 553 FlowPadding2 "TRANSPORT_CANDIDATE: normal-addressing ISO-TP. PSA-RE bits 5.7-5.0. ";
CM_ SG_ 553 FirstData3 "TRANSPORT_CANDIDATE: normal-addressing ISO-TP. PSA-RE bits 5.7-5.0. ";
CM_ SG_ 553 UnknownData4 "TRANSPORT_CANDIDATE: normal-addressing ISO-TP. PSA-RE bits 5.7-5.0. ";
CM_ SG_ 553 ConsecutiveData4 "TRANSPORT_CANDIDATE: normal-addressing ISO-TP. PSA-RE bits 5.7-5.0. ";
CM_ SG_ 553 SingleData4 "TRANSPORT_CANDIDATE: normal-addressing ISO-TP. PSA-RE bits 5.7-5.0. ";
CM_ SG_ 553 FlowPadding1 "TRANSPORT_CANDIDATE: normal-addressing ISO-TP. PSA-RE bits 4.7-4.0. ";
CM_ SG_ 553 FirstData2 "TRANSPORT_CANDIDATE: normal-addressing ISO-TP. PSA-RE bits 4.7-4.0. ";
CM_ SG_ 553 UnknownData3 "TRANSPORT_CANDIDATE: normal-addressing ISO-TP. PSA-RE bits 4.7-4.0. ";
CM_ SG_ 553 ConsecutiveData3 "TRANSPORT_CANDIDATE: normal-addressing ISO-TP. PSA-RE bits 4.7-4.0. ";
CM_ SG_ 553 SingleData3 "TRANSPORT_CANDIDATE: normal-addressing ISO-TP. PSA-RE bits 4.7-4.0. ";
CM_ SG_ 553 FirstData1 "TRANSPORT_CANDIDATE: normal-addressing ISO-TP. PSA-RE bits 3.7-3.0. ";
CM_ SG_ 553 UnknownData2 "TRANSPORT_CANDIDATE: normal-addressing ISO-TP. PSA-RE bits 3.7-3.0. ";
CM_ SG_ 553 ConsecutiveData2 "TRANSPORT_CANDIDATE: normal-addressing ISO-TP. PSA-RE bits 3.7-3.0. ";
CM_ SG_ 553 SingleData2 "TRANSPORT_CANDIDATE: normal-addressing ISO-TP. PSA-RE bits 3.7-3.0. ";
CM_ SG_ 553 SeparationTimeRaw "TRANSPORT_CANDIDATE: normal-addressing ISO-TP. PSA-RE bits 3.7-3.0. Raw STmin code; 0xF1..0xF9 are not milliseconds.";
CM_ SG_ 553 UnknownData1 "TRANSPORT_CANDIDATE: normal-addressing ISO-TP. PSA-RE bits 2.7-2.0. ";
CM_ SG_ 553 ConsecutiveData1 "TRANSPORT_CANDIDATE: normal-addressing ISO-TP. PSA-RE bits 2.7-2.0. ";
CM_ SG_ 553 SingleData1 "TRANSPORT_CANDIDATE: normal-addressing ISO-TP. PSA-RE bits 2.7-2.0. ";
CM_ SG_ 553 BlockSize "TRANSPORT_CANDIDATE: normal-addressing ISO-TP. PSA-RE bits 2.7-2.0. ";
CM_ SG_ 553 UnknownPciLow "TRANSPORT_CANDIDATE: normal-addressing ISO-TP. PSA-RE bits 1.3-1.0. ";
CM_ SG_ 553 FlowStatus "TRANSPORT_CANDIDATE: normal-addressing ISO-TP. PSA-RE bits 1.3-1.0. ";
CM_ SG_ 553 ConsecutiveSequence "TRANSPORT_CANDIDATE: normal-addressing ISO-TP. PSA-RE bits 1.3-1.0. ";
CM_ SG_ 553 FirstFrameLength "TRANSPORT_CANDIDATE: normal-addressing ISO-TP. PSA-RE bits 1.3-2.0. 12-bit declared PDU length; not a reassembled value.";
CM_ SG_ 553 SingleFrameLength "TRANSPORT_CANDIDATE: normal-addressing ISO-TP. PSA-RE bits 1.3-1.0. Declared data length; not a validity check.";
CM_ SG_ 553 IsoTpFrameType "TRANSPORT_CANDIDATE: normal-addressing ISO-TP. PSA-RE bits 1.7-1.4. PCI high nibble; normal addressing candidate.";
CM_ BO_ 566 "DATABASE_CANDIDATE: physical interpretation unverified; capture/layout evidence reported separately. INFO-DIV CAN, 125000 bit/s; CAN ID 0x236. PSA-RE title: BSI_SLOW_DATA_3. AdBlue (urea) range and display request. Source: https://github.com/prototux/PSA-RE/blob/67f7581e7622410efdbb29c7eda3b86982b9b450/buses/AEE2010.full/LS.INFO-DIV/236.yml. Source sender alternatives: BSI; physical TX/gateway forwarding not verified. Observed 592 frames in info_apka.csv,info_buzeni_obc.csv,info_charging.csv,info_standby.csv,info_start_jizda.csv,infocan.csv; DLCs [8]. ";
CM_ SG_ 566 RearWindowStatus "DATABASE_CANDIDATE: physical interpretation unverified; capture/layout evidence reported separately. PSA-RE bits 8.0. Rear window status Upstream default raw=0 (not necessarily valid data).";
CM_ SG_ 566 PassengerDoorStatus "DATABASE_CANDIDATE: physical interpretation unverified; capture/layout evidence reported separately. PSA-RE bits 8.1. Front passenger door status Upstream default raw=0 (not necessarily valid data).";
CM_ SG_ 566 SttFunctionPresent "DATABASE_CANDIDATE: physical interpretation unverified; capture/layout evidence reported separately. PSA-RE bits 8.2. Status of Stop & Start function presence in the vehicle";
CM_ SG_ 566 DriverDoorEstimatedStatus "DATABASE_CANDIDATE: physical interpretation unverified; capture/layout evidence reported separately. PSA-RE bits 8.3. Estimated driver door opening state (used when the direct signal is presumed faulty) Upstream default raw=0 (not necessarily valid data).";
CM_ SG_ 566 RearLeftDoorStatus "DATABASE_CANDIDATE: physical interpretation unverified; capture/layout evidence reported separately. PSA-RE bits 8.4. Rear left door status Upstream default raw=0 (not necessarily valid data).";
CM_ SG_ 566 RearRightDoorStatus "DATABASE_CANDIDATE: physical interpretation unverified; capture/layout evidence reported separately. PSA-RE bits 8.5. Rear right door status Upstream default raw=0 (not necessarily valid data).";
CM_ SG_ 566 MuxFrontPanelPresence "DATABASE_CANDIDATE: physical interpretation unverified; capture/layout evidence reported separately. PSA-RE bits 8.6. Multimedia MUX front panel presence Upstream default raw=0 (not necessarily valid data).";
CM_ SG_ 566 RejectPowerOnInEco "DATABASE_CANDIDATE: physical interpretation unverified; capture/layout evidence reported separately. PSA-RE bits 8.7. Request to set to ON rejected (in economy mode) Upstream default raw=0 (not necessarily valid data).";
CM_ SG_ 566 TimeCounterResetCounter "DATABASE_CANDIDATE: physical interpretation unverified; capture/layout evidence reported separately. PSA-RE bits 7.7-7.0. Reset counter of the vehicle time counter (GCT); value 0xFE means unavailable Raw invalid=255; numeric DBC decoders may still scale it: check raw before use. Upstream default raw=254 (not necessarily valid data).";
CM_ SG_ 566 FaultLogContext "DATABASE_CANDIDATE: physical interpretation unverified; capture/layout evidence reported separately. PSA-RE bits 6.4-6.0. Fault log context information Upstream default raw=0 (not necessarily valid data).";
CM_ SG_ 566 BrakePedalSwitch "DATABASE_CANDIDATE: physical interpretation unverified; capture/layout evidence reported separately. PSA-RE bits 6.5. Main brake pedal switch state Upstream default raw=0 (not necessarily valid data).";
CM_ SG_ 566 DriverDoorStatus "DATABASE_CANDIDATE: physical interpretation unverified; capture/layout evidence reported separately. PSA-RE bits 6.6. Driver door opening state Upstream default raw=0 (not necessarily valid data).";
CM_ SG_ 566 TrunkStatus "DATABASE_CANDIDATE: physical interpretation unverified; capture/layout evidence reported separately. PSA-RE bits 6.7. Boot/trunk status Upstream default raw=0 (not necessarily valid data).";
CM_ SG_ 566 VehicleTimeCounter "DATABASE_CANDIDATE: physical interpretation unverified; capture/layout evidence reported separately. PSA-RE bits 2.7-5.0. Vehicle time counter; value 0xFFFFFFFE means unavailable Raw invalid=4294967295; numeric DBC decoders may still scale it: check raw before use. Upstream default raw=4294967294 (not necessarily valid data).";
CM_ SG_ 566 VehicleConfigMode "DATABASE_CANDIDATE: physical interpretation unverified; capture/layout evidence reported separately. PSA-RE bits 1.3-1.0. Vehicle configuration mode Upstream default raw=4 (not necessarily valid data).";
CM_ SG_ 566 ElectricalNetworkState "DATABASE_CANDIDATE: physical interpretation unverified; capture/layout evidence reported separately. PSA-RE bits 1.7-1.4. Vehicle electrical network state (nominal, degraded, available for start, starting, restarting) Upstream default raw=0 (not necessarily valid data).";
CM_ BO_ 579 "DATABASE_CANDIDATE: physical interpretation unverified; capture/layout evidence reported separately. INFO-DIV CAN, 125000 bit/s; CAN ID 0x243. PSA-RE title: ODI_BUFFER_FROM_TELEMATICS. Opaque data buffer of the embedded diagnostics interface (ODI) between the telematics unit and the diagnostic tool: data sent from the telematics unit. Source: https://github.com/prototux/PSA-RE/blob/67f7581e7622410efdbb29c7eda3b86982b9b450/buses/AEE2010.full/LS.INFO-DIV/243.yml. Source sender alternatives: MDS; physical TX/gateway forwarding not verified. ";
CM_ SG_ 579 OdiTelematicsToCenterstackBuffer "DATABASE_CANDIDATE: physical interpretation unverified; capture/layout evidence reported separately. PSA-RE bits 1.7-8.0. Open Display Interface (ODI) buffer, telematics unit to center stack display";
CM_ BO_ 596 "DATABASE_CANDIDATE: physical interpretation unverified; capture/layout evidence reported separately. INFO-DIV CAN, 125000 bit/s; CAN ID 0x254. PSA-RE title: REMOTE_ACTION_REQUEST. Remote-control request: horn, lights, lock/unlock or immobiliser. Source: https://github.com/prototux/PSA-RE/blob/67f7581e7622410efdbb29c7eda3b86982b9b450/buses/AEE2010.full/LS.INFO-DIV/254.yml. Source sender alternatives: MDS; physical TX/gateway forwarding not verified. WIRE ISO-TP ONLY: normal addressing candidate, maximum Classical CAN DLC 8; actual DLC may be shorter. Data includes padding. No reassembly, text, DID or application-layer decoding. Original application layouts are preserved in source JSON; do not decode them at wire offsets. ";
CM_ SG_ 596 FlowPadding5 "TRANSPORT_CANDIDATE: normal-addressing ISO-TP. PSA-RE bits 8.7-8.0. ";
CM_ SG_ 596 FirstData6 "TRANSPORT_CANDIDATE: normal-addressing ISO-TP. PSA-RE bits 8.7-8.0. ";
CM_ SG_ 596 UnknownData7 "TRANSPORT_CANDIDATE: normal-addressing ISO-TP. PSA-RE bits 8.7-8.0. ";
CM_ SG_ 596 ConsecutiveData7 "TRANSPORT_CANDIDATE: normal-addressing ISO-TP. PSA-RE bits 8.7-8.0. ";
CM_ SG_ 596 SingleData7 "TRANSPORT_CANDIDATE: normal-addressing ISO-TP. PSA-RE bits 8.7-8.0. ";
CM_ SG_ 596 FlowPadding4 "TRANSPORT_CANDIDATE: normal-addressing ISO-TP. PSA-RE bits 7.7-7.0. ";
CM_ SG_ 596 FirstData5 "TRANSPORT_CANDIDATE: normal-addressing ISO-TP. PSA-RE bits 7.7-7.0. ";
CM_ SG_ 596 UnknownData6 "TRANSPORT_CANDIDATE: normal-addressing ISO-TP. PSA-RE bits 7.7-7.0. ";
CM_ SG_ 596 ConsecutiveData6 "TRANSPORT_CANDIDATE: normal-addressing ISO-TP. PSA-RE bits 7.7-7.0. ";
CM_ SG_ 596 SingleData6 "TRANSPORT_CANDIDATE: normal-addressing ISO-TP. PSA-RE bits 7.7-7.0. ";
CM_ SG_ 596 FlowPadding3 "TRANSPORT_CANDIDATE: normal-addressing ISO-TP. PSA-RE bits 6.7-6.0. ";
CM_ SG_ 596 FirstData4 "TRANSPORT_CANDIDATE: normal-addressing ISO-TP. PSA-RE bits 6.7-6.0. ";
CM_ SG_ 596 UnknownData5 "TRANSPORT_CANDIDATE: normal-addressing ISO-TP. PSA-RE bits 6.7-6.0. ";
CM_ SG_ 596 ConsecutiveData5 "TRANSPORT_CANDIDATE: normal-addressing ISO-TP. PSA-RE bits 6.7-6.0. ";
CM_ SG_ 596 SingleData5 "TRANSPORT_CANDIDATE: normal-addressing ISO-TP. PSA-RE bits 6.7-6.0. ";
CM_ SG_ 596 FlowPadding2 "TRANSPORT_CANDIDATE: normal-addressing ISO-TP. PSA-RE bits 5.7-5.0. ";
CM_ SG_ 596 FirstData3 "TRANSPORT_CANDIDATE: normal-addressing ISO-TP. PSA-RE bits 5.7-5.0. ";
CM_ SG_ 596 UnknownData4 "TRANSPORT_CANDIDATE: normal-addressing ISO-TP. PSA-RE bits 5.7-5.0. ";
CM_ SG_ 596 ConsecutiveData4 "TRANSPORT_CANDIDATE: normal-addressing ISO-TP. PSA-RE bits 5.7-5.0. ";
CM_ SG_ 596 SingleData4 "TRANSPORT_CANDIDATE: normal-addressing ISO-TP. PSA-RE bits 5.7-5.0. ";
CM_ SG_ 596 FlowPadding1 "TRANSPORT_CANDIDATE: normal-addressing ISO-TP. PSA-RE bits 4.7-4.0. ";
CM_ SG_ 596 FirstData2 "TRANSPORT_CANDIDATE: normal-addressing ISO-TP. PSA-RE bits 4.7-4.0. ";
CM_ SG_ 596 UnknownData3 "TRANSPORT_CANDIDATE: normal-addressing ISO-TP. PSA-RE bits 4.7-4.0. ";
CM_ SG_ 596 ConsecutiveData3 "TRANSPORT_CANDIDATE: normal-addressing ISO-TP. PSA-RE bits 4.7-4.0. ";
CM_ SG_ 596 SingleData3 "TRANSPORT_CANDIDATE: normal-addressing ISO-TP. PSA-RE bits 4.7-4.0. ";
CM_ SG_ 596 FirstData1 "TRANSPORT_CANDIDATE: normal-addressing ISO-TP. PSA-RE bits 3.7-3.0. ";
CM_ SG_ 596 UnknownData2 "TRANSPORT_CANDIDATE: normal-addressing ISO-TP. PSA-RE bits 3.7-3.0. ";
CM_ SG_ 596 ConsecutiveData2 "TRANSPORT_CANDIDATE: normal-addressing ISO-TP. PSA-RE bits 3.7-3.0. ";
CM_ SG_ 596 SingleData2 "TRANSPORT_CANDIDATE: normal-addressing ISO-TP. PSA-RE bits 3.7-3.0. ";
CM_ SG_ 596 SeparationTimeRaw "TRANSPORT_CANDIDATE: normal-addressing ISO-TP. PSA-RE bits 3.7-3.0. Raw STmin code; 0xF1..0xF9 are not milliseconds.";
CM_ SG_ 596 UnknownData1 "TRANSPORT_CANDIDATE: normal-addressing ISO-TP. PSA-RE bits 2.7-2.0. ";
CM_ SG_ 596 ConsecutiveData1 "TRANSPORT_CANDIDATE: normal-addressing ISO-TP. PSA-RE bits 2.7-2.0. ";
CM_ SG_ 596 SingleData1 "TRANSPORT_CANDIDATE: normal-addressing ISO-TP. PSA-RE bits 2.7-2.0. ";
CM_ SG_ 596 BlockSize "TRANSPORT_CANDIDATE: normal-addressing ISO-TP. PSA-RE bits 2.7-2.0. ";
CM_ SG_ 596 UnknownPciLow "TRANSPORT_CANDIDATE: normal-addressing ISO-TP. PSA-RE bits 1.3-1.0. ";
CM_ SG_ 596 FlowStatus "TRANSPORT_CANDIDATE: normal-addressing ISO-TP. PSA-RE bits 1.3-1.0. ";
CM_ SG_ 596 ConsecutiveSequence "TRANSPORT_CANDIDATE: normal-addressing ISO-TP. PSA-RE bits 1.3-1.0. ";
CM_ SG_ 596 FirstFrameLength "TRANSPORT_CANDIDATE: normal-addressing ISO-TP. PSA-RE bits 1.3-2.0. 12-bit declared PDU length; not a reassembled value.";
CM_ SG_ 596 SingleFrameLength "TRANSPORT_CANDIDATE: normal-addressing ISO-TP. PSA-RE bits 1.3-1.0. Declared data length; not a validity check.";
CM_ SG_ 596 IsoTpFrameType "TRANSPORT_CANDIDATE: normal-addressing ISO-TP. PSA-RE bits 1.7-1.4. PCI high nibble; normal addressing candidate.";
CM_ BO_ 599 "DATABASE_CANDIDATE: physical interpretation unverified; capture/layout evidence reported separately. INFO-DIV CAN, 125000 bit/s; CAN ID 0x257. PSA-RE title: CMB_ODOMETER. Odometer value saved by the instrument cluster, transmitted three times in a row to protect the vehicle mileage integrity. Source: https://github.com/prototux/PSA-RE/blob/67f7581e7622410efdbb29c7eda3b86982b9b450/buses/AEE2010.full/LS.INFO-DIV/257.yml. Source sender alternatives: CMB; physical TX/gateway forwarding not verified. VEHICLE_SOURCE_REVIEW: Owner reports original instrument cluster unit004 connected for info_buzeni_obc.csv and absent in earlier captures. This ID is absent in info_standby.csv and fully operational info_start_jizda.csv; upstream lists CMB among possible senders. Owner approved limiting IC attribution to these nine messages. Scope: Vehicle-specific sender attribution from installation report/capture comparison and compatible source alias; does not validate signal meanings or exclude gateway forwarding. Observed 30 frames in info_buzeni_obc.csv,info_charging.csv; DLCs [6]. ";
CM_ SG_ 599 Secure "DATABASE_CANDIDATE: physical interpretation unverified; capture/layout evidence reported separately. PSA-RE bits 4.7-6.0. Security field protecting bytes 1 to 3";
CM_ SG_ 599 RearRightWheelSpeed "DATABASE_CANDIDATE: physical interpretation unverified; capture/layout evidence reported separately. PSA-RE bits 1.7-3.0. Odometer value saved in the instrument cluster, saved at least every 10 km (km) Raw invalid=16777215; numeric DBC decoders may still scale it: check raw before use.";
VAL_ 438 FlowStatus 0 "ContinueToSend" 1 "Wait" 2 "Overflow" ;
VAL_ 438 IsoTpFrameType 0 "SingleFrame" 1 "FirstFrame" 2 "ConsecutiveFrame" 3 "FlowControl" ;
VAL_ 464 FragranceSelection 0 "Unavailable" 1 "Perfume tank 1" 2 "Perfume tank 2" 3 "Perfume tank 3" ;
VAL_ 464 FragranceDiffuserState 0 "Off" 1 "On" ;
VAL_ 464 FragranceIntensity 0 "Unavailable" 1 "1" 2 "2" 3 "3" ;
VAL_ 471 LpaButtonPressed 0 "Not activated" 1 "Activated" ;
VAL_ 471 VehicleModeSelector 0 "Normal" 1 "Sport" 2 "Comfort" 3 "Eco" 4 "Sand" 5 "Mud" 6 "Snow" 7 "ZEV" 8 "EAWD" 9 "Hybrid" 10 "Manual" 11 "ZEV Eco mode" 12 "Hybrid Eco" 13 "Eco plus" ;
VAL_ 471 HadcButtonState 0 "Push button released" 1 "Push button pressed" ;
VAL_ 471 LkaButtonPressed 0 "Not activated" 1 "Activated" ;
VAL_ 475 CruiseMenuInfoAvailability 0 "Unavailable" 1 "Available" ;
VAL_ 475 Stop6SpeedValue 255 "Not_available" ;
VAL_ 476 EcocoachTripRangeGain 16383 "Not_available" ;
VAL_ 476 EcocoachGlobalTripScore 15 "Not_available" ;
VAL_ 476 EcocoachScoreStopStart 15 "Not_available" ;
VAL_ 476 EcocoachScoreSpeed 15 "Not_available" ;
VAL_ 476 EcocoachScoreSlope 15 "Not_available" ;
VAL_ 476 EcocoachScoreGsi 15 "Not_available" ;
VAL_ 476 EcocoachScoreTyrePressure 15 "Not_available" ;
VAL_ 476 EcocoachScoreColdEngine 15 "Not_available" ;
VAL_ 476 EcocoachScoreClimate 15 "Not_available" ;
VAL_ 476 EcocoachScoreBraking 15 "Not_available" ;
VAL_ 476 EcocoachScoreAcceleration 15 "Not_available" ;
VAL_ 480 NextListType 0 "No acess" 1 "Directory" 2 "Artist" 3 "Genre" 4 "Playlist" 5 "CD list" ;
VAL_ 480 DirectoryListOption 0 "Unavailable" 1 "no activation possible" 2 "Can be activated" ;
VAL_ 480 PlaylistListOption 0 "Unavailable" 1 "no activation possible" 2 "Can be activated" ;
VAL_ 480 GenreListOption 0 "Unavailable" 1 "no activation possible" 2 "Can be activated" ;
VAL_ 480 ArtistListOption 0 "Unavailable" 1 "no activation possible" 2 "Can be activated" ;
VAL_ 480 News7Option 0 "Option unavailable" 1 "Option cannot be activated" 2 "Option can be activated" ;
VAL_ 480 News6Option 0 "Option unavailable" 1 "Option cannot be activated" 2 "Option can be activated" ;
VAL_ 480 News5Option 0 "Option unavailable" 1 "Option cannot be activated" 2 "Option can be activated" ;
VAL_ 480 News4Option 0 "Option unavailable" 1 "Option cannot be activated" 2 "Option can be activated" ;
VAL_ 480 News3Option 0 "Option unavailable" 1 "Option cannot be activated" 2 "Option can be activated" ;
VAL_ 480 News2Option 0 "Option unavailable" 1 "Option cannot be activated" 2 "Option can be activated" ;
VAL_ 480 News1Option 0 "Option unavailable" 1 "Option cannot be activated" 2 "Option can be activated" ;
VAL_ 480 DabfmOption 0 "Option unavailable" 1 "Option cannot be activated" 2 "Option can be activated" ;
VAL_ 480 RadioNewsOption7Status 0 "Option not activated" 1 "Option activated" ;
VAL_ 480 RadioNewsOption6Status 0 "Option not activated" 1 "Option activated" ;
VAL_ 480 RadioNewsOption5Status 0 "Option not activated" 1 "Option activated" ;
VAL_ 480 RadioNewsOption4Status 0 "Option not activated" 1 "Option activated" ;
VAL_ 480 RadioNewsOption3Status 0 "Option not activated" 1 "Option activated" ;
VAL_ 480 RadioNewsOption2Status 0 "Option not activated" 1 "Option activated" ;
VAL_ 480 RadioNewsOption1Status 0 "Option not activated" 1 "Option activated" ;
VAL_ 480 RadioDabFmStatus 0 "Option not activated" 1 "Option activated" ;
VAL_ 480 RadioRdsAfStatus 0 "Option deactivated" 1 "Option activated" ;
VAL_ 480 RadioTextModeStatus 0 "Option deactivated" 1 "Option activated" ;
VAL_ 480 RadioTextOption 0 "Option unavailable" 1 "Option cannot be activated" 2 "Option can be activated" ;
VAL_ 480 RdsAfOption 0 "Option unavailable" 1 "Option cannot be activated" 2 "Option can be activated" ;
VAL_ 480 ShuffleModeStatus 0 "Option deactivated" 1 "Option activated" ;
VAL_ 480 ShuffleAllOption 0 "Unavailable" 1 "no activation possible" 2 "Can be activated" ;
VAL_ 480 CdTextModeStatus 0 "Option deactivated" 1 "Option activated" ;
VAL_ 480 CdTextOption 0 "Option unavailable" 1 "Option cannot be activated" 2 "Option can be activated" ;
VAL_ 480 RepeatEnabled 0 "Option deactivated" 1 "Option activated" ;
VAL_ 480 DiscRepeatOption 0 "Option unavailable" 1 "Option cannot be activated" 2 "Option can be activated" ;
VAL_ 480 RandomEnabled 0 "Option deactivated" 1 "Option activated" ;
VAL_ 480 TrackShuffleOption 0 "Option unavailable" 1 "Option cannot be activated" 2 "Option can be activated" ;
VAL_ 481 GeneralTpmsStatus 0 "Wheel pressures not monitored. Environment does not allow good reception" 1 "Wheel pressures not monitored, system problem" 2 "Tyre pressure unsuited to load" 3 "Wheel pressure inappropriate for the speed" 4 "In progress" 7 "OK" ;
VAL_ 481 RearRightWheelStatus 1 "Flat wheel" 2 "Wheel slightly deflated" 4 "Wheel strongly deflated" 8 "Wheel pressure not monitored" 16 "Normal pressure" ;
VAL_ 481 WheelDataUpdateBit 0 "Info not refreshed" 1 "Information refreshed" ;
VAL_ 481 RearLeftWheelStatus 1 "Flat wheel" 2 "Wheel slightly deflated" 4 "Wheel strongly deflated" 8 "Wheel pressure not monitored" 16 "Normal pressure" ;
VAL_ 481 FrontRightWheelStatus 1 "Flat wheel" 2 "Wheel slightly deflated" 4 "Wheel strongly deflated" 8 "Wheel pressure not monitored" 16 "Normal pressure" ;
VAL_ 481 FrontLeftWheelStatus 1 "Flat wheel" 2 "Wheel slightly deflated" 4 "Wheel strongly deflated" 8 "Wheel pressure not monitored" 16 "Normal pressure" ;
VAL_ 482 CurrentFileFormat 0 "None" 1 "Audio" 2 "MP3" 3 "WMA" 4 "AAC" 5 "Undetermined *" ;
VAL_ 482 CdcTrackChangeOrigin 0 "Automatic" 1 "Manual" ;
VAL_ 482 TrackElapsedSign 0 "Positive" 1 "Negative" ;
VAL_ 484 RseActive 0 "Off" 1 "On" ;
VAL_ 484 RseSourceButton2 0 "Deactivated" 1 "Activated" ;
VAL_ 484 RseAudioOutputAvailable 0 "Inalienable" 1 "Available" ;
VAL_ 484 RseEscButton 0 "Deactivated" 1 "Activated" ;
VAL_ 484 RseOkButton 0 "Deactivated" 1 "Activated" ;
VAL_ 484 RseArrowDownButton 0 "Deactivated" 1 "Activated" ;
VAL_ 484 RseArrowUpButton 0 "Deactivated" 1 "Activated" ;
VAL_ 484 RseArrowRightButton 0 "Deactivated" 1 "Activated" ;
VAL_ 484 RseArrowLeftButton 0 "Deactivated" 1 "Activated" ;
VAL_ 484 RseVolumeDownButton 0 "Deactivated" 1 "Activated" ;
VAL_ 484 RseVolumeUpButton 0 "Deactivated" 1 "Activated" ;
VAL_ 484 RseSourceButton 0 "Deactivated" 1 "Activated" ;
VAL_ 485 SpatialSettingStatus 0 "Not set" 1 "Setting ongoing" ;
VAL_ 485 SpectralSettingStatus 0 "Not set" 1 "Setting ongoing" ;
VAL_ 485 AudioAdjustmentImpossible 0 "No action" 1 "Setting not possible" ;
VAL_ 485 PredefinedDistribution 0 "Off" 1 "Driver" 2 "Surround" 3 "Unused value (011)" 4 "Value not used (100)" 5 "Value not used (101)" 6 "Value not used (110)" 7 "All passengers" ;
VAL_ 485 DistributionMenu 0 "Not set" 1 "Setting ongoing" ;
VAL_ 485 DistributionActivationStatus 0 "Option unavailable" 1 "Option cannot be activated" 2 "Option can be activated" ;
VAL_ 485 AmbianceMenu 0 "Not set" 1 "Setting ongoing" ;
VAL_ 485 AmbianceValue 0 "None (no longitudinal control)" 1 "Classic" 2 "Jazz Blues" 3 "Pop/Rock" 4 "Voice" 5 "Techno" ;
VAL_ 485 AmbianceActivationStatus 0 "Option unavailable" 1 "Option cannot be activated" 2 "Option can be activated" ;
VAL_ 485 SpeedVolumeControlActive 0 "Option unavailable" 1 "Option cannot be activated" 2 "Option can be activated" ;
VAL_ 485 AutoVolumeStatus 0 "Off" 1 "On" ;
VAL_ 485 AutoVolumeAdjustment 0 "Not set" 1 "Setting ongoing" ;
VAL_ 485 LoudnessValue 0 "Off" 1 "On" ;
VAL_ 485 LoudnessActivationStatus 0 "Option unavailable" 1 "Option cannot be activated" 2 "Option can be activated" ;
VAL_ 485 LoudnessMenu 0 "Not set" 1 "Setting ongoing" ;
VAL_ 485 TrebleActivationStatus 0 "Option unavailable" 1 "Option cannot be activated" 2 "Option can be activated" ;
VAL_ 485 TrebleMenu 0 "Not set" 1 "Setting ongoing" ;
VAL_ 485 BassActivationStatus 0 "Option unavailable" 1 "Option cannot be activated" 2 "Option can be activated" ;
VAL_ 485 BassMenu 0 "Not set" 1 "Setting ongoing" ;
VAL_ 485 FaderActive 0 "Option unavailable" 1 "Option cannot be activated" 2 "Option can be activated" ;
VAL_ 485 RearFrontBalancfMenu 0 "Not set" 1 "Setting ongoing" ;
VAL_ 485 BalanceActivationStatus 0 "Option unavailable" 1 "Option cannot be activated" 2 "Option can be activated" ;
VAL_ 485 LeftRightBalanceMenu 0 "Not set" 1 "Setting ongoing" ;
VAL_ 487 ZtepPowerRatio 63 "Not_available" ;
VAL_ 487 DaaLateralControlState 0 "Not operational" 1 "Operational" ;
VAL_ 487 LpaReadyWhenSelected 0 "Not ready" 1 "Ready" ;
VAL_ 487 LpaStateStatus 0 "Off" 1 "On fixed selected" 2 "On fixed active" 3 "On, fixed fault" ;
VAL_ 487 PlugIndicatorLampRequest 0 "No request" 1 "Fixed request" 2 "Flashing request" ;
VAL_ 487 LkaStateStatus 0 "Off" 1 "Lit steady, not ready" 2 "On, blinking" 3 "On steady, ready" ;
VAL_ 487 LkaLeftLineStatus 0 "Not selected" 1 "Not allowed" 2 "Allowed" 3 "Correction in progress" ;
VAL_ 487 LkaRightLineStatus 0 "Not selected" 1 "Not allowed" 2 "Allowed" 3 "Correction in progress" ;
VAL_ 487 DaaLateralControlLevel 0 "Unavailable" 1 "Level 1" 2 "Level 2" 3 "Level 3" 4 "Level 4" 5 "Level 5" 6 "Level 6" 7 "Level 7" 8 "Level 8" ;
VAL_ 487 HybridPowerTraction 511 "Not_available" ;
VAL_ 487 PowerBatteryHt 127 "Not_available" ;
VAL_ 487 TivTarget 255 "Not_available" ;
VAL_ 487 TivSetpoint 255 "Not_available" ;
VAL_ 487 ArtivTargetDetected 0 "Target not detected" 1 "Target detected" ;
VAL_ 487 ArtivAlertAdjustment 0 "No adjustment" 1 "Adjustment" ;
VAL_ 487 ArtivAlert 0 "No alert" 1 "Alert" ;
VAL_ 487 IhmArtivStatus 0 "Inappropriate speed" 1 "Active" 2 "Low visibility" 3 "Learning" ;
VAL_ 487 ArtivSelectionStatus 0 "Not selected" 1 "Selected" 2 "Selected but unavailable" 3 "Invalid" ;
VAL_ 488 SpeedLimitZone5State 0 "Function off" 1 "Function active" ;
VAL_ 488 SpeedLimitZone4State 0 "Function off" 1 "Function active" ;
VAL_ 488 SpeedLimitZone3State 0 "Function off" 1 "Function active" ;
VAL_ 488 SpeedLimitZone2State 0 "Function off" 1 "Function active" ;
VAL_ 488 SpeedLimitZone1State 0 "Function off" 1 "Function active" ;
VAL_ 488 CruiseLimiterProgramRecal_34492a 0 "No request" 1 "Requested" ;
VAL_ 488 SpeedLimitMainState 0 "Function off" 1 "Function active" ;
VAL_ 488 CruiseMenuInfoAvailability 0 "Unavailable" 1 "Available" ;
VAL_ 488 ThermalPrecondClock 2047 "Not_available" ;
VAL_ 488 ThermalPrecondActive 0 "Inactive" 1 "Active" ;
VAL_ 488 ThermalPrecondType 0 "Ventilation" 1 "Preheating" ;
VAL_ 488 CruiseLimiterProgramRecal_1d4300 0 "Info not refreshed" 1 "Information refreshed" ;
VAL_ 489 NextTrafficSlowdownDistance 255 "Not_available" ;
VAL_ 489 NextTrafficSlowdownDuration 255 "Not_available" ;
VAL_ 489 SpeedCameraPoiPictogram2 0 "No radar" 1 "Fixed radar" 2 "Red-light camera" 3 "Danger zone" 4 "Dangerous uphill" 5 "Dangerous downhill" 6 "Railway crossing not protected" 7 "Protected railway crossing" 8 "Black-spot pictogram" 10 "Radar stop" 11 "Mobile speed camera, very frequent" 12 "Frequent mobile speed camera" 13 "Mobile radar infrequent" 14 "Section radar" 15 "Level crossing" 16 "Restricted zone" 17 "Red light / speed camera" 18 "Multiple fixed speed camera" 19 "Mobile speed camera" 20 "Mobile speed camera detector connected" 21 "Fixed danger zone" 22 "Mobile danger zone" 23 "Certified mobile danger zone" 24 "Inter-distance camera" ;
VAL_ 489 SpeedDisplayAuthorization 0 "Display not authorized" 1 "Display authorized" ;
VAL_ 489 SpeedCameraPoiPictogram 0 "No radar" 1 "Fixed radar" 2 "Red-light camera" 3 "Danger zone" 4 "Dangerous uphill" 5 "Dangerous downhill" 6 "Railway crossing not protected" 7 "Protected railway crossing" 8 "Black-spot pictogram" 10 "Radar stop" 11 "Mobile speed camera, very frequent" 12 "Frequent mobile speed camera" 13 "Mobile radar infrequent" 14 "Section radar" 15 "Invalid" ;
VAL_ 489 AdvisedSpeed 255 "Not_available" ;
VAL_ 489 SpeedLimit 255 "Not_available" ;
VAL_ 526 SdcmPairingState 0 "Blank" 1 "Learned" ;
VAL_ 526 SdcmPrivateCodePairingState 0 "No response" 1 "Writing in progress" 2 "Write failure" 3 "Invalid request" 4 "Write complete, OK" ;
VAL_ 535 ClusterAppearance 255 "Not_available" ;
VAL_ 535 AmbientLightingLevel 0 "Level 0" 1 "Level 1" 2 "Level 2" 3 "Level 3" 4 "Level 4" 5 "Level 5" 6 "Level 6" 7 "Invalid" ;
VAL_ 535 AmbientLightButtonStatus 0 "Inhibited" 1 "Active" ;
VAL_ 535 MediaDisplayFault 0 "No fault detected" 1 "Failure detected" ;
VAL_ 535 DynamicModeChangeRequest 0 "No request" 1 "Requested" ;
VAL_ 535 EcoModeButtonPress 0 "No request" 1 "Requested" ;
VAL_ 535 SttButtonStatus 0 "Not activated" 1 "Activated" ;
VAL_ 535 SpeedDisplayedOnCmb 255 "Not_available" ;
VAL_ 535 ScpStateChangeRequest 0 "No request" 1 "Requested" ;
VAL_ 535 MediaDisplayFaultArc 0 "No fault detected" 1 "Failure detected" ;
VAL_ 535 ArtivMinusButtonStatus 0 "Not activated" 1 "Activated" ;
VAL_ 535 ArtivPlusButtonStatus 0 "Not activated" 1 "Activated" ;
VAL_ 535 MatrixMaintenanceResetRequest 0 "No request" 1 "Requested" ;
VAL_ 535 ArtivButtonStatus 0 "Not activated" 1 "Activated" ;
VAL_ 535 RequestPtcOn 0 "Not requested" 1 "Requested" ;
VAL_ 535 TpmsButtonInput 0 "Not activated" 1 "Activated" ;
VAL_ 535 ResetTotal2 0 "No request" 1 "Requested" ;
VAL_ 535 AcCompressorMaxCapacityRequest 0 "Not activated" 1 "Activated" ;
VAL_ 535 MpdButtonStatus 0 "Not activated" 1 "Activated" ;
VAL_ 535 SamButtonStatus 0 "Not activated" 1 "Activated" ;
VAL_ 535 RearWindowHeaterButtonStatus 0 "Not activated" 1 "Activated" ;
VAL_ 535 AcOnButtonStatus 0 "Not activated" 1 "Activated" ;
VAL_ 535 SideTrajectoryButtonStatus 0 "Not activated" 1 "Activated" ;
VAL_ 535 CafrButtonInput 0 "Not activated" 1 "Activated" ;
VAL_ 535 FilteredPartialStatus 0 "Not activated" 1 "Activated" ;
VAL_ 535 RequestMatrixCheck 0 "No request" 1 "Requested" ;
VAL_ 535 AmvarButtonStatus 0 "Not activated" 1 "Activated" ;
VAL_ 535 ChildSafetyLockStatus 0 "Not activated" 1 "Activated" ;
VAL_ 535 EspButtonStatus 0 "Not activated" 1 "Activated" ;
VAL_ 535 AasButtonStatus 0 "Not activated" 1 "Activated" ;
VAL_ 535 DistanceUnit 0 "Kilometre" 1 "miles" ;
VAL_ 535 ResetPartial 0 "Not requested" 1 "Requested" ;
VAL_ 535 ResetTotal1 0 "No request" 1 "Requested" ;
VAL_ 535 ClusterFault 0 "Fault absent" 1 "Fault present" ;
VAL_ 535 AutoCheck 0 "No automatic check request" 1 "Automatic check request" ;
VAL_ 535 CheckRequested 0 "Not in progress" 1 "In progress" ;
VAL_ 535 AirbagFaultStatus 0 "Not defined" 1 "Signalling" 2 "No signalling" 3 "Failure detected" ;
VAL_ 535 AirbagInhibitionStatus 0 "Not defined" 1 "Signalling" 2 "No signalling" 3 "Failure detected" ;
VAL_ 535 MaintenanceResetRequest 0 "Not requested" 1 "Requested" ;
VAL_ 535 DarkStatus 0 "Not requested" 1 "Requested" ;
VAL_ 539 AdsdActivationRequest 0 "Inactive" 1 "Active" ;
VAL_ 539 PrivacyModeSelection 0 "Fully private" 1 "Private geolocation" 2 "Not private" ;
VAL_ 539 PolychromeLightBlock1Acti_b37910 0 "Inactive" 1 "Active" ;
VAL_ 539 PolychromeLightColor1Selection 0 "Color 1" 1 "Color 2" 2 "Colour 3" 3 "Color 4" 4 "Colour 5" 5 "Colour 6" 6 "Colour 7" 7 "Color 8" ;
VAL_ 539 PolychromeLightAnimationS_c6fde1 0 "None (no longitudinal control)" 1 "Animation 1" 2 "Animation 2" 3 "Animation 3" 4 "Animation 4" 5 "Animation 5" 6 "Animation 6" 7 "Animation 7" 8 "Animation 8" 9 "Animation 9" 10 "Animation 10" 11 "Animation 11" 12 "Animation 12" 13 "Animation 13" 14 "Animation 14" 15 "Animation 15" ;
VAL_ 543 ListMinusButtonPress 0 "Command not activated" 1 "Command active" ;
VAL_ 543 ListPlusButtonPress 0 "Command not activated" 1 "Command active" ;
VAL_ 543 VoiceRecognitionButtonPress 0 "Command not activated" 1 "Command active" ;
VAL_ 543 SourceButtonPress 0 "Command not activated" 1 "Command activated" ;
VAL_ 543 RadioCommandValidation 0 "Command not activated" 1 "Command activated" ;
VAL_ 543 List 0 "Command not activated" 1 "Command activated" ;
VAL_ 543 Src 0 "Command not activated" 1 "Command activated" ;
VAL_ 543 VolDown 0 "Command not activated" 1 "Command activated" ;
VAL_ 543 VolUp 0 "Command not activated" 1 "Command activated" ;
VAL_ 543 OverflowScrollDown 0 "Normal" 1 "Counter - overflow info" ;
VAL_ 543 OverflowScrollUp 0 "Normal" 1 "Counter + overflow information" ;
VAL_ 543 SeekDown 0 "Command not activated" 1 "Command activated" ;
VAL_ 543 SeekUp 0 "Command not activated" 1 "Command activated" ;
VAL_ 544 AdsdFunctionActive 0 "Inactive" 1 "Active" ;
VAL_ 544 PrivacyModeStatus 0 "Fully private" 1 "Private geolocation" 2 "Not private" ;
VAL_ 544 PolychromePackBlock1Funct_d87010 0 "Inactive" 1 "Active" ;
VAL_ 544 PolychromePackColor1Status 0 "Color 1" 1 "Color 2" 2 "Colour 3" 3 "Color 4" 4 "Colour 5" 5 "Colour 6" 6 "Colour 7" 7 "Color 8" ;
VAL_ 544 PolychromePackAnimationIt_656116 0 "None (no longitudinal control)" 1 "Animation 1" 2 "Animation 2" 3 "Animation 3" 4 "Animation 4" 5 "Animation 5" 6 "Animation 6" 7 "Animation 7" 8 "Animation 8" 9 "Animation 9" 10 "Animation 10" 11 "Animation 11" 12 "Animation 12" 13 "Animation 13" 14 "Animation 14" 15 "Animation 15" ;
VAL_ 545 TripDistLeft 65535 "Not_available" ;
VAL_ 545 Autonomy 65535 "Not_available" ;
VAL_ 545 TripInstantFuelConsumption 65535 "Not_available" ;
VAL_ 545 NavigationPushButton 0 "Released" 1 "Pressed" ;
VAL_ 545 TripPushButton 0 "Released" 1 "Pressed" ;
VAL_ 545 SteeringWheelPageRotationStatus 0 "Command not activated" 1 "Command activated" ;
VAL_ 545 CheckAutonomy 0 "Valid" 1 "Invalid" ;
VAL_ 545 CheckConsumption 0 "Valid" 1 "Invalid" ;
VAL_ 547 AutoReply2Time 31 "Not_available" ;
VAL_ 547 AutoReply1Time 31 "Not_available" ;
VAL_ 547 SecondCallSeconds 63 "Not_available" ;
VAL_ 547 SecondCallMinutes 63 "Not_available" ;
VAL_ 547 SecondCallHours 31 "Not_available" ;
VAL_ 547 FirstCallSeconds 63 "Not_available" ;
VAL_ 547 FirstCallMinutes 63 "Not_available" ;
VAL_ 547 FirstCallHours 31 "Not_available" ;
VAL_ 548 AasBeepLevelAdjustment 0 "Not_available" ;
VAL_ 549 ListStatus 0 "Not active" 1 "In progress" ;
VAL_ 549 StationMemorizationStatus 0 "Not active" 1 "In progress" 2 "Validate" ;
VAL_ 549 EncodingFormat 0 "Invalid" 1 "MPEG1 layer II" 2 "MPEG2 ACC" 3 "MPEG4 ACC+" 4 "MPEG4 ER-BSAC" 5 "MPEG4 CELP" 6 "MPEG4 HVX C" 7 "SBR / PS-SBR" ;
VAL_ 549 StereoType 1 "Mono" 2 "Stereo" 3 "Joint stereo" 4 "Dual channel: 1" 5 "Double channel: 2" 7 "Invalid" ;
VAL_ 549 AudioStreamBitrate 1 "32 kbps" 2 "48 kbps" 3 "56 kbps" 4 "64 kbps" 5 "80 kbps" 6 "96 kbps" 7 "112 kbps" 8 "128 kbps" 9 "160 kbps" 10 "192 kbps" 11 "224 kbps" 12 "256 kbps" 13 "320 kbps" 14 "384 kbps" 15 "Invalid" ;
VAL_ 549 TunerLevel 255 "Not_available" ;
VAL_ 549 Frequency 2047 "Not_available" ;
VAL_ 549 Band 0 "Undetermined" 1 "FM1" 2 "FM2" 3 "DAB" 4 "FM autostore" 5 "MW (AM)" 6 "LW (AM)" 7 "Invalid" ;
VAL_ 549 SearchStatus 0 "Idle (listening)" 1 "Manual frequency search" 2 "Automatic frequency search" 3 "Station list update" 4 "TA announcement switch" 5 "AF switch" 8 "Frequency scan" 9 "Memory recall" 15 "No station found" ;
VAL_ 551 AvasSoundEmissionRequest 0 "No request" 1 "Requested" ;
VAL_ 551 EnergyRecoverPushLed 0 "Off" 1 "On" ;
VAL_ 551 AvasPushLed 0 "Off" 1 "On" ;
VAL_ 551 EcoModePushLedState 0 "Off" 1 "Steady on" 2 "On, blinking" 3 "Unused value (11)" ;
VAL_ 551 NightVisionPushLedControl 0 "Off" 1 "Steady on" 2 "On, blinking" 3 "Invalid" ;
VAL_ 551 LpaPushLedControl 0 "Off" 1 "Steady on" 2 "On, blinking" 3 "Invalid" ;
VAL_ 551 WelcomeLightLedMode 0 "Automatic" 1 "Manual" ;
VAL_ 551 AutoWipeLedFeedback 0 "Off" 1 "Steady on" 2 "On, blinking" 3 "Invalid" ;
VAL_ 551 HadcPushLedRequest 0 "No push led switch on requested" 1 "Push button LED on requested" ;
VAL_ 551 LkaPushLedControl 0 "Off" 1 "Steady on" 2 "On, blinking" 3 "Invalid" ;
VAL_ 551 FunctionSelectPushLed 0 "Off" 1 "On" 2 "Flashing" 3 "Invalid" ;
VAL_ 551 DynamicPackLedRequest 0 "Off" 1 "Steady on" 2 "On, blinking" ;
VAL_ 551 StartStopPushLedControl 0 "Off" 1 "Steady on" 2 "On, blinking" 3 "Invalid" ;
VAL_ 551 CafrPushLedControl 0 "Off" 1 "On" ;
VAL_ 551 ArtivPushLedControl 0 "Off" 1 "Steady on" 2 "On, blinking" 3 "Invalid" ;
VAL_ 551 RecyclAirEtVmf 0 "Command not activated" 1 "Command activated" ;
VAL_ 551 BlindSpotMonitoringPushLe_c23e79 0 "Off" 1 "Steady on" 2 "On, blinking" 3 "Invalid" ;
VAL_ 551 AirConditioningShutterControl 0 "Outside air" 1 "Partial recirculation" 2 "Full recirculation" 3 "Stop" ;
VAL_ 551 PetrolOrDieselInformation 0 "Petrol" 1 "Diesel" 3 "Invalid" ;
VAL_ 551 StopAndStartPushLedControl 0 "Off" 1 "Steady on" 2 "On, blinking" 3 "Invalid" ;
VAL_ 551 AcPushLedControl 0 "Off" 1 "Steady on" 2 "On, blinking" 3 "Invalid" ;
VAL_ 551 RearWindowHeatingPushLedControl 0 "Off" 1 "Steady on" 2 "On, blinking" 3 "Invalid" ;
VAL_ 551 SideTrajectoryMonitoringP_7717a7 0 "Off" 1 "Steady on" 2 "On, blinking" 3 "Invalid" ;
VAL_ 551 AuxiliaryElectricBrakePus_1445da 0 "Off" 1 "Steady on" 2 "On, blinking" 3 "Invalid" ;
VAL_ 551 SportAmvarPushLedControl 0 "Off" 1 "Steady on" 2 "On, blinking" 3 "Invalid" ;
VAL_ 551 ChildLockPushLedControl 0 "Off" 1 "Steady on" 2 "On, blinking" 3 "Invalid" ;
VAL_ 551 EspPushLedControl 0 "Off" 1 "Steady on" 2 "On, blinking" 3 "Invalid" ;
VAL_ 551 ParkingAidPushLedControl 0 "Off" 1 "Steady on" 2 "On, blinking" 3 "Invalid" ;
VAL_ 552 CruiseSpeedProgrammingAut_3eaf80 0 "Not allowed" 1 "Allowed" ;
VAL_ 552 ColumnSwitchMemButtonStatus 0 "No request" 1 "Requested" ;
VAL_ 552 TivSetpointPageToggleRequest 0 "No page-opening request" 1 "Page opening request" 2 "Page closing request" ;
VAL_ 552 AdaptiveCruiseControlHmiStatus 0 "No adaptive cruise control best fit adjustment" 1 "adaptive cruise control best fit in progress" 2 "adaptive cruise control best fit maximum" 3 "Best fit adaptive cruise control minimum speed" 4 "adaptive cruise control speed adjustment deactivated" 5 "Auto deactivation of cruise/limiter (i variant)" 6 "adaptive cruise control speed setpoint exceeded" 7 "Reduced radar visibility" 8 "Radar learning" 9 "RVVI deactivated" 10 "adaptive cruise control adjustment limit" ;
VAL_ 552 AdaptiveCruiseControlSpee_17c8ea 32767 "Not_available" ;
VAL_ 552 AccAutoHoldStatus 0 "No vehicle hold" 1 "Hold vehicle" ;
VAL_ 552 AccTivTimeSetpoint 63 "Not_available" ;
VAL_ 552 CruiseSetpointPageRequest 0 "Page closed" 1 "opening speed limiter page" 2 "Opening cruise control page" 3 "Invalid" ;
VAL_ 552 AccTivTime 63 "Not_available" ;
VAL_ 552 AccTivSetpointAdjustmentStatus 0 "No adjustment" 1 "Setting ongoing" ;
VAL_ 552 CruiseControlAvailable 0 "Not available" 1 "Available" ;
VAL_ 552 CruiseSpeedSetpointAdjust_cbc66f 0 "No adjustment" 1 "Adjustment" ;
VAL_ 552 AccTargetPresence 0 "Not present" 1 "Present" ;
VAL_ 552 TentActLvvRvv 0 "No new activation attempt" 1 "New activation attempt" ;
VAL_ 552 EtatFonctLvvRvv 0 "Standby" 1 "Activity without overspeeding" 2 "Limitation activated by the cruise control" 3 "Activity with overspeeding without pedal pick-up" 4 "Activity with overspeed on pedal pick-up" 6 "Function cannot be activated" 7 "Failure detected" ;
VAL_ 552 FonctActLvvRvv 0 "All functions OFF" 1 "Cruise control ON" 2 "Speed limiter ON" 3 "ACC ON" ;
VAL_ 552 CruiseControlSpeed 65535 "Not_available" ;
VAL_ 553 FlowStatus 0 "ContinueToSend" 1 "Wait" 2 "Overflow" ;
VAL_ 553 IsoTpFrameType 0 "SingleFrame" 1 "FirstFrame" 2 "ConsecutiveFrame" 3 "FlowControl" ;
VAL_ 566 RearWindowStatus 0 "Closed" 1 "Open" ;
VAL_ 566 PassengerDoorStatus 0 "Hard" 1 "Open" ;
VAL_ 566 SttFunctionPresent 0 "Absent" 1 "Present" ;
VAL_ 566 DriverDoorEstimatedStatus 0 "Hard" 1 "Open" ;
VAL_ 566 RearLeftDoorStatus 0 "Hard" 1 "Open" ;
VAL_ 566 RearRightDoorStatus 0 "Hard" 1 "Open" ;
VAL_ 566 MuxFrontPanelPresence 0 "Absent" 1 "Present" ;
VAL_ 566 RejectPowerOnInEco 0 "Not refused" 1 "Refused" ;
VAL_ 566 TimeCounterResetCounter 255 "Not_available" ;
VAL_ 566 BrakePedalSwitch 0 "Brake pedal released" 1 "Brake pedal pressed" ;
VAL_ 566 DriverDoorStatus 0 "Hard" 1 "Open" ;
VAL_ 566 TrunkStatus 0 "Hard" 1 "Open" ;
VAL_ 566 VehicleTimeCounter 4294967295 "Not_available" ;
VAL_ 566 VehicleConfigMode 0 "Fitting" 1 "Factory" 2 "Check" 3 "Storage / transport" 4 "Customer (normal)" 5 "Showroom mode" 6 "After-sales" 15 "Invalid" ;
VAL_ 566 ElectricalNetworkState 0 "Nominal torque interface" 1 "Degraded TI" 2 "Information availability request" 3 "Starting" 4 "Restart" 5 "Nominal" 6 "Degraded" 7 "Safe mode" 8 "Value not used (1000)" 9 "Value not used (1001)" 10 "Value not used (1010)" 11 "Value not used (1011)" 12 "Value not used (1100)" 13 "Unused value (1101)" 14 "Value not used (1110)" 15 "Value not used (1111)" ;
VAL_ 596 FlowStatus 0 "ContinueToSend" 1 "Wait" 2 "Overflow" ;
VAL_ 596 IsoTpFrameType 0 "SingleFrame" 1 "FirstFrame" 2 "ConsecutiveFrame" 3 "FlowControl" ;
VAL_ 599 RearRightWheelSpeed 16777215 "Not_available" ;
SG_MUL_VAL_ 438 SingleFrameLength IsoTpFrameType 0-0;
SG_MUL_VAL_ 438 FirstFrameLength IsoTpFrameType 1-1;
SG_MUL_VAL_ 438 ConsecutiveSequence IsoTpFrameType 2-2;
SG_MUL_VAL_ 438 FlowStatus IsoTpFrameType 3-3;
SG_MUL_VAL_ 438 UnknownPciLow IsoTpFrameType 4-15;
SG_MUL_VAL_ 438 BlockSize IsoTpFrameType 3-3;
SG_MUL_VAL_ 438 SingleData1 IsoTpFrameType 0-0;
SG_MUL_VAL_ 438 ConsecutiveData1 IsoTpFrameType 2-2;
SG_MUL_VAL_ 438 UnknownData1 IsoTpFrameType 4-15;
SG_MUL_VAL_ 438 SeparationTimeRaw IsoTpFrameType 3-3;
SG_MUL_VAL_ 438 SingleData2 IsoTpFrameType 0-0;
SG_MUL_VAL_ 438 ConsecutiveData2 IsoTpFrameType 2-2;
SG_MUL_VAL_ 438 UnknownData2 IsoTpFrameType 4-15;
SG_MUL_VAL_ 438 FirstData1 IsoTpFrameType 1-1;
SG_MUL_VAL_ 438 SingleData3 IsoTpFrameType 0-0;
SG_MUL_VAL_ 438 ConsecutiveData3 IsoTpFrameType 2-2;
SG_MUL_VAL_ 438 UnknownData3 IsoTpFrameType 4-15;
SG_MUL_VAL_ 438 FirstData2 IsoTpFrameType 1-1;
SG_MUL_VAL_ 438 FlowPadding1 IsoTpFrameType 3-3;
SG_MUL_VAL_ 438 SingleData4 IsoTpFrameType 0-0;
SG_MUL_VAL_ 438 ConsecutiveData4 IsoTpFrameType 2-2;
SG_MUL_VAL_ 438 UnknownData4 IsoTpFrameType 4-15;
SG_MUL_VAL_ 438 FirstData3 IsoTpFrameType 1-1;
SG_MUL_VAL_ 438 FlowPadding2 IsoTpFrameType 3-3;
SG_MUL_VAL_ 438 SingleData5 IsoTpFrameType 0-0;
SG_MUL_VAL_ 438 ConsecutiveData5 IsoTpFrameType 2-2;
SG_MUL_VAL_ 438 UnknownData5 IsoTpFrameType 4-15;
SG_MUL_VAL_ 438 FirstData4 IsoTpFrameType 1-1;
SG_MUL_VAL_ 438 FlowPadding3 IsoTpFrameType 3-3;
SG_MUL_VAL_ 438 SingleData6 IsoTpFrameType 0-0;
SG_MUL_VAL_ 438 ConsecutiveData6 IsoTpFrameType 2-2;
SG_MUL_VAL_ 438 UnknownData6 IsoTpFrameType 4-15;
SG_MUL_VAL_ 438 FirstData5 IsoTpFrameType 1-1;
SG_MUL_VAL_ 438 FlowPadding4 IsoTpFrameType 3-3;
SG_MUL_VAL_ 438 SingleData7 IsoTpFrameType 0-0;
SG_MUL_VAL_ 438 ConsecutiveData7 IsoTpFrameType 2-2;
SG_MUL_VAL_ 438 UnknownData7 IsoTpFrameType 4-15;
SG_MUL_VAL_ 438 FirstData6 IsoTpFrameType 1-1;
SG_MUL_VAL_ 438 FlowPadding5 IsoTpFrameType 3-3;
SG_MUL_VAL_ 553 SingleFrameLength IsoTpFrameType 0-0;
SG_MUL_VAL_ 553 FirstFrameLength IsoTpFrameType 1-1;
SG_MUL_VAL_ 553 ConsecutiveSequence IsoTpFrameType 2-2;
SG_MUL_VAL_ 553 FlowStatus IsoTpFrameType 3-3;
SG_MUL_VAL_ 553 UnknownPciLow IsoTpFrameType 4-15;
SG_MUL_VAL_ 553 BlockSize IsoTpFrameType 3-3;
SG_MUL_VAL_ 553 SingleData1 IsoTpFrameType 0-0;
SG_MUL_VAL_ 553 ConsecutiveData1 IsoTpFrameType 2-2;
SG_MUL_VAL_ 553 UnknownData1 IsoTpFrameType 4-15;
SG_MUL_VAL_ 553 SeparationTimeRaw IsoTpFrameType 3-3;
SG_MUL_VAL_ 553 SingleData2 IsoTpFrameType 0-0;
SG_MUL_VAL_ 553 ConsecutiveData2 IsoTpFrameType 2-2;
SG_MUL_VAL_ 553 UnknownData2 IsoTpFrameType 4-15;
SG_MUL_VAL_ 553 FirstData1 IsoTpFrameType 1-1;
SG_MUL_VAL_ 553 SingleData3 IsoTpFrameType 0-0;
SG_MUL_VAL_ 553 ConsecutiveData3 IsoTpFrameType 2-2;
SG_MUL_VAL_ 553 UnknownData3 IsoTpFrameType 4-15;
SG_MUL_VAL_ 553 FirstData2 IsoTpFrameType 1-1;
SG_MUL_VAL_ 553 FlowPadding1 IsoTpFrameType 3-3;
SG_MUL_VAL_ 553 SingleData4 IsoTpFrameType 0-0;
SG_MUL_VAL_ 553 ConsecutiveData4 IsoTpFrameType 2-2;
SG_MUL_VAL_ 553 UnknownData4 IsoTpFrameType 4-15;
SG_MUL_VAL_ 553 FirstData3 IsoTpFrameType 1-1;
SG_MUL_VAL_ 553 FlowPadding2 IsoTpFrameType 3-3;
SG_MUL_VAL_ 553 SingleData5 IsoTpFrameType 0-0;
SG_MUL_VAL_ 553 ConsecutiveData5 IsoTpFrameType 2-2;
SG_MUL_VAL_ 553 UnknownData5 IsoTpFrameType 4-15;
SG_MUL_VAL_ 553 FirstData4 IsoTpFrameType 1-1;
SG_MUL_VAL_ 553 FlowPadding3 IsoTpFrameType 3-3;
SG_MUL_VAL_ 553 SingleData6 IsoTpFrameType 0-0;
SG_MUL_VAL_ 553 ConsecutiveData6 IsoTpFrameType 2-2;
SG_MUL_VAL_ 553 UnknownData6 IsoTpFrameType 4-15;
SG_MUL_VAL_ 553 FirstData5 IsoTpFrameType 1-1;
SG_MUL_VAL_ 553 FlowPadding4 IsoTpFrameType 3-3;
SG_MUL_VAL_ 553 SingleData7 IsoTpFrameType 0-0;
SG_MUL_VAL_ 553 ConsecutiveData7 IsoTpFrameType 2-2;
SG_MUL_VAL_ 553 UnknownData7 IsoTpFrameType 4-15;
SG_MUL_VAL_ 553 FirstData6 IsoTpFrameType 1-1;
SG_MUL_VAL_ 553 FlowPadding5 IsoTpFrameType 3-3;
SG_MUL_VAL_ 596 SingleFrameLength IsoTpFrameType 0-0;
SG_MUL_VAL_ 596 FirstFrameLength IsoTpFrameType 1-1;
SG_MUL_VAL_ 596 ConsecutiveSequence IsoTpFrameType 2-2;
SG_MUL_VAL_ 596 FlowStatus IsoTpFrameType 3-3;
SG_MUL_VAL_ 596 UnknownPciLow IsoTpFrameType 4-15;
SG_MUL_VAL_ 596 BlockSize IsoTpFrameType 3-3;
SG_MUL_VAL_ 596 SingleData1 IsoTpFrameType 0-0;
SG_MUL_VAL_ 596 ConsecutiveData1 IsoTpFrameType 2-2;
SG_MUL_VAL_ 596 UnknownData1 IsoTpFrameType 4-15;
SG_MUL_VAL_ 596 SeparationTimeRaw IsoTpFrameType 3-3;
SG_MUL_VAL_ 596 SingleData2 IsoTpFrameType 0-0;
SG_MUL_VAL_ 596 ConsecutiveData2 IsoTpFrameType 2-2;
SG_MUL_VAL_ 596 UnknownData2 IsoTpFrameType 4-15;
SG_MUL_VAL_ 596 FirstData1 IsoTpFrameType 1-1;
SG_MUL_VAL_ 596 SingleData3 IsoTpFrameType 0-0;
SG_MUL_VAL_ 596 ConsecutiveData3 IsoTpFrameType 2-2;
SG_MUL_VAL_ 596 UnknownData3 IsoTpFrameType 4-15;
SG_MUL_VAL_ 596 FirstData2 IsoTpFrameType 1-1;
SG_MUL_VAL_ 596 FlowPadding1 IsoTpFrameType 3-3;
SG_MUL_VAL_ 596 SingleData4 IsoTpFrameType 0-0;
SG_MUL_VAL_ 596 ConsecutiveData4 IsoTpFrameType 2-2;
SG_MUL_VAL_ 596 UnknownData4 IsoTpFrameType 4-15;
SG_MUL_VAL_ 596 FirstData3 IsoTpFrameType 1-1;
SG_MUL_VAL_ 596 FlowPadding2 IsoTpFrameType 3-3;
SG_MUL_VAL_ 596 SingleData5 IsoTpFrameType 0-0;
SG_MUL_VAL_ 596 ConsecutiveData5 IsoTpFrameType 2-2;
SG_MUL_VAL_ 596 UnknownData5 IsoTpFrameType 4-15;
SG_MUL_VAL_ 596 FirstData4 IsoTpFrameType 1-1;
SG_MUL_VAL_ 596 FlowPadding3 IsoTpFrameType 3-3;
SG_MUL_VAL_ 596 SingleData6 IsoTpFrameType 0-0;
SG_MUL_VAL_ 596 ConsecutiveData6 IsoTpFrameType 2-2;
SG_MUL_VAL_ 596 UnknownData6 IsoTpFrameType 4-15;
SG_MUL_VAL_ 596 FirstData5 IsoTpFrameType 1-1;
SG_MUL_VAL_ 596 FlowPadding4 IsoTpFrameType 3-3;
SG_MUL_VAL_ 596 SingleData7 IsoTpFrameType 0-0;
SG_MUL_VAL_ 596 ConsecutiveData7 IsoTpFrameType 2-2;
SG_MUL_VAL_ 596 UnknownData7 IsoTpFrameType 4-15;
SG_MUL_VAL_ 596 FirstData6 IsoTpFrameType 1-1;
SG_MUL_VAL_ 596 FlowPadding5 IsoTpFrameType 3-3;
